VERSION ""

NS_ :

BS_:

BU_: Skylark_EV

BO_ 499 CCM_HU_Event_Info_Ack: 8 Vector__XXX
 SG_ CCmHuRearBlowerSwitchAck2 : 23|2@0+ (1,0) [0|3] ""  Skylark_EV
 SG_ CCmHuCtrlPnlSwitchAck : 8|1@0+ (1,0) [0|1] ""  Skylark_EV
 SG_ CCmHuExpressCoolSwitchAck : 9|1@0+ (1,0) [0|1] ""  Skylark_EV
 SG_ CCmHuRearBlowerSwitchAck : 10|1@0+ (1,0) [0|1] ""  Skylark_EV
 SG_ CCmHuFanSpdAck : 0|1@0+ (1,0) [0|1] ""  Skylark_EV
 SG_ CCmHuDistribSwitchAck : 1|1@0+ (1,0) [0|1] ""  Skylark_EV
 SG_ CCmHuMaxDefrstSwitchAck : 2|1@0+ (1,0) [0|1] ""  Skylark_EV
 SG_ CCmHuEconModeSwitchAck : 3|1@0+ (1,0) [0|1] ""  Skylark_EV
 SG_ CCmHuAutoSwitchAck : 4|1@0+ (1,0) [0|1] ""  Skylark_EV
 SG_ CCmHuRearDefogSwitchAck : 5|1@0+ (1,0) [0|1] ""  Skylark_EV
 SG_ CCmHuAirConCompSwitchAck : 6|1@0+ (1,0) [0|1] ""  Skylark_EV
 SG_ CCmHuErrAck : 7|1@0+ (1,0) [0|1] ""  Skylark_EV
 SG_ CCmHuTempWhlAck : 11|1@0+ (1,0) [0|1] ""  Skylark_EV
 SG_ CCmHuFreshAirRecircSwitchAck : 12|1@0+ (1,0) [0|1] ""  Skylark_EV
 SG_ CCmHuDualModeSwitchAck : 13|1@0+ (1,0) [0|1] ""  Skylark_EV
 SG_ CCmHuTempWhlPassAck : 14|1@0+ (1,0) [0|1] ""  Skylark_EV
 SG_ CCmHuTempWhlDrvrAck : 15|1@0+ (1,0) [0|1] ""  Skylark_EV

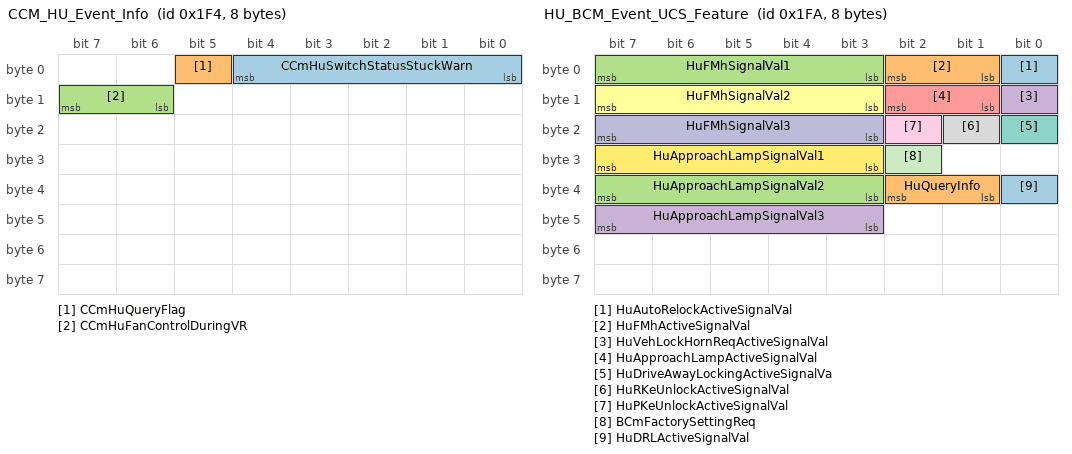
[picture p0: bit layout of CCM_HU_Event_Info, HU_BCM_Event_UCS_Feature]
BO_ 500 CCM_HU_Event_Info: 8 Vector__XXX
 SG_ CCmHuSwitchStatusStuckWarn : 4|5@0+ (1,0) [0|31] ""  Skylark_EV
 SG_ CCmHuQueryFlag : 5|1@0+ (1,0) [0|1] ""  Skylark_EV
 SG_ CCmHuFanControlDuringVR : 15|2@0+ (1,0) [0|3] ""  Skylark_EV

BO_ 504 BCM_HU_Event_UCS_Feature: 8 Vector__XXX
 SG_ BCmAutoRelockActiveSignalVal : 0|1@0+ (1,0) [0|1] ""  Skylark_EV
 SG_ BCmFMhActiveSignalVal : 2|2@0+ (1,0) [0|3] ""  Skylark_EV
 SG_ BCmFMhSignalVal1 : 7|5@0+ (10,0) [0|310] "Sec"  Skylark_EV
 SG_ BCmVehLockHornReqActiveSignalVal : 8|1@0+ (1,0) [0|1] ""  Skylark_EV
 SG_ BCmApproachLampActiveSignalVal : 10|2@0+ (1,0) [0|3] ""  Skylark_EV
 SG_ BCmFMhSignalVal2 : 15|5@0+ (10,0) [0|310] "Sec"  Skylark_EV
 SG_ BCmDriveAwayLockingActiveSignalV : 16|1@0+ (1,0) [0|1] ""  Skylark_EV
 SG_ BCmRKeUnlockState : 17|1@0+ (1,0) [0|1] ""  Skylark_EV
 SG_ BCmPKeUnlockState : 18|1@0+ (1,0) [0|1] ""  Skylark_EV
 SG_ BCmFMhSignalVal3 : 23|5@0+ (10,0) [0|310] "Sec"  Skylark_EV
 SG_ BCmAutoRelockState : 24|1@0+ (1,0) [0|1] ""  Skylark_EV
 SG_ BCmFMhState : 25|1@0+ (1,0) [0|1] ""  Skylark_EV
 SG_ BCmUCsState : 26|1@0+ (1,0) [0|1] ""  Skylark_EV
 SG_ BCmApproachLampSignalVal1 : 31|5@0+ (10,0) [0|310] "Sec"  Skylark_EV
 SG_ BCmPKeUnlockActiveSignalVal : 32|1@0+ (1,0) [0|1] ""  Skylark_EV
 SG_ BCmRKeUnlockActiveSignalVal : 33|1@0+ (1,0) [0|1] ""  Skylark_EV
 SG_ BCmDriveAwayLockingState : 34|1@0+ (1,0) [0|1] ""  Skylark_EV
 SG_ BCmApproachLampSignalVal2 : 39|5@0+ (10,0) [0|310] "Sec"  Skylark_EV
 SG_ AmbLightModeIllumOnHu : 40|1@0+ (1,0) [0|1] ""  Skylark_EV
 SG_ BCmApproachLampState : 41|1@0+ (1,0) [0|1] ""  Skylark_EV
 SG_ BCmVehLockHornReqState : 42|1@0+ (1,0) [0|1] ""  Skylark_EV
 SG_ BCmApproachLampSignalVal3 : 47|5@0+ (10,0) [0|310] "Sec"  Skylark_EV
 SG_ BCmDRLActiveSignalVal : 51|1@0+ (1,0) [0|1] ""  Skylark_EV
 SG_ BCmDRLState : 52|1@0+ (1,0) [0|1] ""  Skylark_EV
 SG_ BCmMoodLightState : 53|1@0+ (1,0) [0|1] ""  Skylark_EV
 SG_ BCmUcsData : 55|2@0+ (1,0) [0|3] ""  Skylark_EV

BO_ 505 BCM_HU_Event_Mood_Light_Feature: 8 Vector__XXX
 SG_ BCmMoodLightAllAreaActiveValue : 0|1@0+ (1,0) [0|1] ""  Skylark_EV
 SG_ BCmMoodLightIllumSelActiveVal : 3|3@0+ (1,0) [0|7] ""  Skylark_EV
 SG_ BCmMoodLightActiveColour : 7|4@0+ (1,0) [0|15] ""  Skylark_EV
 SG_ BCmMoodLightRearAreaActiveValue : 8|1@0+ (1,0) [0|1] ""  Skylark_EV
 SG_ BCmMoodLightFrontRHAreaActiveVal : 9|1@0+ (1,0) [0|1] ""  Skylark_EV
 SG_ BCmMoodLightFloorConsoleAreaActi : 10|1@0+ (1,0) [0|1] ""  Skylark_EV
 SG_ BCmMoodLightData : 12|2@0+ (1,0) [0|3] ""  Skylark_EV
 SG_ BCmMoodLightIllumPossibleLevels : 15|3@0+ (1,0) [0|7] ""  Skylark_EV
 SG_ BCmMoodLightHotMagentaColorSelOn : 16|1@0+ (1,0) [0|1] ""  Skylark_EV
 SG_ BCmMoodLightGoldYellowColorSelOn : 17|1@0+ (1,0) [0|1] ""  Skylark_EV
 SG_ BCmMoodLightFrenchLimeColorSelOn : 18|1@0+ (1,0) [0|1] ""  Skylark_EV
 SG_ BCmMoodLightFrontLHAreaActiveVal : 19|1@0+ (1,0) [0|1] ""  Skylark_EV
 SG_ BCmMoodLightPossibleModes : 21|2@0+ (1,0) [0|3] ""  Skylark_EV
 SG_ BCmMoodLightActiveModeValue : 23|2@0+ (1,0) [0|3] ""  Skylark_EV
 SG_ BCmMoodLightPolarBrightWhiteColo : 24|1@0+ (1,0) [0|1] ""  Skylark_EV
 SG_ BCmMoodLightAeroBlueColorSelOnHU : 25|1@0+ (1,0) [0|1] ""  Skylark_EV
 SG_ BCmMoodLightPurpleColorSelOnHU : 26|1@0+ (1,0) [0|1] ""  Skylark_EV
 SG_ BCmMoodLightFluorescentGreenColo : 27|1@0+ (1,0) [0|1] ""  Skylark_EV
 SG_ BCmMoodLightCyanBlueColorSelOnHU : 28|1@0+ (1,0) [0|1] ""  Skylark_EV
 SG_ BCmMoodLightCoolBlueColorSelOnHU : 29|1@0+ (1,0) [0|1] ""  Skylark_EV
 SG_ BCmMoodLightIvoryOFFWhiteColorSe : 30|1@0+ (1,0) [0|1] ""  Skylark_EV
 SG_ BCmMoodLightIceBlueColorSelOnHU : 31|1@0+ (1,0) [0|1] ""  Skylark_EV
 SG_ BCmMoodLightTuscanRedColorSelOnH : 32|1@0+ (1,0) [0|1] ""  Skylark_EV
 SG_ BCmMoodLightTealGreenColorSelOnH : 33|1@0+ (1,0) [0|1] ""  Skylark_EV
 SG_ BCmMoodLightRubyRedColorSelOnHU : 34|1@0+ (1,0) [0|1] ""  Skylark_EV
 SG_ BCmMoodLightOrangeColorSelOnHU : 35|1@0+ (1,0) [0|1] ""  Skylark_EV
 SG_ BCmMoodLightPurpleTaupeColorSelO : 36|1@0+ (1,0) [0|1] ""  Skylark_EV
 SG_ BCmMoodLightLocationSel : 37|1@0+ (1,0) [0|1] ""  Skylark_EV
 SG_ BCmMoodLightAllAreaSelOnHU : 38|1@0+ (1,0) [0|1] ""  Skylark_EV
 SG_ BCmMoodLightFrontLHAreaSelOnHU : 39|1@0+ (1,0) [0|1] ""  Skylark_EV
 SG_ BCmMoodLightRearAreaSelOnHU : 40|1@0+ (1,0) [0|1] ""  Skylark_EV
 SG_ BCmMoodLightFloorConsoleAreaSelO : 41|1@0+ (1,0) [0|1] ""  Skylark_EV
 SG_ BCmMoodLightState : 42|1@0+ (1,0) [0|1] ""  Skylark_EV
 SG_ BCmMoodLightFrontRHAreaSelOnHU : 43|1@0+ (1,0) [0|1] ""  Skylark_EV

BO_ 506 HU_BCM_Event_UCS_Feature: 8 Skylark_EV
 SG_ HuAutoRelockActiveSignalVal : 0|1@0+ (1,0) [0|1] "" Vector__XXX
 SG_ HuFMhActiveSignalVal : 2|2@0+ (1,0) [0|3] "" Vector__XXX
 SG_ HuFMhSignalVal1 : 7|5@0+ (10,0) [0|310] "Sec" Vector__XXX
 SG_ HuVehLockHornReqActiveSignalVal : 8|1@0+ (1,0) [0|1] "" Vector__XXX
 SG_ HuApproachLampActiveSignalVal : 10|2@0+ (1,0) [0|3] "" Vector__XXX
 SG_ HuFMhSignalVal2 : 15|5@0+ (10,0) [0|310] "Sec" Vector__XXX
 SG_ HuDriveAwayLockingActiveSignalVa : 16|1@0+ (1,0) [0|1] "" Vector__XXX
 SG_ HuRKeUnlockActiveSignalVal : 17|1@0+ (1,0) [0|1] "" Vector__XXX
 SG_ HuPKeUnlockActiveSignalVal : 18|1@0+ (1,0) [0|1] "" Vector__XXX
 SG_ HuFMhSignalVal3 : 23|5@0+ (10,0) [0|310] "Sec" Vector__XXX
 SG_ BCmFactorySettingReq : 26|1@0+ (1,0) [0|1] "" Vector__XXX
 SG_ HuApproachLampSignalVal1 : 31|5@0+ (10,0) [0|310] "Sec" Vector__XXX
 SG_ HuDRLActiveSignalVal : 32|1@0+ (1,0) [0|1] "" Vector__XXX
 SG_ HuQueryInfo : 34|2@0+ (1,0) [0|3] "" Vector__XXX
 SG_ HuApproachLampSignalVal2 : 39|5@0+ (10,0) [0|310] "Sec" Vector__XXX
 SG_ HuApproachLampSignalVal3 : 47|5@0+ (10,0) [0|310] "Sec" Vector__XXX

BO_ 508 HU_BCM_Event_Mood_Light_Feature: 8 Skylark_EV
 SG_ HuMoodLightAllAreaActiveValue : 0|1@0+ (1,0) [0|1] "" Vector__XXX
 SG_ HuMoodLightIllumSelActiveValue : 3|3@0+ (1,0) [0|7] "" Vector__XXX
 SG_ HuMoodLightActiveColourValue : 7|4@0+ (1,0) [0|15] "" Vector__XXX
 SG_ HuMoodLightRearAreaActiveValue : 8|1@0+ (1,0) [0|1] "" Vector__XXX
 SG_ HuMoodLightFrontRHAreaActiveValu : 9|1@0+ (1,0) [0|1] "" Vector__XXX
 SG_ HuMoodLightFloorConsoleAreaActiv : 10|1@0+ (1,0) [0|1] "" Vector__XXX
 SG_ HuMoodLightData : 12|2@0+ (1,0) [0|3] "" Vector__XXX
 SG_ HuMoodLightIllumPossibleLevels : 15|3@0+ (1,0) [0|7] "" Vector__XXX
 SG_ HuMoodLightHotMagentaColorSelOnH : 16|1@0+ (1,0) [0|1] "" Vector__XXX
 SG_ HuMoodLightGoldYellowColorSelOnH : 17|1@0+ (1,0) [0|1] "" Vector__XXX
 SG_ HuMoodLightFrenchLimeColorSelOnH : 18|1@0+ (1,0) [0|1] "" Vector__XXX
 SG_ HuMoodLightFrontLHAreaActiveValu : 19|1@0+ (1,0) [0|1] "" Vector__XXX
 SG_ HuMoodLightPossibleModes : 21|2@0+ (1,0) [0|3] "" Vector__XXX
 SG_ HuMoodLightActiveModeValue : 23|2@0+ (1,0) [0|3] "" Vector__XXX
 SG_ HuMoodLightPolarBrightWhiteColor : 24|1@0+ (1,0) [0|1] "" Vector__XXX
 SG_ HuMoodLightAeroBlueColorSelOnHU : 25|1@0+ (1,0) [0|1] "" Vector__XXX
 SG_ HuMoodLightPurpleColorSelOnHU : 26|1@0+ (1,0) [0|1] "" Vector__XXX
 SG_ HuMoodLightFluorescentGreenColor : 27|1@0+ (1,0) [0|1] "" Vector__XXX
 SG_ HuMoodLightCyanBlueColorSelOnHU : 28|1@0+ (1,0) [0|1] "" Vector__XXX
 SG_ HuMoodLightCoolBlueColorSelOnHU : 29|1@0+ (1,0) [0|1] "" Vector__XXX
 SG_ HuMoodLightIvoryOFFWhiteColorSel : 30|1@0+ (1,0) [0|1] "" Vector__XXX
 SG_ HuMoodLightIceBlueColorSelOnHU : 31|1@0+ (1,0) [0|1] "" Vector__XXX
 SG_ HuMoodLightTuscanRedColorSelOnHU : 32|1@0+ (1,0) [0|1] "" Vector__XXX
 SG_ HuMoodLightTealGreenColorSelOnHU : 33|1@0+ (1,0) [0|1] "" Vector__XXX
 SG_ HuMoodLightRubyRedColorSelOnHU : 34|1@0+ (1,0) [0|1] "" Vector__XXX
 SG_ HuMoodLightOrangeColorSelOnHU : 35|1@0+ (1,0) [0|1] "" Vector__XXX
 SG_ HuMoodLightPurpleTaupeSelOnHU : 36|1@0+ (1,0) [0|1] "" Vector__XXX

CM_ SG_ 499 CCmHuRearBlowerSwitchAck2 "Acknowledges the display update";
CM_ SG_ 499 CCmHuCtrlPnlSwitchAck "Acknowledges the display update";
CM_ SG_ 499 CCmHuExpressCoolSwitchAck "Acknowledges the display update";
CM_ SG_ 499 CCmHuRearBlowerSwitchAck "Acknowledges the display update";
CM_ SG_ 499 CCmHuFanSpdAck "Acknowledges the display update";
CM_ SG_ 499 CCmHuDistribSwitchAck "Acknowledges the display update";
CM_ SG_ 499 CCmHuMaxDefrstSwitchAck "Acknowledges the display update";
CM_ SG_ 499 CCmHuEconModeSwitchAck "Acknowledges the display update";
CM_ SG_ 499 CCmHuAutoSwitchAck "Acknowledges the display update";
CM_ SG_ 499 CCmHuRearDefogSwitchAck "Acknowledges the display update";
CM_ SG_ 499 CCmHuAirConCompSwitchAck "Acknowledges the display update";
CM_ SG_ 499 CCmHuErrAck "Acknowledges the display update";
CM_ SG_ 499 CCmHuTempWhlAck "Acknowledges the display update";
CM_ SG_ 499 CCmHuFreshAirRecircSwitchAck "Acknowledges the display update";
CM_ SG_ 499 CCmHuDualModeSwitchAck "Acknowledges the display update";
CM_ SG_ 499 CCmHuTempWhlPassAck "Acknowledges the display update";
CM_ SG_ 499 CCmHuTempWhlDrvrAck "Acknowledges the display update";
CM_ SG_ 500 CCmHuSwitchStatusStuckWarn "Indicates the button/s stuck status";
CM_ SG_ 500 CCmHuQueryFlag "Query the HU to send the missing frame";
CM_ SG_ 500 CCmHuFanControlDuringVR "To Control FAN speed during VR session";
CM_ SG_ 504 BCmAutoRelockActiveSignalVal "Active Value for Vehicle Auto Relock Feature";
CM_ SG_ 504 BCmFMhActiveSignalVal "Active value for Follow Me Home feature";
CM_ SG_ 504 BCmFMhSignalVal1 "1st Possible value for Follow Me Home Feature";
CM_ SG_ 504 BCmVehLockHornReqActiveSignalVal "Active Value for Vehicle Lock Horn Request feature";
CM_ SG_ 504 BCmApproachLampActiveSignalVal "Active value for Approach Lamp Active feature";
CM_ SG_ 504 BCmFMhSignalVal2 "2nd Possible value for Follow Me Home Feature";
CM_ SG_ 504 BCmDriveAwayLockingActiveSignalV "Active Value for Vehicle Drive Away Feature";
CM_ SG_ 504 BCmRKeUnlockState "Vehicle unlock with RKE Feature - Enable / Disable";
CM_ SG_ 504 BCmPKeUnlockState "Vehicle unlock with PKE Feature - Enable / Disable";
CM_ SG_ 504 BCmFMhSignalVal3 "3rd Possible value for Follow Me Home Feature";
CM_ SG_ 504 BCmAutoRelockState "Auto relock function Feature - Enable / Disable";
CM_ SG_ 504 BCmFMhState "Follow Me Home Feature - Enable / Disable";
CM_ SG_ 504 BCmUCsState "User customisation settings feature enable/disable parameter published by BCM";
CM_ SG_ 504 BCmApproachLampSignalVal1 "1st Possible value for Approach Lamp Feature";
CM_ SG_ 504 BCmPKeUnlockActiveSignalVal "Active Value for Vehicle Unlock with PKE Feature";
CM_ SG_ 504 BCmRKeUnlockActiveSignalVal "Active Value for Vehicle Unlock with RKE Feature";
CM_ SG_ 504 BCmDriveAwayLockingState "Drive away locking Feature - Enable / Disable";
CM_ SG_ 504 BCmApproachLampSignalVal2 "2nd Possible value for Approach Lamp Feature";
CM_ SG_ 504 AmbLightModeIllumOnHu "Mode and Illumination Display on HU send by BCM";
CM_ SG_ 504 BCmApproachLampState "Approach lamp Feature - Enable / Disable";
CM_ SG_ 504 BCmVehLockHornReqState "Horn request on vehicle lock Feature - Enable / Disable";
CM_ SG_ 504 BCmApproachLampSignalVal3 "3rd Possible value for Approach Lamp Feature";
CM_ SG_ 504 BCmDRLActiveSignalVal "Active Value for DRL Feature";
CM_ SG_ 504 BCmDRLState "DRL Feature - Enable / Disable";
CM_ SG_ 504 BCmMoodLightState "Current state of Mood Lighting from BCM to HU.";
CM_ SG_ 504 BCmUcsData "BCM sends UCS config data or give acknowledgement to HU.";
CM_ SG_ 505 BCmMoodLightAllAreaActiveValue "Current status of All area location selection from BCM to HU";
CM_ SG_ 505 BCmMoodLightIllumSelActiveVal "Current mood light illumination from BCM to HU";
CM_ SG_ 505 BCmMoodLightActiveColour "Mood light Active Colour from BCM to HU";
CM_ SG_ 505 BCmMoodLightRearAreaActiveValue "Current status of Rear area location selection from BCM to HU";
CM_ SG_ 505 BCmMoodLightFrontRHAreaActiveVal "Current status of driver area location selection from BCM to HU";
CM_ SG_ 505 BCmMoodLightFloorConsoleAreaActi "Current status of Floor area location selection from BCM to HU";
CM_ SG_ 505 BCmMoodLightData "BCM sends Mood light data frame or give acknowledgement to HU.";
CM_ SG_ 505 BCmMoodLightIllumPossibleLevels "Mood Light Number of illumination levels  to be displayed on HU send by BCM";
CM_ SG_ 505 BCmMoodLightHotMagentaColorSelOn "Mood light Hot Magenta colour selection on HU sent by BCM";
CM_ SG_ 505 BCmMoodLightGoldYellowColorSelOn "Mood light Gold Yellow colour selection on HU sent by BCM";
CM_ SG_ 505 BCmMoodLightFrenchLimeColorSelOn "Mood light French Lime colour selection on HU sent by BCM";
CM_ SG_ 505 BCmMoodLightFrontLHAreaActiveVal "Current status of co-driver area location selection from BCM to HU";
CM_ SG_ 505 BCmMoodLightPossibleModes "Mood light Possible Modes from BCM to HU";
CM_ SG_ 505 BCmMoodLightActiveModeValue "Mood light active mode from BCM to HU
";
CM_ SG_ 505 BCmMoodLightPolarBrightWhiteColo "Mood light polar colour selection on HU sent by BCM";
CM_ SG_ 505 BCmMoodLightAeroBlueColorSelOnHU "Mood light Aero Blue colour selection on HU sent by BCM";
CM_ SG_ 505 BCmMoodLightPurpleColorSelOnHU "Mood light purple colour selection on HU sent by BCM";
CM_ SG_ 505 BCmMoodLightFluorescentGreenColo "Mood lightFluroscent Green colour selection on HU sent by BCM";
CM_ SG_ 505 BCmMoodLightCyanBlueColorSelOnHU "Mood light Cyan Blue colour selection on HU sent by BCM";
CM_ SG_ 505 BCmMoodLightCoolBlueColorSelOnHU "Mood light Cool Blue color selection on HU sent by BCM";
CM_ SG_ 505 BCmMoodLightIvoryOFFWhiteColorSe "Mood light Ivory colour selection on HU sent by BCM";
CM_ SG_ 505 BCmMoodLightIceBlueColorSelOnHU "Mood light Ice Blue color selection on HU sent by BCM";
CM_ SG_ 505 BCmMoodLightTuscanRedColorSelOnH "Mood light Tuscan Red colour selection on HU sent by BCM";
CM_ SG_ 505 BCmMoodLightTealGreenColorSelOnH "Mood light Teal Green colour selection on HU sent by BCM";
CM_ SG_ 505 BCmMoodLightRubyRedColorSelOnHU "Mood light Ruby Red colour selection on HU sent by BCM";
CM_ SG_ 505 BCmMoodLightOrangeColorSelOnHU "Mood light Orange colour selection on HU sent by BCM";
CM_ SG_ 505 BCmMoodLightPurpleTaupeColorSelO "Mood light Purple Taupe colour selection on HU sent by BCM";
CM_ SG_ 505 BCmMoodLightLocationSel "Mood Lighting Location selection on HU";
CM_ SG_ 505 BCmMoodLightAllAreaSelOnHU "Mood Light All area location selection on HU send by BCM";
CM_ SG_ 505 BCmMoodLightFrontLHAreaSelOnHU "Mood Light co-driver area location selection on HU send by BCM";
CM_ SG_ 505 BCmMoodLightRearAreaSelOnHU "Mood Light Rear area location selection on HU send by BCM";
CM_ SG_ 505 BCmMoodLightFloorConsoleAreaSelO "Mood Light Floor Console area location selection on HU send by BCM";
CM_ SG_ 505 BCmMoodLightState "Current state of Mood Lighting from BCM to HU.";
CM_ SG_ 505 BCmMoodLightFrontRHAreaSelOnHU "Mood Light driver area location selection on HU send by BCM";
CM_ SG_ 506 HuAutoRelockActiveSignalVal "Active Value for Vehicle Auto Relock Feature";
CM_ SG_ 506 HuFMhActiveSignalVal "Active value for Follow Me Home feature";
CM_ SG_ 506 HuFMhSignalVal1 "1st Possible value for Follow Me Home Feature";
CM_ SG_ 506 HuVehLockHornReqActiveSignalVal "Active Value for Vehicle Lock Horn Request feature";
CM_ SG_ 506 HuApproachLampActiveSignalVal "Active value for Approach Lamp Active feature";
CM_ SG_ 506 HuFMhSignalVal2 "2ND Possible value for Follow Me Home Feature";
CM_ SG_ 506 HuDriveAwayLockingActiveSignalVa "Active Value for Vehicle Drive Away Feature";
CM_ SG_ 506 HuRKeUnlockActiveSignalVal "Active Value for Vehicle Unlock with RKE Feature";
CM_ SG_ 506 HuPKeUnlockActiveSignalVal "Active Value for Vehicle Unlock with PKE Feature";
CM_ SG_ 506 HuFMhSignalVal3 "3rd Possible value for Follow Me Home Feature";
CM_ SG_ 506 BCmFactorySettingReq "Request from HU to BCM to restore factory settings.";
CM_ SG_ 506 HuApproachLampSignalVal1 "1st Possible value for Approach Lamp Feature";
CM_ SG_ 506 HuDRLActiveSignalVal "Active Value for DRL  Feature";
CM_ SG_ 506 HuQueryInfo "HU ask BCM to send UCS values when not received after IGN ON.";
CM_ SG_ 506 HuApproachLampSignalVal2 "2nd Possible value for Approach Lamp Feature";
CM_ SG_ 506 HuApproachLampSignalVal3 "3rd Possible value for Approach Lamp Feature";
CM_ BO_ 508 "Event Message from HU to BCM for Mood Lighting feature";
CM_ SG_ 508 HuMoodLightAllAreaActiveValue "Current status of All area location selection from HU to BCM";
CM_ SG_ 508 HuMoodLightIllumSelActiveValue "Current Mood light illumination active value from HU to BCM";
CM_ SG_ 508 HuMoodLightActiveColourValue "Current Mood Light active value from HU to BCM";
CM_ SG_ 508 HuMoodLightRearAreaActiveValue "Current status of Rear area location selection from HU to BCM";
CM_ SG_ 508 HuMoodLightFrontRHAreaActiveValu "Current status of Driver area location selection from HU to BCM";
CM_ SG_ 508 HuMoodLightFloorConsoleAreaActiv "Current status of Floor Console area location selection from HU to BCM";
CM_ SG_ 508 HuMoodLightData "HU sends Mood Light Data frame or give acknowledgement to HU";
CM_ SG_ 508 HuMoodLightIllumPossibleLevels "Mood light number of illumination levels to be send by HU to BCM";
CM_ SG_ 508 HuMoodLightHotMagentaColorSelOnH "Mood light Hot Magenta colour selection on HU sent by HU";
CM_ SG_ 508 HuMoodLightGoldYellowColorSelOnH "Mood light Gold Yellow colour selection on HU sent by HU";
CM_ SG_ 508 HuMoodLightFrenchLimeColorSelOnH "Mood light French Lime colour selection on HU sent by HU";
CM_ SG_ 508 HuMoodLightFrontLHAreaActiveValu "Current status of Co-Driver area location selection from HU to BCM";
CM_ SG_ 508 HuMoodLightPossibleModes "Mood light possible modes from HU to BCM";
CM_ SG_ 508 HuMoodLightActiveModeValue "Mood light active mode from HU to BCM
";
CM_ SG_ 508 HuMoodLightPolarBrightWhiteColor "Mood light polar colour selection on HU sent by HU";
CM_ SG_ 508 HuMoodLightAeroBlueColorSelOnHU "Mood light Aero Blue colour selection on HU sent by HU";
CM_ SG_ 508 HuMoodLightPurpleColorSelOnHU "Mood light purple colour selection on HU sent by HU";
CM_ SG_ 508 HuMoodLightFluorescentGreenColor "Mood light Fluroscent colour selection on HU sent by HU";
CM_ SG_ 508 HuMoodLightCyanBlueColorSelOnHU "Mood light Cyan Blue colour selection on HU sent by HU";
CM_ SG_ 508 HuMoodLightCoolBlueColorSelOnHU "Mood light Cool Blue colour selection on HU sent by HU";
CM_ SG_ 508 HuMoodLightIvoryOFFWhiteColorSel "Mood light Ivory colour selection on HU sent by HU";
CM_ SG_ 508 HuMoodLightIceBlueColorSelOnHU "Mood light Ice Blue colour selection on HU sent by HU";
CM_ SG_ 508 HuMoodLightTuscanRedColorSelOnHU "Mood light Tuscan Red colour selection on HU sent by HU";
CM_ SG_ 508 HuMoodLightTealGreenColorSelOnHU "Mood light Teal Green colour selection on HU sent by HU";
CM_ SG_ 508 HuMoodLightRubyRedColorSelOnHU "Mood light ruby colour selection on HU sent by HU";
CM_ SG_ 508 HuMoodLightOrangeColorSelOnHU "Mood light Orange colour selection on HU sent by HU";
CM_ SG_ 508 HuMoodLightPurpleTaupeSelOnHU "Mood light Purple Taupe colour selection on HU sent by HU";
BA_DEF_ SG_  "Remarks" STRING ;
BA_DEF_ SG_  "NWM_WakeupAllowed" ENUM  "No","Yes";
BA_DEF_ SG_  "GenSigTimeoutTime_HU_Mid_X451" INT 0 65535;
BA_DEF_ SG_  "GenSigTimeoutTime_HU_High_X451" INT 0 65535;
BA_DEF_ SG_  "GenSigTimeoutTime_HU_B" INT 0 65535;
BA_DEF_ SG_  "GenSigTimeoutTime_HU_A" INT 0 65535;
BA_DEF_ SG_  "GenSigTimeoutTime_BCM_Mid" INT 0 65535;
BA_DEF_ SG_  "GenSigTimeoutMsg_HU_Mid_X451" INT 0 65535;
BA_DEF_ SG_  "GenSigTimeoutMsg_HU_High_X451" INT 0 65535;
BA_DEF_ SG_  "GenSigTimeoutMsg_HU_B" INT 0 65535;
BA_DEF_ SG_  "GenSigTimeoutMsg_HU_A" INT 0 65535;
BA_DEF_ SG_  "GenSigStartValue" INT 0 0;
BA_DEF_ SG_  "GenSigSendType" ENUM  "Cyclic","OnWrite","OnWriteWithRepetition","OnChange","OnChangeWithRepetition","IfActive","IfActiveWithRepetition","NoSigSendType","NotUsed","NotUsed","NotUsed","NotUsed","NotUsed";
BA_DEF_ SG_  "GenSigInactiveValue" INT 0 0;
BA_DEF_ SG_  "GenSigEnvVarType" ENUM  "int","float","undef";
BA_DEF_ SG_  "GenSigCycleTimeActive" INT 0 0;
BA_DEF_ SG_  "GenSigCycleTime" INT 0 0;
BA_DEF_ SG_  "GenSigTimeoutMsg_HU_High_X445" INT 0 65535;
BA_DEF_ SG_  "GenSigTimeoutMsg_HU_Mid_X445" INT 0 65535;
BA_DEF_ SG_  "GenSigTimeoutTime_HU_High_X445" INT 0 65535;
BA_DEF_ SG_  "GenSigTimeoutTime_HU_Mid_X445" INT 0 65535;
BA_DEF_ SG_  "GenSigTimeoutMsg_IVI" INT 0 65535;
BA_DEF_ SG_  "GenSigTimeoutTime_IVI" INT 0 65535;
BA_DEF_ BO_  "NmMessage" ENUM  "no","yes";
BA_DEF_ BO_  "NmAsrMessage" ENUM  "<n.a.>","No","Yes";
BA_DEF_ BO_  "MessageTimeout" INT 0 65535;
BA_DEF_ BO_  "GenMsgStartDelayTime" INT 0 0;
BA_DEF_ BO_  "GenMsgSendType" ENUM  "Cyclic","NotUsed","NotUsed","NotUsed","NotUsed","NotUsed","NotUsed","IfActive","NoMsgSendType","NotUsed";
BA_DEF_ BO_  "GenMsgNrOfRepetition" INT 0 0;
BA_DEF_ BO_  "GenMsgILSupport" ENUM  "No","Yes";
BA_DEF_ BO_  "GenMsgDelayTime" INT 0 0;
BA_DEF_ BO_  "GenMsgCycleTimeFast" INT 0 0;
BA_DEF_ BO_  "GenMsgCycleTime" INT 0 0;
BA_DEF_ BO_  "DiagUudtResponse" ENUM  "false","true";
BA_DEF_ BO_  "DiagUsdtResponse" ENUM  "false","true";
BA_DEF_ BO_  "DiagState" ENUM  "No","Yes";
BA_DEF_ BO_  "DiagResponse" ENUM  "No","Yes";
BA_DEF_ BO_  "DiagRequest" ENUM  "No","Yes";
BA_DEF_ BO_  "MsgType" ENUM  "Application","NM","NMH";
BA_DEF_ SG_  "SystemSignalLongSymbol" STRING ;
BA_DEF_DEF_  "Remarks" "null";
BA_DEF_DEF_  "NWM_WakeupAllowed" "No";
BA_DEF_DEF_  "GenSigTimeoutTime_HU_Mid_X451" 500;
BA_DEF_DEF_  "GenSigTimeoutTime_HU_High_X451" 500;
BA_DEF_DEF_  "GenSigTimeoutTime_HU_B" 500;
BA_DEF_DEF_  "GenSigTimeoutTime_HU_A" 500;
BA_DEF_DEF_  "GenSigTimeoutTime_BCM_Mid" 0;
BA_DEF_DEF_  "GenSigTimeoutMsg_HU_Mid_X451" 500;
BA_DEF_DEF_  "GenSigTimeoutMsg_HU_High_X451" 500;
BA_DEF_DEF_  "GenSigTimeoutMsg_HU_B" 500;
BA_DEF_DEF_  "GenSigTimeoutMsg_HU_A" 500;
BA_DEF_DEF_  "GenSigStartValue" 0;
BA_DEF_DEF_  "GenSigSendType" "Cyclic";
BA_DEF_DEF_  "GenSigInactiveValue" 0;
BA_DEF_DEF_  "GenSigEnvVarType" "undef";
BA_DEF_DEF_  "GenSigCycleTimeActive" 0;
BA_DEF_DEF_  "GenSigCycleTime" 0;
BA_DEF_DEF_  "GenSigTimeoutMsg_HU_High_X445" 500;
BA_DEF_DEF_  "GenSigTimeoutMsg_HU_Mid_X445" 500;
BA_DEF_DEF_  "GenSigTimeoutTime_HU_High_X445" 500;
BA_DEF_DEF_  "GenSigTimeoutTime_HU_Mid_X445" 500;
BA_DEF_DEF_  "GenSigTimeoutMsg_IVI" 500;
BA_DEF_DEF_  "GenSigTimeoutTime_IVI" 500;
BA_DEF_DEF_  "NmMessage" "no";
BA_DEF_DEF_  "NmAsrMessage" "<n.a.>";
BA_DEF_DEF_  "MessageTimeout" 500;
BA_DEF_DEF_  "GenMsgStartDelayTime" 0;
BA_DEF_DEF_  "GenMsgSendType" "Cyclic";
BA_DEF_DEF_  "GenMsgNrOfRepetition" 0;
BA_DEF_DEF_  "GenMsgILSupport" "Yes";
BA_DEF_DEF_  "GenMsgDelayTime" 0;
BA_DEF_DEF_  "GenMsgCycleTimeFast" 0;
BA_DEF_DEF_  "GenMsgCycleTime" 0;
BA_DEF_DEF_  "DiagUudtResponse" "false";
BA_DEF_DEF_  "DiagUsdtResponse" "false";
BA_DEF_DEF_  "DiagState" "No";
BA_DEF_DEF_  "DiagResponse" "No";
BA_DEF_DEF_  "DiagRequest" "No";
BA_DEF_DEF_  "MsgType" "Application";
BA_DEF_DEF_  "SystemSignalLongSymbol" "";
BA_ "MessageTimeout" BO_ 499 0;
BA_ "GenMsgSendType" BO_ 499 8;
BA_ "MessageTimeout" BO_ 500 0;
BA_ "GenMsgSendType" BO_ 500 8;
BA_ "MessageTimeout" BO_ 504 0;
BA_ "GenMsgSendType" BO_ 504 8;
BA_ "MessageTimeout" BO_ 505 0;
BA_ "GenMsgSendType" BO_ 505 8;
BA_ "MessageTimeout" BO_ 506 0;
BA_ "GenMsgSendType" BO_ 506 8;
BA_ "MessageTimeout" BO_ 508 0;
BA_ "GenMsgSendType" BO_ 508 8;
BA_ "GenSigTimeoutTime_HU_Mid_X451" SG_ 499 CCmHuRearBlowerSwitchAck2 0;
BA_ "GenSigTimeoutTime_HU_High_X451" SG_ 499 CCmHuRearBlowerSwitchAck2 0;
BA_ "GenSigTimeoutTime_HU_B" SG_ 499 CCmHuRearBlowerSwitchAck2 0;
BA_ "GenSigTimeoutTime_HU_A" SG_ 499 CCmHuRearBlowerSwitchAck2 0;
BA_ "GenSigTimeoutMsg_HU_Mid_X451" SG_ 499 CCmHuRearBlowerSwitchAck2 0;
BA_ "GenSigTimeoutMsg_HU_High_X451" SG_ 499 CCmHuRearBlowerSwitchAck2 0;
BA_ "GenSigTimeoutMsg_HU_B" SG_ 499 CCmHuRearBlowerSwitchAck2 0;
BA_ "GenSigTimeoutMsg_HU_A" SG_ 499 CCmHuRearBlowerSwitchAck2 0;
BA_ "GenSigSendType" SG_ 499 CCmHuRearBlowerSwitchAck2 1;
BA_ "GenSigTimeoutMsg_HU_High_X445" SG_ 499 CCmHuRearBlowerSwitchAck2 0;
BA_ "GenSigTimeoutMsg_HU_Mid_X445" SG_ 499 CCmHuRearBlowerSwitchAck2 0;
BA_ "GenSigTimeoutTime_HU_High_X445" SG_ 499 CCmHuRearBlowerSwitchAck2 0;
BA_ "GenSigTimeoutTime_HU_Mid_X445" SG_ 499 CCmHuRearBlowerSwitchAck2 0;
BA_ "GenSigTimeoutMsg_IVI" SG_ 499 CCmHuRearBlowerSwitchAck2 0;
BA_ "GenSigTimeoutTime_IVI" SG_ 499 CCmHuRearBlowerSwitchAck2 0;
BA_ "GenSigTimeoutTime_HU_Mid_X451" SG_ 499 CCmHuCtrlPnlSwitchAck 0;
BA_ "GenSigTimeoutTime_HU_High_X451" SG_ 499 CCmHuCtrlPnlSwitchAck 0;
BA_ "GenSigTimeoutTime_HU_B" SG_ 499 CCmHuCtrlPnlSwitchAck 0;
BA_ "GenSigTimeoutTime_HU_A" SG_ 499 CCmHuCtrlPnlSwitchAck 0;
BA_ "GenSigTimeoutMsg_HU_Mid_X451" SG_ 499 CCmHuCtrlPnlSwitchAck 0;
BA_ "GenSigTimeoutMsg_HU_High_X451" SG_ 499 CCmHuCtrlPnlSwitchAck 0;
BA_ "GenSigTimeoutMsg_HU_B" SG_ 499 CCmHuCtrlPnlSwitchAck 0;
BA_ "GenSigTimeoutMsg_HU_A" SG_ 499 CCmHuCtrlPnlSwitchAck 0;
BA_ "GenSigSendType" SG_ 499 CCmHuCtrlPnlSwitchAck 1;
BA_ "GenSigTimeoutMsg_HU_High_X445" SG_ 499 CCmHuCtrlPnlSwitchAck 0;
BA_ "GenSigTimeoutMsg_HU_Mid_X445" SG_ 499 CCmHuCtrlPnlSwitchAck 0;
BA_ "GenSigTimeoutTime_HU_High_X445" SG_ 499 CCmHuCtrlPnlSwitchAck 0;
BA_ "GenSigTimeoutTime_HU_Mid_X445" SG_ 499 CCmHuCtrlPnlSwitchAck 0;
BA_ "GenSigTimeoutMsg_IVI" SG_ 499 CCmHuCtrlPnlSwitchAck 0;
BA_ "GenSigTimeoutTime_IVI" SG_ 499 CCmHuCtrlPnlSwitchAck 0;
BA_ "GenSigTimeoutTime_HU_Mid_X451" SG_ 499 CCmHuExpressCoolSwitchAck 0;
BA_ "GenSigTimeoutTime_HU_High_X451" SG_ 499 CCmHuExpressCoolSwitchAck 0;
BA_ "GenSigTimeoutTime_HU_B" SG_ 499 CCmHuExpressCoolSwitchAck 0;
BA_ "GenSigTimeoutTime_HU_A" SG_ 499 CCmHuExpressCoolSwitchAck 0;
BA_ "GenSigTimeoutMsg_HU_Mid_X451" SG_ 499 CCmHuExpressCoolSwitchAck 0;
BA_ "GenSigTimeoutMsg_HU_High_X451" SG_ 499 CCmHuExpressCoolSwitchAck 0;
BA_ "GenSigTimeoutMsg_HU_B" SG_ 499 CCmHuExpressCoolSwitchAck 0;
BA_ "GenSigTimeoutMsg_HU_A" SG_ 499 CCmHuExpressCoolSwitchAck 0;
BA_ "GenSigSendType" SG_ 499 CCmHuExpressCoolSwitchAck 1;
BA_ "GenSigTimeoutMsg_HU_High_X445" SG_ 499 CCmHuExpressCoolSwitchAck 0;
BA_ "GenSigTimeoutMsg_HU_Mid_X445" SG_ 499 CCmHuExpressCoolSwitchAck 0;
BA_ "GenSigTimeoutTime_HU_High_X445" SG_ 499 CCmHuExpressCoolSwitchAck 0;
BA_ "GenSigTimeoutTime_HU_Mid_X445" SG_ 499 CCmHuExpressCoolSwitchAck 0;
BA_ "GenSigTimeoutMsg_IVI" SG_ 499 CCmHuExpressCoolSwitchAck 0;
BA_ "GenSigTimeoutTime_IVI" SG_ 499 CCmHuExpressCoolSwitchAck 0;
BA_ "GenSigTimeoutTime_HU_Mid_X451" SG_ 499 CCmHuRearBlowerSwitchAck 0;
BA_ "GenSigTimeoutTime_HU_High_X451" SG_ 499 CCmHuRearBlowerSwitchAck 0;
BA_ "GenSigTimeoutTime_HU_B" SG_ 499 CCmHuRearBlowerSwitchAck 0;
BA_ "GenSigTimeoutTime_HU_A" SG_ 499 CCmHuRearBlowerSwitchAck 0;
BA_ "GenSigTimeoutMsg_HU_Mid_X451" SG_ 499 CCmHuRearBlowerSwitchAck 0;
BA_ "GenSigTimeoutMsg_HU_High_X451" SG_ 499 CCmHuRearBlowerSwitchAck 0;
BA_ "GenSigTimeoutMsg_HU_B" SG_ 499 CCmHuRearBlowerSwitchAck 0;
BA_ "GenSigTimeoutMsg_HU_A" SG_ 499 CCmHuRearBlowerSwitchAck 0;
BA_ "GenSigSendType" SG_ 499 CCmHuRearBlowerSwitchAck 1;
BA_ "GenSigTimeoutMsg_HU_High_X445" SG_ 499 CCmHuRearBlowerSwitchAck 0;
BA_ "GenSigTimeoutMsg_HU_Mid_X445" SG_ 499 CCmHuRearBlowerSwitchAck 0;
BA_ "GenSigTimeoutTime_HU_High_X445" SG_ 499 CCmHuRearBlowerSwitchAck 0;
BA_ "GenSigTimeoutTime_HU_Mid_X445" SG_ 499 CCmHuRearBlowerSwitchAck 0;
BA_ "GenSigTimeoutMsg_IVI" SG_ 499 CCmHuRearBlowerSwitchAck 0;
BA_ "GenSigTimeoutTime_IVI" SG_ 499 CCmHuRearBlowerSwitchAck 0;
BA_ "GenSigTimeoutTime_HU_Mid_X451" SG_ 499 CCmHuFanSpdAck 0;
BA_ "GenSigTimeoutTime_HU_High_X451" SG_ 499 CCmHuFanSpdAck 0;
BA_ "GenSigTimeoutTime_HU_B" SG_ 499 CCmHuFanSpdAck 0;
BA_ "GenSigTimeoutTime_HU_A" SG_ 499 CCmHuFanSpdAck 0;
BA_ "GenSigTimeoutMsg_HU_Mid_X451" SG_ 499 CCmHuFanSpdAck 0;
BA_ "GenSigTimeoutMsg_HU_High_X451" SG_ 499 CCmHuFanSpdAck 0;
BA_ "GenSigTimeoutMsg_HU_B" SG_ 499 CCmHuFanSpdAck 0;
BA_ "GenSigTimeoutMsg_HU_A" SG_ 499 CCmHuFanSpdAck 0;
BA_ "GenSigSendType" SG_ 499 CCmHuFanSpdAck 1;
BA_ "GenSigTimeoutMsg_HU_High_X445" SG_ 499 CCmHuFanSpdAck 0;
BA_ "GenSigTimeoutMsg_HU_Mid_X445" SG_ 499 CCmHuFanSpdAck 0;
BA_ "GenSigTimeoutTime_HU_High_X445" SG_ 499 CCmHuFanSpdAck 0;
BA_ "GenSigTimeoutTime_HU_Mid_X445" SG_ 499 CCmHuFanSpdAck 0;
BA_ "GenSigTimeoutMsg_IVI" SG_ 499 CCmHuFanSpdAck 0;
BA_ "GenSigTimeoutTime_IVI" SG_ 499 CCmHuFanSpdAck 0;
BA_ "GenSigTimeoutTime_HU_Mid_X451" SG_ 499 CCmHuDistribSwitchAck 0;
BA_ "GenSigTimeoutTime_HU_High_X451" SG_ 499 CCmHuDistribSwitchAck 0;
BA_ "GenSigTimeoutTime_HU_B" SG_ 499 CCmHuDistribSwitchAck 0;
BA_ "GenSigTimeoutTime_HU_A" SG_ 499 CCmHuDistribSwitchAck 0;
BA_ "GenSigTimeoutMsg_HU_Mid_X451" SG_ 499 CCmHuDistribSwitchAck 0;
BA_ "GenSigTimeoutMsg_HU_High_X451" SG_ 499 CCmHuDistribSwitchAck 0;
BA_ "GenSigTimeoutMsg_HU_B" SG_ 499 CCmHuDistribSwitchAck 0;
BA_ "GenSigTimeoutMsg_HU_A" SG_ 499 CCmHuDistribSwitchAck 0;
BA_ "GenSigSendType" SG_ 499 CCmHuDistribSwitchAck 1;
BA_ "GenSigTimeoutMsg_HU_High_X445" SG_ 499 CCmHuDistribSwitchAck 0;
BA_ "GenSigTimeoutMsg_HU_Mid_X445" SG_ 499 CCmHuDistribSwitchAck 0;
BA_ "GenSigTimeoutTime_HU_High_X445" SG_ 499 CCmHuDistribSwitchAck 0;
BA_ "GenSigTimeoutTime_HU_Mid_X445" SG_ 499 CCmHuDistribSwitchAck 0;
BA_ "GenSigTimeoutMsg_IVI" SG_ 499 CCmHuDistribSwitchAck 0;
BA_ "GenSigTimeoutTime_IVI" SG_ 499 CCmHuDistribSwitchAck 0;
BA_ "GenSigTimeoutTime_HU_Mid_X451" SG_ 499 CCmHuMaxDefrstSwitchAck 0;
BA_ "GenSigTimeoutTime_HU_High_X451" SG_ 499 CCmHuMaxDefrstSwitchAck 0;
BA_ "GenSigTimeoutTime_HU_B" SG_ 499 CCmHuMaxDefrstSwitchAck 0;
BA_ "GenSigTimeoutTime_HU_A" SG_ 499 CCmHuMaxDefrstSwitchAck 0;
BA_ "GenSigTimeoutMsg_HU_Mid_X451" SG_ 499 CCmHuMaxDefrstSwitchAck 0;
BA_ "GenSigTimeoutMsg_HU_High_X451" SG_ 499 CCmHuMaxDefrstSwitchAck 0;
BA_ "GenSigTimeoutMsg_HU_B" SG_ 499 CCmHuMaxDefrstSwitchAck 0;
BA_ "GenSigTimeoutMsg_HU_A" SG_ 499 CCmHuMaxDefrstSwitchAck 0;
BA_ "GenSigSendType" SG_ 499 CCmHuMaxDefrstSwitchAck 1;
BA_ "GenSigTimeoutMsg_HU_High_X445" SG_ 499 CCmHuMaxDefrstSwitchAck 0;
BA_ "GenSigTimeoutMsg_HU_Mid_X445" SG_ 499 CCmHuMaxDefrstSwitchAck 0;
BA_ "GenSigTimeoutTime_HU_High_X445" SG_ 499 CCmHuMaxDefrstSwitchAck 0;
BA_ "GenSigTimeoutTime_HU_Mid_X445" SG_ 499 CCmHuMaxDefrstSwitchAck 0;
BA_ "GenSigTimeoutMsg_IVI" SG_ 499 CCmHuMaxDefrstSwitchAck 0;
BA_ "GenSigTimeoutTime_IVI" SG_ 499 CCmHuMaxDefrstSwitchAck 0;
BA_ "GenSigTimeoutTime_HU_Mid_X451" SG_ 499 CCmHuEconModeSwitchAck 0;
BA_ "GenSigTimeoutTime_HU_High_X451" SG_ 499 CCmHuEconModeSwitchAck 0;
BA_ "GenSigTimeoutTime_HU_B" SG_ 499 CCmHuEconModeSwitchAck 0;
BA_ "GenSigTimeoutTime_HU_A" SG_ 499 CCmHuEconModeSwitchAck 0;
BA_ "GenSigTimeoutMsg_HU_Mid_X451" SG_ 499 CCmHuEconModeSwitchAck 0;
BA_ "GenSigTimeoutMsg_HU_High_X451" SG_ 499 CCmHuEconModeSwitchAck 0;
BA_ "GenSigTimeoutMsg_HU_B" SG_ 499 CCmHuEconModeSwitchAck 0;
BA_ "GenSigTimeoutMsg_HU_A" SG_ 499 CCmHuEconModeSwitchAck 0;
BA_ "GenSigSendType" SG_ 499 CCmHuEconModeSwitchAck 1;
BA_ "GenSigTimeoutMsg_HU_High_X445" SG_ 499 CCmHuEconModeSwitchAck 0;
BA_ "GenSigTimeoutMsg_HU_Mid_X445" SG_ 499 CCmHuEconModeSwitchAck 0;
BA_ "GenSigTimeoutTime_HU_High_X445" SG_ 499 CCmHuEconModeSwitchAck 0;
BA_ "GenSigTimeoutTime_HU_Mid_X445" SG_ 499 CCmHuEconModeSwitchAck 0;
BA_ "GenSigTimeoutMsg_IVI" SG_ 499 CCmHuEconModeSwitchAck 0;
BA_ "GenSigTimeoutTime_IVI" SG_ 499 CCmHuEconModeSwitchAck 0;
BA_ "GenSigTimeoutTime_HU_Mid_X451" SG_ 499 CCmHuAutoSwitchAck 0;
BA_ "GenSigTimeoutTime_HU_High_X451" SG_ 499 CCmHuAutoSwitchAck 0;
BA_ "GenSigTimeoutTime_HU_B" SG_ 499 CCmHuAutoSwitchAck 0;
BA_ "GenSigTimeoutTime_HU_A" SG_ 499 CCmHuAutoSwitchAck 0;
BA_ "GenSigTimeoutMsg_HU_Mid_X451" SG_ 499 CCmHuAutoSwitchAck 0;
BA_ "GenSigTimeoutMsg_HU_High_X451" SG_ 499 CCmHuAutoSwitchAck 0;
BA_ "GenSigTimeoutMsg_HU_B" SG_ 499 CCmHuAutoSwitchAck 0;
BA_ "GenSigTimeoutMsg_HU_A" SG_ 499 CCmHuAutoSwitchAck 0;
BA_ "GenSigSendType" SG_ 499 CCmHuAutoSwitchAck 1;
BA_ "GenSigTimeoutMsg_HU_High_X445" SG_ 499 CCmHuAutoSwitchAck 0;
BA_ "GenSigTimeoutMsg_HU_Mid_X445" SG_ 499 CCmHuAutoSwitchAck 0;
BA_ "GenSigTimeoutTime_HU_High_X445" SG_ 499 CCmHuAutoSwitchAck 0;
BA_ "GenSigTimeoutTime_HU_Mid_X445" SG_ 499 CCmHuAutoSwitchAck 0;
BA_ "GenSigTimeoutMsg_IVI" SG_ 499 CCmHuAutoSwitchAck 0;
BA_ "GenSigTimeoutTime_IVI" SG_ 499 CCmHuAutoSwitchAck 0;
BA_ "GenSigTimeoutTime_HU_Mid_X451" SG_ 499 CCmHuRearDefogSwitchAck 0;
BA_ "GenSigTimeoutTime_HU_High_X451" SG_ 499 CCmHuRearDefogSwitchAck 0;
BA_ "GenSigTimeoutTime_HU_B" SG_ 499 CCmHuRearDefogSwitchAck 0;
BA_ "GenSigTimeoutTime_HU_A" SG_ 499 CCmHuRearDefogSwitchAck 0;
BA_ "GenSigTimeoutMsg_HU_Mid_X451" SG_ 499 CCmHuRearDefogSwitchAck 0;
BA_ "GenSigTimeoutMsg_HU_High_X451" SG_ 499 CCmHuRearDefogSwitchAck 0;
BA_ "GenSigTimeoutMsg_HU_B" SG_ 499 CCmHuRearDefogSwitchAck 0;
BA_ "GenSigTimeoutMsg_HU_A" SG_ 499 CCmHuRearDefogSwitchAck 0;
BA_ "GenSigSendType" SG_ 499 CCmHuRearDefogSwitchAck 1;
BA_ "GenSigTimeoutMsg_HU_High_X445" SG_ 499 CCmHuRearDefogSwitchAck 0;
BA_ "GenSigTimeoutMsg_HU_Mid_X445" SG_ 499 CCmHuRearDefogSwitchAck 0;
BA_ "GenSigTimeoutTime_HU_High_X445" SG_ 499 CCmHuRearDefogSwitchAck 0;
BA_ "GenSigTimeoutTime_HU_Mid_X445" SG_ 499 CCmHuRearDefogSwitchAck 0;
BA_ "GenSigTimeoutMsg_IVI" SG_ 499 CCmHuRearDefogSwitchAck 0;
BA_ "GenSigTimeoutTime_IVI" SG_ 499 CCmHuRearDefogSwitchAck 0;
BA_ "GenSigTimeoutTime_HU_Mid_X451" SG_ 499 CCmHuAirConCompSwitchAck 0;
BA_ "GenSigTimeoutTime_HU_High_X451" SG_ 499 CCmHuAirConCompSwitchAck 0;
BA_ "GenSigTimeoutTime_HU_B" SG_ 499 CCmHuAirConCompSwitchAck 0;
BA_ "GenSigTimeoutTime_HU_A" SG_ 499 CCmHuAirConCompSwitchAck 0;
BA_ "GenSigTimeoutMsg_HU_Mid_X451" SG_ 499 CCmHuAirConCompSwitchAck 0;
BA_ "GenSigTimeoutMsg_HU_High_X451" SG_ 499 CCmHuAirConCompSwitchAck 0;
BA_ "GenSigTimeoutMsg_HU_B" SG_ 499 CCmHuAirConCompSwitchAck 0;
BA_ "GenSigTimeoutMsg_HU_A" SG_ 499 CCmHuAirConCompSwitchAck 0;
BA_ "GenSigSendType" SG_ 499 CCmHuAirConCompSwitchAck 1;
BA_ "GenSigTimeoutMsg_HU_High_X445" SG_ 499 CCmHuAirConCompSwitchAck 0;
BA_ "GenSigTimeoutMsg_HU_Mid_X445" SG_ 499 CCmHuAirConCompSwitchAck 0;
BA_ "GenSigTimeoutTime_HU_High_X445" SG_ 499 CCmHuAirConCompSwitchAck 0;
BA_ "GenSigTimeoutTime_HU_Mid_X445" SG_ 499 CCmHuAirConCompSwitchAck 0;
BA_ "GenSigTimeoutMsg_IVI" SG_ 499 CCmHuAirConCompSwitchAck 0;
BA_ "GenSigTimeoutTime_IVI" SG_ 499 CCmHuAirConCompSwitchAck 0;
BA_ "GenSigTimeoutTime_HU_Mid_X451" SG_ 499 CCmHuErrAck 0;
BA_ "GenSigTimeoutTime_HU_High_X451" SG_ 499 CCmHuErrAck 0;
BA_ "GenSigTimeoutTime_HU_B" SG_ 499 CCmHuErrAck 0;
BA_ "GenSigTimeoutTime_HU_A" SG_ 499 CCmHuErrAck 0;
BA_ "GenSigTimeoutMsg_HU_Mid_X451" SG_ 499 CCmHuErrAck 0;
BA_ "GenSigTimeoutMsg_HU_High_X451" SG_ 499 CCmHuErrAck 0;
BA_ "GenSigTimeoutMsg_HU_B" SG_ 499 CCmHuErrAck 0;
BA_ "GenSigTimeoutMsg_HU_A" SG_ 499 CCmHuErrAck 0;
BA_ "GenSigSendType" SG_ 499 CCmHuErrAck 1;
BA_ "GenSigTimeoutMsg_HU_High_X445" SG_ 499 CCmHuErrAck 0;
BA_ "GenSigTimeoutMsg_HU_Mid_X445" SG_ 499 CCmHuErrAck 0;
BA_ "GenSigTimeoutTime_HU_High_X445" SG_ 499 CCmHuErrAck 0;
BA_ "GenSigTimeoutTime_HU_Mid_X445" SG_ 499 CCmHuErrAck 0;
BA_ "GenSigTimeoutMsg_IVI" SG_ 499 CCmHuErrAck 0;
BA_ "GenSigTimeoutTime_IVI" SG_ 499 CCmHuErrAck 0;
BA_ "GenSigTimeoutTime_HU_Mid_X451" SG_ 499 CCmHuTempWhlAck 0;
BA_ "GenSigTimeoutTime_HU_High_X451" SG_ 499 CCmHuTempWhlAck 0;
BA_ "GenSigTimeoutTime_HU_B" SG_ 499 CCmHuTempWhlAck 0;
BA_ "GenSigTimeoutTime_HU_A" SG_ 499 CCmHuTempWhlAck 0;
BA_ "GenSigTimeoutMsg_HU_Mid_X451" SG_ 499 CCmHuTempWhlAck 0;
BA_ "GenSigTimeoutMsg_HU_High_X451" SG_ 499 CCmHuTempWhlAck 0;
BA_ "GenSigTimeoutMsg_HU_B" SG_ 499 CCmHuTempWhlAck 0;
BA_ "GenSigTimeoutMsg_HU_A" SG_ 499 CCmHuTempWhlAck 0;
BA_ "GenSigSendType" SG_ 499 CCmHuTempWhlAck 1;
BA_ "GenSigTimeoutMsg_HU_High_X445" SG_ 499 CCmHuTempWhlAck 0;
BA_ "GenSigTimeoutMsg_HU_Mid_X445" SG_ 499 CCmHuTempWhlAck 0;
BA_ "GenSigTimeoutTime_HU_High_X445" SG_ 499 CCmHuTempWhlAck 0;
BA_ "GenSigTimeoutTime_HU_Mid_X445" SG_ 499 CCmHuTempWhlAck 0;
BA_ "GenSigTimeoutMsg_IVI" SG_ 499 CCmHuTempWhlAck 0;
BA_ "GenSigTimeoutTime_IVI" SG_ 499 CCmHuTempWhlAck 0;
BA_ "GenSigTimeoutTime_HU_Mid_X451" SG_ 499 CCmHuFreshAirRecircSwitchAck 0;
BA_ "GenSigTimeoutTime_HU_High_X451" SG_ 499 CCmHuFreshAirRecircSwitchAck 0;
BA_ "GenSigTimeoutTime_HU_B" SG_ 499 CCmHuFreshAirRecircSwitchAck 0;
BA_ "GenSigTimeoutTime_HU_A" SG_ 499 CCmHuFreshAirRecircSwitchAck 0;
BA_ "GenSigTimeoutMsg_HU_Mid_X451" SG_ 499 CCmHuFreshAirRecircSwitchAck 0;
BA_ "GenSigTimeoutMsg_HU_High_X451" SG_ 499 CCmHuFreshAirRecircSwitchAck 0;
BA_ "GenSigTimeoutMsg_HU_B" SG_ 499 CCmHuFreshAirRecircSwitchAck 0;
BA_ "GenSigTimeoutMsg_HU_A" SG_ 499 CCmHuFreshAirRecircSwitchAck 0;
BA_ "GenSigSendType" SG_ 499 CCmHuFreshAirRecircSwitchAck 1;
BA_ "GenSigTimeoutMsg_HU_High_X445" SG_ 499 CCmHuFreshAirRecircSwitchAck 0;
BA_ "GenSigTimeoutMsg_HU_Mid_X445" SG_ 499 CCmHuFreshAirRecircSwitchAck 0;
BA_ "GenSigTimeoutTime_HU_High_X445" SG_ 499 CCmHuFreshAirRecircSwitchAck 0;
BA_ "GenSigTimeoutTime_HU_Mid_X445" SG_ 499 CCmHuFreshAirRecircSwitchAck 0;
BA_ "GenSigTimeoutMsg_IVI" SG_ 499 CCmHuFreshAirRecircSwitchAck 0;
BA_ "GenSigTimeoutTime_IVI" SG_ 499 CCmHuFreshAirRecircSwitchAck 0;
BA_ "GenSigTimeoutTime_HU_Mid_X451" SG_ 499 CCmHuDualModeSwitchAck 0;
BA_ "GenSigTimeoutTime_HU_High_X451" SG_ 499 CCmHuDualModeSwitchAck 0;
BA_ "GenSigTimeoutTime_HU_B" SG_ 499 CCmHuDualModeSwitchAck 0;
BA_ "GenSigTimeoutTime_HU_A" SG_ 499 CCmHuDualModeSwitchAck 0;
BA_ "GenSigTimeoutMsg_HU_Mid_X451" SG_ 499 CCmHuDualModeSwitchAck 0;
BA_ "GenSigTimeoutMsg_HU_High_X451" SG_ 499 CCmHuDualModeSwitchAck 0;
BA_ "GenSigTimeoutMsg_HU_B" SG_ 499 CCmHuDualModeSwitchAck 0;
BA_ "GenSigTimeoutMsg_HU_A" SG_ 499 CCmHuDualModeSwitchAck 0;
BA_ "GenSigSendType" SG_ 499 CCmHuDualModeSwitchAck 1;
BA_ "GenSigTimeoutMsg_HU_High_X445" SG_ 499 CCmHuDualModeSwitchAck 0;
BA_ "GenSigTimeoutMsg_HU_Mid_X445" SG_ 499 CCmHuDualModeSwitchAck 0;
BA_ "GenSigTimeoutTime_HU_High_X445" SG_ 499 CCmHuDualModeSwitchAck 0;
BA_ "GenSigTimeoutTime_HU_Mid_X445" SG_ 499 CCmHuDualModeSwitchAck 0;
BA_ "GenSigTimeoutMsg_IVI" SG_ 499 CCmHuDualModeSwitchAck 0;
BA_ "GenSigTimeoutTime_IVI" SG_ 499 CCmHuDualModeSwitchAck 0;
BA_ "GenSigTimeoutTime_HU_Mid_X451" SG_ 499 CCmHuTempWhlPassAck 0;
BA_ "GenSigTimeoutTime_HU_High_X451" SG_ 499 CCmHuTempWhlPassAck 0;
BA_ "GenSigTimeoutTime_HU_B" SG_ 499 CCmHuTempWhlPassAck 0;
BA_ "GenSigTimeoutTime_HU_A" SG_ 499 CCmHuTempWhlPassAck 0;
BA_ "GenSigTimeoutMsg_HU_Mid_X451" SG_ 499 CCmHuTempWhlPassAck 0;
BA_ "GenSigTimeoutMsg_HU_High_X451" SG_ 499 CCmHuTempWhlPassAck 0;
BA_ "GenSigTimeoutMsg_HU_B" SG_ 499 CCmHuTempWhlPassAck 0;
BA_ "GenSigTimeoutMsg_HU_A" SG_ 499 CCmHuTempWhlPassAck 0;
BA_ "GenSigSendType" SG_ 499 CCmHuTempWhlPassAck 1;
BA_ "GenSigTimeoutMsg_HU_High_X445" SG_ 499 CCmHuTempWhlPassAck 0;
BA_ "GenSigTimeoutMsg_HU_Mid_X445" SG_ 499 CCmHuTempWhlPassAck 0;
BA_ "GenSigTimeoutTime_HU_High_X445" SG_ 499 CCmHuTempWhlPassAck 0;
BA_ "GenSigTimeoutTime_HU_Mid_X445" SG_ 499 CCmHuTempWhlPassAck 0;
BA_ "GenSigTimeoutMsg_IVI" SG_ 499 CCmHuTempWhlPassAck 0;
BA_ "GenSigTimeoutTime_IVI" SG_ 499 CCmHuTempWhlPassAck 0;
BA_ "GenSigTimeoutTime_HU_Mid_X451" SG_ 499 CCmHuTempWhlDrvrAck 0;
BA_ "GenSigTimeoutTime_HU_High_X451" SG_ 499 CCmHuTempWhlDrvrAck 0;
BA_ "GenSigTimeoutTime_HU_B" SG_ 499 CCmHuTempWhlDrvrAck 0;
BA_ "GenSigTimeoutTime_HU_A" SG_ 499 CCmHuTempWhlDrvrAck 0;
BA_ "GenSigTimeoutMsg_HU_Mid_X451" SG_ 499 CCmHuTempWhlDrvrAck 0;
BA_ "GenSigTimeoutMsg_HU_High_X451" SG_ 499 CCmHuTempWhlDrvrAck 0;
BA_ "GenSigTimeoutMsg_HU_B" SG_ 499 CCmHuTempWhlDrvrAck 0;
BA_ "GenSigTimeoutMsg_HU_A" SG_ 499 CCmHuTempWhlDrvrAck 0;
BA_ "GenSigSendType" SG_ 499 CCmHuTempWhlDrvrAck 1;
BA_ "GenSigTimeoutMsg_HU_High_X445" SG_ 499 CCmHuTempWhlDrvrAck 0;
BA_ "GenSigTimeoutMsg_HU_Mid_X445" SG_ 499 CCmHuTempWhlDrvrAck 0;
BA_ "GenSigTimeoutTime_HU_High_X445" SG_ 499 CCmHuTempWhlDrvrAck 0;
BA_ "GenSigTimeoutTime_HU_Mid_X445" SG_ 499 CCmHuTempWhlDrvrAck 0;
BA_ "GenSigTimeoutMsg_IVI" SG_ 499 CCmHuTempWhlDrvrAck 0;
BA_ "GenSigTimeoutTime_IVI" SG_ 499 CCmHuTempWhlDrvrAck 0;
BA_ "GenSigTimeoutTime_HU_Mid_X451" SG_ 500 CCmHuSwitchStatusStuckWarn 0;
BA_ "GenSigTimeoutTime_HU_High_X451" SG_ 500 CCmHuSwitchStatusStuckWarn 0;
BA_ "GenSigTimeoutTime_HU_B" SG_ 500 CCmHuSwitchStatusStuckWarn 0;
BA_ "GenSigTimeoutTime_HU_A" SG_ 500 CCmHuSwitchStatusStuckWarn 0;
BA_ "GenSigTimeoutMsg_HU_Mid_X451" SG_ 500 CCmHuSwitchStatusStuckWarn 0;
BA_ "GenSigTimeoutMsg_HU_High_X451" SG_ 500 CCmHuSwitchStatusStuckWarn 0;
BA_ "GenSigTimeoutMsg_HU_B" SG_ 500 CCmHuSwitchStatusStuckWarn 0;
BA_ "GenSigTimeoutMsg_HU_A" SG_ 500 CCmHuSwitchStatusStuckWarn 0;
BA_ "GenSigSendType" SG_ 500 CCmHuSwitchStatusStuckWarn 1;
BA_ "GenSigTimeoutMsg_HU_High_X445" SG_ 500 CCmHuSwitchStatusStuckWarn 0;
BA_ "GenSigTimeoutMsg_HU_Mid_X445" SG_ 500 CCmHuSwitchStatusStuckWarn 0;
BA_ "GenSigTimeoutTime_HU_High_X445" SG_ 500 CCmHuSwitchStatusStuckWarn 0;
BA_ "GenSigTimeoutTime_HU_Mid_X445" SG_ 500 CCmHuSwitchStatusStuckWarn 0;
BA_ "GenSigTimeoutMsg_IVI" SG_ 500 CCmHuSwitchStatusStuckWarn 0;
BA_ "GenSigTimeoutTime_IVI" SG_ 500 CCmHuSwitchStatusStuckWarn 0;
BA_ "GenSigTimeoutTime_HU_Mid_X451" SG_ 500 CCmHuQueryFlag 0;
BA_ "GenSigTimeoutTime_HU_High_X451" SG_ 500 CCmHuQueryFlag 0;
BA_ "GenSigTimeoutTime_HU_B" SG_ 500 CCmHuQueryFlag 0;
BA_ "GenSigTimeoutTime_HU_A" SG_ 500 CCmHuQueryFlag 0;
BA_ "GenSigTimeoutMsg_HU_Mid_X451" SG_ 500 CCmHuQueryFlag 0;
BA_ "GenSigTimeoutMsg_HU_High_X451" SG_ 500 CCmHuQueryFlag 0;
BA_ "GenSigTimeoutMsg_HU_B" SG_ 500 CCmHuQueryFlag 0;
BA_ "GenSigTimeoutMsg_HU_A" SG_ 500 CCmHuQueryFlag 0;
BA_ "GenSigSendType" SG_ 500 CCmHuQueryFlag 1;
BA_ "GenSigTimeoutMsg_HU_High_X445" SG_ 500 CCmHuQueryFlag 0;
BA_ "GenSigTimeoutMsg_HU_Mid_X445" SG_ 500 CCmHuQueryFlag 0;
BA_ "GenSigTimeoutTime_HU_High_X445" SG_ 500 CCmHuQueryFlag 0;
BA_ "GenSigTimeoutTime_HU_Mid_X445" SG_ 500 CCmHuQueryFlag 0;
BA_ "GenSigTimeoutMsg_IVI" SG_ 500 CCmHuQueryFlag 0;
BA_ "GenSigTimeoutTime_IVI" SG_ 500 CCmHuQueryFlag 0;
BA_ "GenSigTimeoutTime_HU_Mid_X451" SG_ 500 CCmHuFanControlDuringVR 0;
BA_ "GenSigTimeoutTime_HU_High_X451" SG_ 500 CCmHuFanControlDuringVR 0;
BA_ "GenSigTimeoutTime_HU_B" SG_ 500 CCmHuFanControlDuringVR 0;
BA_ "GenSigTimeoutTime_HU_A" SG_ 500 CCmHuFanControlDuringVR 0;
BA_ "GenSigTimeoutMsg_HU_Mid_X451" SG_ 500 CCmHuFanControlDuringVR 0;
BA_ "GenSigTimeoutMsg_HU_High_X451" SG_ 500 CCmHuFanControlDuringVR 0;
BA_ "GenSigTimeoutMsg_HU_B" SG_ 500 CCmHuFanControlDuringVR 0;
BA_ "GenSigTimeoutMsg_HU_A" SG_ 500 CCmHuFanControlDuringVR 0;
BA_ "GenSigStartValue" SG_ 500 CCmHuFanControlDuringVR 1;
BA_ "GenSigSendType" SG_ 500 CCmHuFanControlDuringVR 1;
BA_ "GenSigTimeoutMsg_HU_High_X445" SG_ 500 CCmHuFanControlDuringVR 0;
BA_ "GenSigTimeoutMsg_HU_Mid_X445" SG_ 500 CCmHuFanControlDuringVR 0;
BA_ "GenSigTimeoutTime_HU_High_X445" SG_ 500 CCmHuFanControlDuringVR 0;
BA_ "GenSigTimeoutTime_HU_Mid_X445" SG_ 500 CCmHuFanControlDuringVR 0;
BA_ "GenSigTimeoutMsg_IVI" SG_ 500 CCmHuFanControlDuringVR 0;
BA_ "GenSigTimeoutTime_IVI" SG_ 500 CCmHuFanControlDuringVR 0;
BA_ "GenSigTimeoutTime_HU_Mid_X451" SG_ 504 BCmAutoRelockActiveSignalVal 0;
BA_ "GenSigTimeoutTime_HU_High_X451" SG_ 504 BCmAutoRelockActiveSignalVal 0;
BA_ "GenSigTimeoutTime_HU_B" SG_ 504 BCmAutoRelockActiveSignalVal 0;
BA_ "GenSigTimeoutTime_HU_A" SG_ 504 BCmAutoRelockActiveSignalVal 0;
BA_ "GenSigTimeoutMsg_HU_Mid_X451" SG_ 504 BCmAutoRelockActiveSignalVal 0;
BA_ "GenSigTimeoutMsg_HU_High_X451" SG_ 504 BCmAutoRelockActiveSignalVal 0;
BA_ "GenSigTimeoutMsg_HU_B" SG_ 504 BCmAutoRelockActiveSignalVal 0;
BA_ "GenSigTimeoutMsg_HU_A" SG_ 504 BCmAutoRelockActiveSignalVal 0;
BA_ "GenSigSendType" SG_ 504 BCmAutoRelockActiveSignalVal 1;
BA_ "GenSigTimeoutMsg_HU_High_X445" SG_ 504 BCmAutoRelockActiveSignalVal 0;
BA_ "GenSigTimeoutMsg_HU_Mid_X445" SG_ 504 BCmAutoRelockActiveSignalVal 0;
BA_ "GenSigTimeoutTime_HU_High_X445" SG_ 504 BCmAutoRelockActiveSignalVal 0;
BA_ "GenSigTimeoutTime_HU_Mid_X445" SG_ 504 BCmAutoRelockActiveSignalVal 0;
BA_ "GenSigTimeoutMsg_IVI" SG_ 504 BCmAutoRelockActiveSignalVal 0;
BA_ "GenSigTimeoutTime_IVI" SG_ 504 BCmAutoRelockActiveSignalVal 0;
BA_ "GenSigTimeoutTime_HU_Mid_X451" SG_ 504 BCmFMhActiveSignalVal 0;
BA_ "GenSigTimeoutTime_HU_High_X451" SG_ 504 BCmFMhActiveSignalVal 0;
BA_ "GenSigTimeoutTime_HU_B" SG_ 504 BCmFMhActiveSignalVal 0;
BA_ "GenSigTimeoutTime_HU_A" SG_ 504 BCmFMhActiveSignalVal 0;
BA_ "GenSigTimeoutMsg_HU_Mid_X451" SG_ 504 BCmFMhActiveSignalVal 0;
BA_ "GenSigTimeoutMsg_HU_High_X451" SG_ 504 BCmFMhActiveSignalVal 0;
BA_ "GenSigTimeoutMsg_HU_B" SG_ 504 BCmFMhActiveSignalVal 0;
BA_ "GenSigTimeoutMsg_HU_A" SG_ 504 BCmFMhActiveSignalVal 0;
BA_ "GenSigStartValue" SG_ 504 BCmFMhActiveSignalVal 1;
BA_ "GenSigSendType" SG_ 504 BCmFMhActiveSignalVal 1;
BA_ "GenSigTimeoutMsg_HU_High_X445" SG_ 504 BCmFMhActiveSignalVal 0;
BA_ "GenSigTimeoutMsg_HU_Mid_X445" SG_ 504 BCmFMhActiveSignalVal 0;
BA_ "GenSigTimeoutTime_HU_High_X445" SG_ 504 BCmFMhActiveSignalVal 0;
BA_ "GenSigTimeoutTime_HU_Mid_X445" SG_ 504 BCmFMhActiveSignalVal 0;
BA_ "GenSigTimeoutMsg_IVI" SG_ 504 BCmFMhActiveSignalVal 0;
BA_ "GenSigTimeoutTime_IVI" SG_ 504 BCmFMhActiveSignalVal 0;
BA_ "GenSigTimeoutTime_HU_Mid_X451" SG_ 504 BCmFMhSignalVal1 0;
BA_ "GenSigTimeoutTime_HU_High_X451" SG_ 504 BCmFMhSignalVal1 0;
BA_ "GenSigTimeoutTime_HU_B" SG_ 504 BCmFMhSignalVal1 0;
BA_ "GenSigTimeoutTime_HU_A" SG_ 504 BCmFMhSignalVal1 0;
BA_ "GenSigTimeoutMsg_HU_Mid_X451" SG_ 504 BCmFMhSignalVal1 0;
BA_ "GenSigTimeoutMsg_HU_High_X451" SG_ 504 BCmFMhSignalVal1 0;
BA_ "GenSigTimeoutMsg_HU_B" SG_ 504 BCmFMhSignalVal1 0;
BA_ "GenSigTimeoutMsg_HU_A" SG_ 504 BCmFMhSignalVal1 0;
BA_ "GenSigStartValue" SG_ 504 BCmFMhSignalVal1 3;
BA_ "GenSigSendType" SG_ 504 BCmFMhSignalVal1 1;
BA_ "GenSigTimeoutMsg_HU_High_X445" SG_ 504 BCmFMhSignalVal1 0;
BA_ "GenSigTimeoutMsg_HU_Mid_X445" SG_ 504 BCmFMhSignalVal1 0;
BA_ "GenSigTimeoutTime_HU_High_X445" SG_ 504 BCmFMhSignalVal1 0;
BA_ "GenSigTimeoutTime_HU_Mid_X445" SG_ 504 BCmFMhSignalVal1 0;
BA_ "GenSigTimeoutMsg_IVI" SG_ 504 BCmFMhSignalVal1 0;
BA_ "GenSigTimeoutTime_IVI" SG_ 504 BCmFMhSignalVal1 0;
BA_ "GenSigTimeoutTime_HU_Mid_X451" SG_ 504 BCmVehLockHornReqActiveSignalVal 0;
BA_ "GenSigTimeoutTime_HU_High_X451" SG_ 504 BCmVehLockHornReqActiveSignalVal 0;
BA_ "GenSigTimeoutTime_HU_B" SG_ 504 BCmVehLockHornReqActiveSignalVal 0;
BA_ "GenSigTimeoutTime_HU_A" SG_ 504 BCmVehLockHornReqActiveSignalVal 0;
BA_ "GenSigTimeoutMsg_HU_Mid_X451" SG_ 504 BCmVehLockHornReqActiveSignalVal 0;
BA_ "GenSigTimeoutMsg_HU_High_X451" SG_ 504 BCmVehLockHornReqActiveSignalVal 0;
BA_ "GenSigTimeoutMsg_HU_B" SG_ 504 BCmVehLockHornReqActiveSignalVal 0;
BA_ "GenSigTimeoutMsg_HU_A" SG_ 504 BCmVehLockHornReqActiveSignalVal 0;
BA_ "GenSigSendType" SG_ 504 BCmVehLockHornReqActiveSignalVal 1;
BA_ "GenSigTimeoutMsg_HU_High_X445" SG_ 504 BCmVehLockHornReqActiveSignalVal 0;
BA_ "GenSigTimeoutMsg_HU_Mid_X445" SG_ 504 BCmVehLockHornReqActiveSignalVal 0;
BA_ "GenSigTimeoutTime_HU_High_X445" SG_ 504 BCmVehLockHornReqActiveSignalVal 0;
BA_ "GenSigTimeoutTime_HU_Mid_X445" SG_ 504 BCmVehLockHornReqActiveSignalVal 0;
BA_ "GenSigTimeoutMsg_IVI" SG_ 504 BCmVehLockHornReqActiveSignalVal 0;
BA_ "GenSigTimeoutTime_IVI" SG_ 504 BCmVehLockHornReqActiveSignalVal 0;
BA_ "GenSigTimeoutTime_HU_Mid_X451" SG_ 504 BCmApproachLampActiveSignalVal 0;
BA_ "GenSigTimeoutTime_HU_High_X451" SG_ 504 BCmApproachLampActiveSignalVal 0;
BA_ "GenSigTimeoutTime_HU_B" SG_ 504 BCmApproachLampActiveSignalVal 0;
BA_ "GenSigTimeoutTime_HU_A" SG_ 504 BCmApproachLampActiveSignalVal 0;
BA_ "GenSigTimeoutMsg_HU_Mid_X451" SG_ 504 BCmApproachLampActiveSignalVal 0;
BA_ "GenSigTimeoutMsg_HU_High_X451" SG_ 504 BCmApproachLampActiveSignalVal 0;
BA_ "GenSigTimeoutMsg_HU_B" SG_ 504 BCmApproachLampActiveSignalVal 0;
BA_ "GenSigTimeoutMsg_HU_A" SG_ 504 BCmApproachLampActiveSignalVal 0;
BA_ "GenSigStartValue" SG_ 504 BCmApproachLampActiveSignalVal 1;
BA_ "GenSigSendType" SG_ 504 BCmApproachLampActiveSignalVal 1;
BA_ "GenSigTimeoutMsg_HU_High_X445" SG_ 504 BCmApproachLampActiveSignalVal 0;
BA_ "GenSigTimeoutMsg_HU_Mid_X445" SG_ 504 BCmApproachLampActiveSignalVal 0;
BA_ "GenSigTimeoutTime_HU_High_X445" SG_ 504 BCmApproachLampActiveSignalVal 0;
BA_ "GenSigTimeoutTime_HU_Mid_X445" SG_ 504 BCmApproachLampActiveSignalVal 0;
BA_ "GenSigTimeoutMsg_IVI" SG_ 504 BCmApproachLampActiveSignalVal 0;
BA_ "GenSigTimeoutTime_IVI" SG_ 504 BCmApproachLampActiveSignalVal 0;
BA_ "GenSigTimeoutTime_HU_Mid_X451" SG_ 504 BCmFMhSignalVal2 0;
BA_ "GenSigTimeoutTime_HU_High_X451" SG_ 504 BCmFMhSignalVal2 0;
BA_ "GenSigTimeoutTime_HU_B" SG_ 504 BCmFMhSignalVal2 0;
BA_ "GenSigTimeoutTime_HU_A" SG_ 504 BCmFMhSignalVal2 0;
BA_ "GenSigTimeoutMsg_HU_Mid_X451" SG_ 504 BCmFMhSignalVal2 0;
BA_ "GenSigTimeoutMsg_HU_High_X451" SG_ 504 BCmFMhSignalVal2 0;
BA_ "GenSigTimeoutMsg_HU_B" SG_ 504 BCmFMhSignalVal2 0;
BA_ "GenSigTimeoutMsg_HU_A" SG_ 504 BCmFMhSignalVal2 0;
BA_ "GenSigStartValue" SG_ 504 BCmFMhSignalVal2 6;
BA_ "GenSigSendType" SG_ 504 BCmFMhSignalVal2 1;
BA_ "GenSigTimeoutMsg_HU_High_X445" SG_ 504 BCmFMhSignalVal2 0;
BA_ "GenSigTimeoutMsg_HU_Mid_X445" SG_ 504 BCmFMhSignalVal2 0;
BA_ "GenSigTimeoutTime_HU_High_X445" SG_ 504 BCmFMhSignalVal2 0;
BA_ "GenSigTimeoutTime_HU_Mid_X445" SG_ 504 BCmFMhSignalVal2 0;
BA_ "GenSigTimeoutMsg_IVI" SG_ 504 BCmFMhSignalVal2 0;
BA_ "GenSigTimeoutTime_IVI" SG_ 504 BCmFMhSignalVal2 0;
BA_ "GenSigTimeoutTime_HU_Mid_X451" SG_ 504 BCmDriveAwayLockingActiveSignalV 0;
BA_ "GenSigTimeoutTime_HU_High_X451" SG_ 504 BCmDriveAwayLockingActiveSignalV 0;
BA_ "GenSigTimeoutTime_HU_B" SG_ 504 BCmDriveAwayLockingActiveSignalV 0;
BA_ "GenSigTimeoutTime_HU_A" SG_ 504 BCmDriveAwayLockingActiveSignalV 0;
BA_ "GenSigTimeoutMsg_HU_Mid_X451" SG_ 504 BCmDriveAwayLockingActiveSignalV 0;
BA_ "GenSigTimeoutMsg_HU_High_X451" SG_ 504 BCmDriveAwayLockingActiveSignalV 0;
BA_ "GenSigTimeoutMsg_HU_B" SG_ 504 BCmDriveAwayLockingActiveSignalV 0;
BA_ "GenSigTimeoutMsg_HU_A" SG_ 504 BCmDriveAwayLockingActiveSignalV 0;
BA_ "GenSigSendType" SG_ 504 BCmDriveAwayLockingActiveSignalV 1;
BA_ "GenSigTimeoutMsg_HU_High_X445" SG_ 504 BCmDriveAwayLockingActiveSignalV 0;
BA_ "GenSigTimeoutMsg_HU_Mid_X445" SG_ 504 BCmDriveAwayLockingActiveSignalV 0;
BA_ "GenSigTimeoutTime_HU_High_X445" SG_ 504 BCmDriveAwayLockingActiveSignalV 0;
BA_ "GenSigTimeoutTime_HU_Mid_X445" SG_ 504 BCmDriveAwayLockingActiveSignalV 0;
BA_ "GenSigTimeoutMsg_IVI" SG_ 504 BCmDriveAwayLockingActiveSignalV 0;
BA_ "GenSigTimeoutTime_IVI" SG_ 504 BCmDriveAwayLockingActiveSignalV 0;
BA_ "SystemSignalLongSymbol" SG_ 504 BCmDriveAwayLockingActiveSignalV "BCmDriveAwayLockingActiveSignalVal";
BA_ "GenSigTimeoutTime_HU_Mid_X451" SG_ 504 BCmRKeUnlockState 0;
BA_ "GenSigTimeoutTime_HU_High_X451" SG_ 504 BCmRKeUnlockState 0;
BA_ "GenSigTimeoutTime_HU_B" SG_ 504 BCmRKeUnlockState 0;
BA_ "GenSigTimeoutTime_HU_A" SG_ 504 BCmRKeUnlockState 0;
BA_ "GenSigTimeoutMsg_HU_Mid_X451" SG_ 504 BCmRKeUnlockState 0;
BA_ "GenSigTimeoutMsg_HU_High_X451" SG_ 504 BCmRKeUnlockState 0;
BA_ "GenSigTimeoutMsg_HU_B" SG_ 504 BCmRKeUnlockState 0;
BA_ "GenSigTimeoutMsg_HU_A" SG_ 504 BCmRKeUnlockState 0;
BA_ "GenSigSendType" SG_ 504 BCmRKeUnlockState 1;
BA_ "GenSigTimeoutMsg_HU_High_X445" SG_ 504 BCmRKeUnlockState 0;
BA_ "GenSigTimeoutMsg_HU_Mid_X445" SG_ 504 BCmRKeUnlockState 0;
BA_ "GenSigTimeoutTime_HU_High_X445" SG_ 504 BCmRKeUnlockState 0;
BA_ "GenSigTimeoutTime_HU_Mid_X445" SG_ 504 BCmRKeUnlockState 0;
BA_ "GenSigTimeoutMsg_IVI" SG_ 504 BCmRKeUnlockState 0;
BA_ "GenSigTimeoutTime_IVI" SG_ 504 BCmRKeUnlockState 0;
BA_ "GenSigTimeoutTime_HU_Mid_X451" SG_ 504 BCmPKeUnlockState 0;
BA_ "GenSigTimeoutTime_HU_High_X451" SG_ 504 BCmPKeUnlockState 0;
BA_ "GenSigTimeoutTime_HU_B" SG_ 504 BCmPKeUnlockState 0;
BA_ "GenSigTimeoutTime_HU_A" SG_ 504 BCmPKeUnlockState 0;
BA_ "GenSigTimeoutMsg_HU_Mid_X451" SG_ 504 BCmPKeUnlockState 0;
BA_ "GenSigTimeoutMsg_HU_High_X451" SG_ 504 BCmPKeUnlockState 0;
BA_ "GenSigTimeoutMsg_HU_B" SG_ 504 BCmPKeUnlockState 0;
BA_ "GenSigTimeoutMsg_HU_A" SG_ 504 BCmPKeUnlockState 0;
BA_ "GenSigSendType" SG_ 504 BCmPKeUnlockState 1;
BA_ "GenSigTimeoutMsg_HU_High_X445" SG_ 504 BCmPKeUnlockState 0;
BA_ "GenSigTimeoutMsg_HU_Mid_X445" SG_ 504 BCmPKeUnlockState 0;
BA_ "GenSigTimeoutTime_HU_High_X445" SG_ 504 BCmPKeUnlockState 0;
BA_ "GenSigTimeoutTime_HU_Mid_X445" SG_ 504 BCmPKeUnlockState 0;
BA_ "GenSigTimeoutMsg_IVI" SG_ 504 BCmPKeUnlockState 0;
BA_ "GenSigTimeoutTime_IVI" SG_ 504 BCmPKeUnlockState 0;
BA_ "GenSigTimeoutTime_HU_Mid_X451" SG_ 504 BCmFMhSignalVal3 0;
BA_ "GenSigTimeoutTime_HU_High_X451" SG_ 504 BCmFMhSignalVal3 0;
BA_ "GenSigTimeoutTime_HU_B" SG_ 504 BCmFMhSignalVal3 0;
BA_ "GenSigTimeoutTime_HU_A" SG_ 504 BCmFMhSignalVal3 0;
BA_ "GenSigTimeoutMsg_HU_Mid_X451" SG_ 504 BCmFMhSignalVal3 0;
BA_ "GenSigTimeoutMsg_HU_High_X451" SG_ 504 BCmFMhSignalVal3 0;
BA_ "GenSigTimeoutMsg_HU_B" SG_ 504 BCmFMhSignalVal3 0;
BA_ "GenSigTimeoutMsg_HU_A" SG_ 504 BCmFMhSignalVal3 0;
BA_ "GenSigStartValue" SG_ 504 BCmFMhSignalVal3 12;
BA_ "GenSigSendType" SG_ 504 BCmFMhSignalVal3 1;
BA_ "GenSigTimeoutMsg_HU_High_X445" SG_ 504 BCmFMhSignalVal3 0;
BA_ "GenSigTimeoutMsg_HU_Mid_X445" SG_ 504 BCmFMhSignalVal3 0;
BA_ "GenSigTimeoutTime_HU_High_X445" SG_ 504 BCmFMhSignalVal3 0;
BA_ "GenSigTimeoutTime_HU_Mid_X445" SG_ 504 BCmFMhSignalVal3 0;
BA_ "GenSigTimeoutMsg_IVI" SG_ 504 BCmFMhSignalVal3 0;
BA_ "GenSigTimeoutTime_IVI" SG_ 504 BCmFMhSignalVal3 0;
BA_ "GenSigTimeoutTime_HU_Mid_X451" SG_ 504 BCmAutoRelockState 0;
BA_ "GenSigTimeoutTime_HU_High_X451" SG_ 504 BCmAutoRelockState 0;
BA_ "GenSigTimeoutTime_HU_B" SG_ 504 BCmAutoRelockState 0;
BA_ "GenSigTimeoutTime_HU_A" SG_ 504 BCmAutoRelockState 0;
BA_ "GenSigTimeoutMsg_HU_Mid_X451" SG_ 504 BCmAutoRelockState 0;
BA_ "GenSigTimeoutMsg_HU_High_X451" SG_ 504 BCmAutoRelockState 0;
BA_ "GenSigTimeoutMsg_HU_B" SG_ 504 BCmAutoRelockState 0;
BA_ "GenSigTimeoutMsg_HU_A" SG_ 504 BCmAutoRelockState 0;
BA_ "GenSigSendType" SG_ 504 BCmAutoRelockState 1;
BA_ "GenSigTimeoutMsg_HU_High_X445" SG_ 504 BCmAutoRelockState 0;
BA_ "GenSigTimeoutMsg_HU_Mid_X445" SG_ 504 BCmAutoRelockState 0;
BA_ "GenSigTimeoutTime_HU_High_X445" SG_ 504 BCmAutoRelockState 0;
BA_ "GenSigTimeoutTime_HU_Mid_X445" SG_ 504 BCmAutoRelockState 0;
BA_ "GenSigTimeoutMsg_IVI" SG_ 504 BCmAutoRelockState 0;
BA_ "GenSigTimeoutTime_IVI" SG_ 504 BCmAutoRelockState 0;
BA_ "GenSigTimeoutTime_HU_Mid_X451" SG_ 504 BCmFMhState 0;
BA_ "GenSigTimeoutTime_HU_High_X451" SG_ 504 BCmFMhState 0;
BA_ "GenSigTimeoutTime_HU_B" SG_ 504 BCmFMhState 0;
BA_ "GenSigTimeoutTime_HU_A" SG_ 504 BCmFMhState 0;
BA_ "GenSigTimeoutMsg_HU_Mid_X451" SG_ 504 BCmFMhState 0;
BA_ "GenSigTimeoutMsg_HU_High_X451" SG_ 504 BCmFMhState 0;
BA_ "GenSigTimeoutMsg_HU_B" SG_ 504 BCmFMhState 0;
BA_ "GenSigTimeoutMsg_HU_A" SG_ 504 BCmFMhState 0;
BA_ "GenSigSendType" SG_ 504 BCmFMhState 1;
BA_ "GenSigTimeoutMsg_HU_High_X445" SG_ 504 BCmFMhState 0;
BA_ "GenSigTimeoutMsg_HU_Mid_X445" SG_ 504 BCmFMhState 0;
BA_ "GenSigTimeoutTime_HU_High_X445" SG_ 504 BCmFMhState 0;
BA_ "GenSigTimeoutTime_HU_Mid_X445" SG_ 504 BCmFMhState 0;
BA_ "GenSigTimeoutMsg_IVI" SG_ 504 BCmFMhState 0;
BA_ "GenSigTimeoutTime_IVI" SG_ 504 BCmFMhState 0;
BA_ "GenSigTimeoutTime_HU_Mid_X451" SG_ 504 BCmUCsState 0;
BA_ "GenSigTimeoutTime_HU_High_X451" SG_ 504 BCmUCsState 0;
BA_ "GenSigTimeoutTime_HU_B" SG_ 504 BCmUCsState 0;
BA_ "GenSigTimeoutTime_HU_A" SG_ 504 BCmUCsState 0;
BA_ "GenSigTimeoutMsg_HU_Mid_X451" SG_ 504 BCmUCsState 0;
BA_ "GenSigTimeoutMsg_HU_High_X451" SG_ 504 BCmUCsState 0;
BA_ "GenSigTimeoutMsg_HU_B" SG_ 504 BCmUCsState 0;
BA_ "GenSigTimeoutMsg_HU_A" SG_ 504 BCmUCsState 0;
BA_ "GenSigSendType" SG_ 504 BCmUCsState 1;
BA_ "GenSigTimeoutMsg_HU_High_X445" SG_ 504 BCmUCsState 0;
BA_ "GenSigTimeoutMsg_HU_Mid_X445" SG_ 504 BCmUCsState 0;
BA_ "GenSigTimeoutTime_HU_High_X445" SG_ 504 BCmUCsState 0;
BA_ "GenSigTimeoutTime_HU_Mid_X445" SG_ 504 BCmUCsState 0;
BA_ "GenSigTimeoutMsg_IVI" SG_ 504 BCmUCsState 0;
BA_ "GenSigTimeoutTime_IVI" SG_ 504 BCmUCsState 0;
BA_ "GenSigTimeoutTime_HU_Mid_X451" SG_ 504 BCmApproachLampSignalVal1 0;
BA_ "GenSigTimeoutTime_HU_High_X451" SG_ 504 BCmApproachLampSignalVal1 0;
BA_ "GenSigTimeoutTime_HU_B" SG_ 504 BCmApproachLampSignalVal1 0;
BA_ "GenSigTimeoutTime_HU_A" SG_ 504 BCmApproachLampSignalVal1 0;
BA_ "GenSigTimeoutMsg_HU_Mid_X451" SG_ 504 BCmApproachLampSignalVal1 0;
BA_ "GenSigTimeoutMsg_HU_High_X451" SG_ 504 BCmApproachLampSignalVal1 0;
BA_ "GenSigTimeoutMsg_HU_B" SG_ 504 BCmApproachLampSignalVal1 0;
BA_ "GenSigTimeoutMsg_HU_A" SG_ 504 BCmApproachLampSignalVal1 0;
BA_ "GenSigStartValue" SG_ 504 BCmApproachLampSignalVal1 3;
BA_ "GenSigSendType" SG_ 504 BCmApproachLampSignalVal1 1;
BA_ "GenSigTimeoutMsg_HU_High_X445" SG_ 504 BCmApproachLampSignalVal1 0;
BA_ "GenSigTimeoutMsg_HU_Mid_X445" SG_ 504 BCmApproachLampSignalVal1 0;
BA_ "GenSigTimeoutTime_HU_High_X445" SG_ 504 BCmApproachLampSignalVal1 0;
BA_ "GenSigTimeoutTime_HU_Mid_X445" SG_ 504 BCmApproachLampSignalVal1 0;
BA_ "GenSigTimeoutMsg_IVI" SG_ 504 BCmApproachLampSignalVal1 0;
BA_ "GenSigTimeoutTime_IVI" SG_ 504 BCmApproachLampSignalVal1 0;
BA_ "GenSigTimeoutTime_HU_Mid_X451" SG_ 504 BCmPKeUnlockActiveSignalVal 0;
BA_ "GenSigTimeoutTime_HU_High_X451" SG_ 504 BCmPKeUnlockActiveSignalVal 0;
BA_ "GenSigTimeoutTime_HU_B" SG_ 504 BCmPKeUnlockActiveSignalVal 0;
BA_ "GenSigTimeoutTime_HU_A" SG_ 504 BCmPKeUnlockActiveSignalVal 0;
BA_ "GenSigTimeoutMsg_HU_Mid_X451" SG_ 504 BCmPKeUnlockActiveSignalVal 0;
BA_ "GenSigTimeoutMsg_HU_High_X451" SG_ 504 BCmPKeUnlockActiveSignalVal 0;
BA_ "GenSigTimeoutMsg_HU_B" SG_ 504 BCmPKeUnlockActiveSignalVal 0;
BA_ "GenSigTimeoutMsg_HU_A" SG_ 504 BCmPKeUnlockActiveSignalVal 0;
BA_ "GenSigSendType" SG_ 504 BCmPKeUnlockActiveSignalVal 1;
BA_ "GenSigTimeoutMsg_HU_High_X445" SG_ 504 BCmPKeUnlockActiveSignalVal 0;
BA_ "GenSigTimeoutMsg_HU_Mid_X445" SG_ 504 BCmPKeUnlockActiveSignalVal 0;
BA_ "GenSigTimeoutTime_HU_High_X445" SG_ 504 BCmPKeUnlockActiveSignalVal 0;
BA_ "GenSigTimeoutTime_HU_Mid_X445" SG_ 504 BCmPKeUnlockActiveSignalVal 0;
BA_ "GenSigTimeoutMsg_IVI" SG_ 504 BCmPKeUnlockActiveSignalVal 0;
BA_ "GenSigTimeoutTime_IVI" SG_ 504 BCmPKeUnlockActiveSignalVal 0;
BA_ "GenSigTimeoutTime_HU_Mid_X451" SG_ 504 BCmRKeUnlockActiveSignalVal 0;
BA_ "GenSigTimeoutTime_HU_High_X451" SG_ 504 BCmRKeUnlockActiveSignalVal 0;
BA_ "GenSigTimeoutTime_HU_B" SG_ 504 BCmRKeUnlockActiveSignalVal 0;
BA_ "GenSigTimeoutTime_HU_A" SG_ 504 BCmRKeUnlockActiveSignalVal 0;
BA_ "GenSigTimeoutMsg_HU_Mid_X451" SG_ 504 BCmRKeUnlockActiveSignalVal 0;
BA_ "GenSigTimeoutMsg_HU_High_X451" SG_ 504 BCmRKeUnlockActiveSignalVal 0;
BA_ "GenSigTimeoutMsg_HU_B" SG_ 504 BCmRKeUnlockActiveSignalVal 0;
BA_ "GenSigTimeoutMsg_HU_A" SG_ 504 BCmRKeUnlockActiveSignalVal 0;
BA_ "GenSigSendType" SG_ 504 BCmRKeUnlockActiveSignalVal 1;
BA_ "GenSigTimeoutMsg_HU_High_X445" SG_ 504 BCmRKeUnlockActiveSignalVal 0;
BA_ "GenSigTimeoutMsg_HU_Mid_X445" SG_ 504 BCmRKeUnlockActiveSignalVal 0;
BA_ "GenSigTimeoutTime_HU_High_X445" SG_ 504 BCmRKeUnlockActiveSignalVal 0;
BA_ "GenSigTimeoutTime_HU_Mid_X445" SG_ 504 BCmRKeUnlockActiveSignalVal 0;
BA_ "GenSigTimeoutMsg_IVI" SG_ 504 BCmRKeUnlockActiveSignalVal 0;
BA_ "GenSigTimeoutTime_IVI" SG_ 504 BCmRKeUnlockActiveSignalVal 0;
BA_ "GenSigTimeoutTime_HU_Mid_X451" SG_ 504 BCmDriveAwayLockingState 0;
BA_ "GenSigTimeoutTime_HU_High_X451" SG_ 504 BCmDriveAwayLockingState 0;
BA_ "GenSigTimeoutTime_HU_B" SG_ 504 BCmDriveAwayLockingState 0;
BA_ "GenSigTimeoutTime_HU_A" SG_ 504 BCmDriveAwayLockingState 0;
BA_ "GenSigTimeoutMsg_HU_Mid_X451" SG_ 504 BCmDriveAwayLockingState 0;
BA_ "GenSigTimeoutMsg_HU_High_X451" SG_ 504 BCmDriveAwayLockingState 0;
BA_ "GenSigTimeoutMsg_HU_B" SG_ 504 BCmDriveAwayLockingState 0;
BA_ "GenSigTimeoutMsg_HU_A" SG_ 504 BCmDriveAwayLockingState 0;
BA_ "GenSigSendType" SG_ 504 BCmDriveAwayLockingState 1;
BA_ "GenSigTimeoutMsg_HU_High_X445" SG_ 504 BCmDriveAwayLockingState 0;
BA_ "GenSigTimeoutMsg_HU_Mid_X445" SG_ 504 BCmDriveAwayLockingState 0;
BA_ "GenSigTimeoutTime_HU_High_X445" SG_ 504 BCmDriveAwayLockingState 0;
BA_ "GenSigTimeoutTime_HU_Mid_X445" SG_ 504 BCmDriveAwayLockingState 0;
BA_ "GenSigTimeoutMsg_IVI" SG_ 504 BCmDriveAwayLockingState 0;
BA_ "GenSigTimeoutTime_IVI" SG_ 504 BCmDriveAwayLockingState 0;
BA_ "GenSigTimeoutTime_HU_Mid_X451" SG_ 504 BCmApproachLampSignalVal2 0;
BA_ "GenSigTimeoutTime_HU_High_X451" SG_ 504 BCmApproachLampSignalVal2 0;
BA_ "GenSigTimeoutTime_HU_B" SG_ 504 BCmApproachLampSignalVal2 0;
BA_ "GenSigTimeoutTime_HU_A" SG_ 504 BCmApproachLampSignalVal2 0;
BA_ "GenSigTimeoutMsg_HU_Mid_X451" SG_ 504 BCmApproachLampSignalVal2 0;
BA_ "GenSigTimeoutMsg_HU_High_X451" SG_ 504 BCmApproachLampSignalVal2 0;
BA_ "GenSigTimeoutMsg_HU_B" SG_ 504 BCmApproachLampSignalVal2 0;
BA_ "GenSigTimeoutMsg_HU_A" SG_ 504 BCmApproachLampSignalVal2 0;
BA_ "GenSigStartValue" SG_ 504 BCmApproachLampSignalVal2 6;
BA_ "GenSigSendType" SG_ 504 BCmApproachLampSignalVal2 1;
BA_ "GenSigTimeoutMsg_HU_High_X445" SG_ 504 BCmApproachLampSignalVal2 0;
BA_ "GenSigTimeoutMsg_HU_Mid_X445" SG_ 504 BCmApproachLampSignalVal2 0;
BA_ "GenSigTimeoutTime_HU_High_X445" SG_ 504 BCmApproachLampSignalVal2 0;
BA_ "GenSigTimeoutTime_HU_Mid_X445" SG_ 504 BCmApproachLampSignalVal2 0;
BA_ "GenSigTimeoutMsg_IVI" SG_ 504 BCmApproachLampSignalVal2 0;
BA_ "GenSigTimeoutTime_IVI" SG_ 504 BCmApproachLampSignalVal2 0;
BA_ "GenSigTimeoutTime_HU_Mid_X451" SG_ 504 AmbLightModeIllumOnHu 0;
BA_ "GenSigTimeoutTime_HU_High_X451" SG_ 504 AmbLightModeIllumOnHu 0;
BA_ "GenSigTimeoutTime_HU_B" SG_ 504 AmbLightModeIllumOnHu 0;
BA_ "GenSigTimeoutTime_HU_A" SG_ 504 AmbLightModeIllumOnHu 0;
BA_ "GenSigTimeoutMsg_HU_Mid_X451" SG_ 504 AmbLightModeIllumOnHu 0;
BA_ "GenSigTimeoutMsg_HU_High_X451" SG_ 504 AmbLightModeIllumOnHu 0;
BA_ "GenSigTimeoutMsg_HU_B" SG_ 504 AmbLightModeIllumOnHu 0;
BA_ "GenSigTimeoutMsg_HU_A" SG_ 504 AmbLightModeIllumOnHu 0;
BA_ "GenSigSendType" SG_ 504 AmbLightModeIllumOnHu 1;
BA_ "GenSigTimeoutMsg_HU_High_X445" SG_ 504 AmbLightModeIllumOnHu 0;
BA_ "GenSigTimeoutMsg_HU_Mid_X445" SG_ 504 AmbLightModeIllumOnHu 0;
BA_ "GenSigTimeoutTime_HU_High_X445" SG_ 504 AmbLightModeIllumOnHu 0;
BA_ "GenSigTimeoutTime_HU_Mid_X445" SG_ 504 AmbLightModeIllumOnHu 0;
BA_ "GenSigTimeoutMsg_IVI" SG_ 504 AmbLightModeIllumOnHu 0;
BA_ "GenSigTimeoutTime_IVI" SG_ 504 AmbLightModeIllumOnHu 0;
BA_ "GenSigTimeoutTime_HU_Mid_X451" SG_ 504 BCmApproachLampState 0;
BA_ "GenSigTimeoutTime_HU_High_X451" SG_ 504 BCmApproachLampState 0;
BA_ "GenSigTimeoutTime_HU_B" SG_ 504 BCmApproachLampState 0;
BA_ "GenSigTimeoutTime_HU_A" SG_ 504 BCmApproachLampState 0;
BA_ "GenSigTimeoutMsg_HU_Mid_X451" SG_ 504 BCmApproachLampState 0;
BA_ "GenSigTimeoutMsg_HU_High_X451" SG_ 504 BCmApproachLampState 0;
BA_ "GenSigTimeoutMsg_HU_B" SG_ 504 BCmApproachLampState 0;
BA_ "GenSigTimeoutMsg_HU_A" SG_ 504 BCmApproachLampState 0;
BA_ "GenSigSendType" SG_ 504 BCmApproachLampState 1;
BA_ "GenSigTimeoutMsg_HU_High_X445" SG_ 504 BCmApproachLampState 0;
BA_ "GenSigTimeoutMsg_HU_Mid_X445" SG_ 504 BCmApproachLampState 0;
BA_ "GenSigTimeoutTime_HU_High_X445" SG_ 504 BCmApproachLampState 0;
BA_ "GenSigTimeoutTime_HU_Mid_X445" SG_ 504 BCmApproachLampState 0;
BA_ "GenSigTimeoutMsg_IVI" SG_ 504 BCmApproachLampState 0;
BA_ "GenSigTimeoutTime_IVI" SG_ 504 BCmApproachLampState 0;
BA_ "GenSigTimeoutTime_HU_Mid_X451" SG_ 504 BCmVehLockHornReqState 0;
BA_ "GenSigTimeoutTime_HU_High_X451" SG_ 504 BCmVehLockHornReqState 0;
BA_ "GenSigTimeoutTime_HU_B" SG_ 504 BCmVehLockHornReqState 0;
BA_ "GenSigTimeoutTime_HU_A" SG_ 504 BCmVehLockHornReqState 0;
BA_ "GenSigTimeoutMsg_HU_Mid_X451" SG_ 504 BCmVehLockHornReqState 0;
BA_ "GenSigTimeoutMsg_HU_High_X451" SG_ 504 BCmVehLockHornReqState 0;
BA_ "GenSigTimeoutMsg_HU_B" SG_ 504 BCmVehLockHornReqState 0;
BA_ "GenSigTimeoutMsg_HU_A" SG_ 504 BCmVehLockHornReqState 0;
BA_ "GenSigSendType" SG_ 504 BCmVehLockHornReqState 1;
BA_ "GenSigTimeoutMsg_HU_High_X445" SG_ 504 BCmVehLockHornReqState 0;
BA_ "GenSigTimeoutMsg_HU_Mid_X445" SG_ 504 BCmVehLockHornReqState 0;
BA_ "GenSigTimeoutTime_HU_High_X445" SG_ 504 BCmVehLockHornReqState 0;
BA_ "GenSigTimeoutTime_HU_Mid_X445" SG_ 504 BCmVehLockHornReqState 0;
BA_ "GenSigTimeoutMsg_IVI" SG_ 504 BCmVehLockHornReqState 0;
BA_ "GenSigTimeoutTime_IVI" SG_ 504 BCmVehLockHornReqState 0;
BA_ "GenSigTimeoutTime_HU_Mid_X451" SG_ 504 BCmApproachLampSignalVal3 0;
BA_ "GenSigTimeoutTime_HU_High_X451" SG_ 504 BCmApproachLampSignalVal3 0;
BA_ "GenSigTimeoutTime_HU_B" SG_ 504 BCmApproachLampSignalVal3 0;
BA_ "GenSigTimeoutTime_HU_A" SG_ 504 BCmApproachLampSignalVal3 0;
BA_ "GenSigTimeoutMsg_HU_Mid_X451" SG_ 504 BCmApproachLampSignalVal3 0;
BA_ "GenSigTimeoutMsg_HU_High_X451" SG_ 504 BCmApproachLampSignalVal3 0;
BA_ "GenSigTimeoutMsg_HU_B" SG_ 504 BCmApproachLampSignalVal3 0;
BA_ "GenSigTimeoutMsg_HU_A" SG_ 504 BCmApproachLampSignalVal3 0;
BA_ "GenSigStartValue" SG_ 504 BCmApproachLampSignalVal3 9;
BA_ "GenSigSendType" SG_ 504 BCmApproachLampSignalVal3 1;
BA_ "GenSigTimeoutMsg_HU_High_X445" SG_ 504 BCmApproachLampSignalVal3 0;
BA_ "GenSigTimeoutMsg_HU_Mid_X445" SG_ 504 BCmApproachLampSignalVal3 0;
BA_ "GenSigTimeoutTime_HU_High_X445" SG_ 504 BCmApproachLampSignalVal3 0;
BA_ "GenSigTimeoutTime_HU_Mid_X445" SG_ 504 BCmApproachLampSignalVal3 0;
BA_ "GenSigTimeoutMsg_IVI" SG_ 504 BCmApproachLampSignalVal3 0;
BA_ "GenSigTimeoutTime_IVI" SG_ 504 BCmApproachLampSignalVal3 0;
BA_ "GenSigTimeoutTime_HU_Mid_X451" SG_ 504 BCmDRLActiveSignalVal 0;
BA_ "GenSigTimeoutTime_HU_High_X451" SG_ 504 BCmDRLActiveSignalVal 0;
BA_ "GenSigTimeoutTime_HU_B" SG_ 504 BCmDRLActiveSignalVal 0;
BA_ "GenSigTimeoutTime_HU_A" SG_ 504 BCmDRLActiveSignalVal 0;
BA_ "GenSigTimeoutMsg_HU_Mid_X451" SG_ 504 BCmDRLActiveSignalVal 0;
BA_ "GenSigTimeoutMsg_HU_High_X451" SG_ 504 BCmDRLActiveSignalVal 0;
BA_ "GenSigTimeoutMsg_HU_B" SG_ 504 BCmDRLActiveSignalVal 0;
BA_ "GenSigTimeoutMsg_HU_A" SG_ 504 BCmDRLActiveSignalVal 0;
BA_ "GenSigSendType" SG_ 504 BCmDRLActiveSignalVal 1;
BA_ "GenSigTimeoutMsg_HU_High_X445" SG_ 504 BCmDRLActiveSignalVal 0;
BA_ "GenSigTimeoutMsg_HU_Mid_X445" SG_ 504 BCmDRLActiveSignalVal 0;
BA_ "GenSigTimeoutTime_HU_High_X445" SG_ 504 BCmDRLActiveSignalVal 0;
BA_ "GenSigTimeoutTime_HU_Mid_X445" SG_ 504 BCmDRLActiveSignalVal 0;
BA_ "GenSigTimeoutMsg_IVI" SG_ 504 BCmDRLActiveSignalVal 0;
BA_ "GenSigTimeoutTime_IVI" SG_ 504 BCmDRLActiveSignalVal 0;
BA_ "GenSigTimeoutTime_HU_Mid_X451" SG_ 504 BCmDRLState 0;
BA_ "GenSigTimeoutTime_HU_High_X451" SG_ 504 BCmDRLState 0;
BA_ "GenSigTimeoutTime_HU_B" SG_ 504 BCmDRLState 0;
BA_ "GenSigTimeoutTime_HU_A" SG_ 504 BCmDRLState 0;
BA_ "GenSigTimeoutMsg_HU_Mid_X451" SG_ 504 BCmDRLState 0;
BA_ "GenSigTimeoutMsg_HU_High_X451" SG_ 504 BCmDRLState 0;
BA_ "GenSigTimeoutMsg_HU_B" SG_ 504 BCmDRLState 0;
BA_ "GenSigTimeoutMsg_HU_A" SG_ 504 BCmDRLState 0;
BA_ "GenSigSendType" SG_ 504 BCmDRLState 1;
BA_ "GenSigTimeoutMsg_HU_High_X445" SG_ 504 BCmDRLState 0;
BA_ "GenSigTimeoutMsg_HU_Mid_X445" SG_ 504 BCmDRLState 0;
BA_ "GenSigTimeoutTime_HU_High_X445" SG_ 504 BCmDRLState 0;
BA_ "GenSigTimeoutTime_HU_Mid_X445" SG_ 504 BCmDRLState 0;
BA_ "GenSigTimeoutMsg_IVI" SG_ 504 BCmDRLState 0;
BA_ "GenSigTimeoutTime_IVI" SG_ 504 BCmDRLState 0;
BA_ "GenSigTimeoutTime_HU_Mid_X451" SG_ 504 BCmMoodLightState 0;
BA_ "GenSigTimeoutTime_HU_High_X451" SG_ 504 BCmMoodLightState 0;
BA_ "GenSigTimeoutTime_HU_B" SG_ 504 BCmMoodLightState 0;
BA_ "GenSigTimeoutTime_HU_A" SG_ 504 BCmMoodLightState 0;
BA_ "GenSigTimeoutMsg_HU_Mid_X451" SG_ 504 BCmMoodLightState 0;
BA_ "GenSigTimeoutMsg_HU_High_X451" SG_ 504 BCmMoodLightState 0;
BA_ "GenSigTimeoutMsg_HU_B" SG_ 504 BCmMoodLightState 0;
BA_ "GenSigTimeoutMsg_HU_A" SG_ 504 BCmMoodLightState 0;
BA_ "GenSigSendType" SG_ 504 BCmMoodLightState 1;
BA_ "GenSigTimeoutMsg_HU_High_X445" SG_ 504 BCmMoodLightState 0;
BA_ "GenSigTimeoutMsg_HU_Mid_X445" SG_ 504 BCmMoodLightState 0;
BA_ "GenSigTimeoutTime_HU_High_X445" SG_ 504 BCmMoodLightState 0;
BA_ "GenSigTimeoutTime_HU_Mid_X445" SG_ 504 BCmMoodLightState 0;
BA_ "GenSigTimeoutMsg_IVI" SG_ 504 BCmMoodLightState 0;
BA_ "GenSigTimeoutTime_IVI" SG_ 504 BCmMoodLightState 0;
BA_ "GenSigTimeoutTime_HU_Mid_X451" SG_ 504 BCmUcsData 0;
BA_ "GenSigTimeoutTime_HU_High_X451" SG_ 504 BCmUcsData 0;
BA_ "GenSigTimeoutTime_HU_B" SG_ 504 BCmUcsData 0;
BA_ "GenSigTimeoutTime_HU_A" SG_ 504 BCmUcsData 0;
BA_ "GenSigTimeoutMsg_HU_Mid_X451" SG_ 504 BCmUcsData 0;
BA_ "GenSigTimeoutMsg_HU_High_X451" SG_ 504 BCmUcsData 0;
BA_ "GenSigTimeoutMsg_HU_B" SG_ 504 BCmUcsData 0;
BA_ "GenSigTimeoutMsg_HU_A" SG_ 504 BCmUcsData 0;
BA_ "GenSigStartValue" SG_ 504 BCmUcsData 2;
BA_ "GenSigSendType" SG_ 504 BCmUcsData 1;
BA_ "GenSigTimeoutMsg_HU_High_X445" SG_ 504 BCmUcsData 0;
BA_ "GenSigTimeoutMsg_HU_Mid_X445" SG_ 504 BCmUcsData 0;
BA_ "GenSigTimeoutTime_HU_High_X445" SG_ 504 BCmUcsData 0;
BA_ "GenSigTimeoutTime_HU_Mid_X445" SG_ 504 BCmUcsData 0;
BA_ "GenSigTimeoutMsg_IVI" SG_ 504 BCmUcsData 0;
BA_ "GenSigTimeoutTime_IVI" SG_ 504 BCmUcsData 0;
BA_ "GenSigTimeoutTime_HU_Mid_X451" SG_ 505 BCmMoodLightAllAreaActiveValue 0;
BA_ "GenSigTimeoutTime_HU_High_X451" SG_ 505 BCmMoodLightAllAreaActiveValue 0;
BA_ "GenSigTimeoutTime_HU_B" SG_ 505 BCmMoodLightAllAreaActiveValue 0;
BA_ "GenSigTimeoutTime_HU_A" SG_ 505 BCmMoodLightAllAreaActiveValue 0;
BA_ "GenSigTimeoutMsg_HU_Mid_X451" SG_ 505 BCmMoodLightAllAreaActiveValue 0;
BA_ "GenSigTimeoutMsg_HU_High_X451" SG_ 505 BCmMoodLightAllAreaActiveValue 0;
BA_ "GenSigTimeoutMsg_HU_B" SG_ 505 BCmMoodLightAllAreaActiveValue 0;
BA_ "GenSigTimeoutMsg_HU_A" SG_ 505 BCmMoodLightAllAreaActiveValue 0;
BA_ "GenSigStartValue" SG_ 505 BCmMoodLightAllAreaActiveValue 1;
BA_ "GenSigSendType" SG_ 505 BCmMoodLightAllAreaActiveValue 1;
BA_ "GenSigTimeoutMsg_HU_High_X445" SG_ 505 BCmMoodLightAllAreaActiveValue 0;
BA_ "GenSigTimeoutMsg_HU_Mid_X445" SG_ 505 BCmMoodLightAllAreaActiveValue 0;
BA_ "GenSigTimeoutTime_HU_High_X445" SG_ 505 BCmMoodLightAllAreaActiveValue 0;
BA_ "GenSigTimeoutTime_HU_Mid_X445" SG_ 505 BCmMoodLightAllAreaActiveValue 0;
BA_ "GenSigTimeoutMsg_IVI" SG_ 505 BCmMoodLightAllAreaActiveValue 0;
BA_ "GenSigTimeoutTime_IVI" SG_ 505 BCmMoodLightAllAreaActiveValue 0;
BA_ "GenSigTimeoutTime_HU_Mid_X451" SG_ 505 BCmMoodLightIllumSelActiveVal 0;
BA_ "GenSigTimeoutTime_HU_High_X451" SG_ 505 BCmMoodLightIllumSelActiveVal 0;
BA_ "GenSigTimeoutTime_HU_B" SG_ 505 BCmMoodLightIllumSelActiveVal 0;
BA_ "GenSigTimeoutTime_HU_A" SG_ 505 BCmMoodLightIllumSelActiveVal 0;
BA_ "GenSigTimeoutMsg_HU_Mid_X451" SG_ 505 BCmMoodLightIllumSelActiveVal 0;
BA_ "GenSigTimeoutMsg_HU_High_X451" SG_ 505 BCmMoodLightIllumSelActiveVal 0;
BA_ "GenSigTimeoutMsg_HU_B" SG_ 505 BCmMoodLightIllumSelActiveVal 0;
BA_ "GenSigTimeoutMsg_HU_A" SG_ 505 BCmMoodLightIllumSelActiveVal 0;
BA_ "GenSigStartValue" SG_ 505 BCmMoodLightIllumSelActiveVal 5;
BA_ "GenSigSendType" SG_ 505 BCmMoodLightIllumSelActiveVal 1;
BA_ "GenSigTimeoutMsg_HU_High_X445" SG_ 505 BCmMoodLightIllumSelActiveVal 0;
BA_ "GenSigTimeoutMsg_HU_Mid_X445" SG_ 505 BCmMoodLightIllumSelActiveVal 0;
BA_ "GenSigTimeoutTime_HU_High_X445" SG_ 505 BCmMoodLightIllumSelActiveVal 0;
BA_ "GenSigTimeoutTime_HU_Mid_X445" SG_ 505 BCmMoodLightIllumSelActiveVal 0;
BA_ "GenSigTimeoutMsg_IVI" SG_ 505 BCmMoodLightIllumSelActiveVal 0;
BA_ "GenSigTimeoutTime_IVI" SG_ 505 BCmMoodLightIllumSelActiveVal 0;
BA_ "GenSigTimeoutTime_HU_Mid_X451" SG_ 505 BCmMoodLightActiveColour 0;
BA_ "GenSigTimeoutTime_HU_High_X451" SG_ 505 BCmMoodLightActiveColour 0;
BA_ "GenSigTimeoutTime_HU_B" SG_ 505 BCmMoodLightActiveColour 0;
BA_ "GenSigTimeoutTime_HU_A" SG_ 505 BCmMoodLightActiveColour 0;
BA_ "GenSigTimeoutMsg_HU_Mid_X451" SG_ 505 BCmMoodLightActiveColour 0;
BA_ "GenSigTimeoutMsg_HU_High_X451" SG_ 505 BCmMoodLightActiveColour 0;
BA_ "GenSigTimeoutMsg_HU_B" SG_ 505 BCmMoodLightActiveColour 0;
BA_ "GenSigTimeoutMsg_HU_A" SG_ 505 BCmMoodLightActiveColour 0;
BA_ "GenSigStartValue" SG_ 505 BCmMoodLightActiveColour 1;
BA_ "GenSigSendType" SG_ 505 BCmMoodLightActiveColour 1;
BA_ "GenSigTimeoutMsg_HU_High_X445" SG_ 505 BCmMoodLightActiveColour 0;
BA_ "GenSigTimeoutMsg_HU_Mid_X445" SG_ 505 BCmMoodLightActiveColour 0;
BA_ "GenSigTimeoutTime_HU_High_X445" SG_ 505 BCmMoodLightActiveColour 0;
BA_ "GenSigTimeoutTime_HU_Mid_X445" SG_ 505 BCmMoodLightActiveColour 0;
BA_ "GenSigTimeoutMsg_IVI" SG_ 505 BCmMoodLightActiveColour 0;
BA_ "GenSigTimeoutTime_IVI" SG_ 505 BCmMoodLightActiveColour 0;
BA_ "GenSigTimeoutTime_HU_Mid_X451" SG_ 505 BCmMoodLightRearAreaActiveValue 0;
BA_ "GenSigTimeoutTime_HU_High_X451" SG_ 505 BCmMoodLightRearAreaActiveValue 0;
BA_ "GenSigTimeoutTime_HU_B" SG_ 505 BCmMoodLightRearAreaActiveValue 0;
BA_ "GenSigTimeoutTime_HU_A" SG_ 505 BCmMoodLightRearAreaActiveValue 0;
BA_ "GenSigTimeoutMsg_HU_Mid_X451" SG_ 505 BCmMoodLightRearAreaActiveValue 0;
BA_ "GenSigTimeoutMsg_HU_High_X451" SG_ 505 BCmMoodLightRearAreaActiveValue 0;
BA_ "GenSigTimeoutMsg_HU_B" SG_ 505 BCmMoodLightRearAreaActiveValue 0;
BA_ "GenSigTimeoutMsg_HU_A" SG_ 505 BCmMoodLightRearAreaActiveValue 0;
BA_ "GenSigStartValue" SG_ 505 BCmMoodLightRearAreaActiveValue 1;
BA_ "GenSigSendType" SG_ 505 BCmMoodLightRearAreaActiveValue 1;
BA_ "GenSigTimeoutMsg_HU_High_X445" SG_ 505 BCmMoodLightRearAreaActiveValue 0;
BA_ "GenSigTimeoutMsg_HU_Mid_X445" SG_ 505 BCmMoodLightRearAreaActiveValue 0;
BA_ "GenSigTimeoutTime_HU_High_X445" SG_ 505 BCmMoodLightRearAreaActiveValue 0;
BA_ "GenSigTimeoutTime_HU_Mid_X445" SG_ 505 BCmMoodLightRearAreaActiveValue 0;
BA_ "GenSigTimeoutMsg_IVI" SG_ 505 BCmMoodLightRearAreaActiveValue 0;
BA_ "GenSigTimeoutTime_IVI" SG_ 505 BCmMoodLightRearAreaActiveValue 0;
BA_ "GenSigTimeoutTime_HU_Mid_X451" SG_ 505 BCmMoodLightFrontRHAreaActiveVal 0;
BA_ "GenSigTimeoutTime_HU_High_X451" SG_ 505 BCmMoodLightFrontRHAreaActiveVal 0;
BA_ "GenSigTimeoutTime_HU_B" SG_ 505 BCmMoodLightFrontRHAreaActiveVal 0;
BA_ "GenSigTimeoutTime_HU_A" SG_ 505 BCmMoodLightFrontRHAreaActiveVal 0;
BA_ "GenSigTimeoutMsg_HU_Mid_X451" SG_ 505 BCmMoodLightFrontRHAreaActiveVal 0;
BA_ "GenSigTimeoutMsg_HU_High_X451" SG_ 505 BCmMoodLightFrontRHAreaActiveVal 0;
BA_ "GenSigTimeoutMsg_HU_B" SG_ 505 BCmMoodLightFrontRHAreaActiveVal 0;
BA_ "GenSigTimeoutMsg_HU_A" SG_ 505 BCmMoodLightFrontRHAreaActiveVal 0;
BA_ "GenSigStartValue" SG_ 505 BCmMoodLightFrontRHAreaActiveVal 1;
BA_ "GenSigSendType" SG_ 505 BCmMoodLightFrontRHAreaActiveVal 1;
BA_ "GenSigTimeoutMsg_HU_High_X445" SG_ 505 BCmMoodLightFrontRHAreaActiveVal 0;
BA_ "GenSigTimeoutMsg_HU_Mid_X445" SG_ 505 BCmMoodLightFrontRHAreaActiveVal 0;
BA_ "GenSigTimeoutTime_HU_High_X445" SG_ 505 BCmMoodLightFrontRHAreaActiveVal 0;
BA_ "GenSigTimeoutTime_HU_Mid_X445" SG_ 505 BCmMoodLightFrontRHAreaActiveVal 0;
BA_ "GenSigTimeoutMsg_IVI" SG_ 505 BCmMoodLightFrontRHAreaActiveVal 0;
BA_ "GenSigTimeoutTime_IVI" SG_ 505 BCmMoodLightFrontRHAreaActiveVal 0;
BA_ "SystemSignalLongSymbol" SG_ 505 BCmMoodLightFrontRHAreaActiveVal "BCmMoodLightFrontRHAreaActiveValue";
BA_ "GenSigTimeoutTime_HU_Mid_X451" SG_ 505 BCmMoodLightFloorConsoleAreaActi 0;
BA_ "GenSigTimeoutTime_HU_High_X451" SG_ 505 BCmMoodLightFloorConsoleAreaActi 0;
BA_ "GenSigTimeoutTime_HU_B" SG_ 505 BCmMoodLightFloorConsoleAreaActi 0;
BA_ "GenSigTimeoutTime_HU_A" SG_ 505 BCmMoodLightFloorConsoleAreaActi 0;
BA_ "GenSigTimeoutMsg_HU_Mid_X451" SG_ 505 BCmMoodLightFloorConsoleAreaActi 0;
BA_ "GenSigTimeoutMsg_HU_High_X451" SG_ 505 BCmMoodLightFloorConsoleAreaActi 0;
BA_ "GenSigTimeoutMsg_HU_B" SG_ 505 BCmMoodLightFloorConsoleAreaActi 0;
BA_ "GenSigTimeoutMsg_HU_A" SG_ 505 BCmMoodLightFloorConsoleAreaActi 0;
BA_ "GenSigStartValue" SG_ 505 BCmMoodLightFloorConsoleAreaActi 1;
BA_ "GenSigSendType" SG_ 505 BCmMoodLightFloorConsoleAreaActi 1;
BA_ "GenSigTimeoutMsg_HU_High_X445" SG_ 505 BCmMoodLightFloorConsoleAreaActi 0;
BA_ "GenSigTimeoutMsg_HU_Mid_X445" SG_ 505 BCmMoodLightFloorConsoleAreaActi 0;
BA_ "GenSigTimeoutTime_HU_High_X445" SG_ 505 BCmMoodLightFloorConsoleAreaActi 0;
BA_ "GenSigTimeoutTime_HU_Mid_X445" SG_ 505 BCmMoodLightFloorConsoleAreaActi 0;
BA_ "GenSigTimeoutMsg_IVI" SG_ 505 BCmMoodLightFloorConsoleAreaActi 0;
BA_ "GenSigTimeoutTime_IVI" SG_ 505 BCmMoodLightFloorConsoleAreaActi 0;
BA_ "SystemSignalLongSymbol" SG_ 505 BCmMoodLightFloorConsoleAreaActi "BCmMoodLightFloorConsoleAreaActiveValue";
BA_ "GenSigTimeoutTime_HU_Mid_X451" SG_ 505 BCmMoodLightData 0;
BA_ "GenSigTimeoutTime_HU_High_X451" SG_ 505 BCmMoodLightData 0;
BA_ "GenSigTimeoutTime_HU_B" SG_ 505 BCmMoodLightData 0;
BA_ "GenSigTimeoutTime_HU_A" SG_ 505 BCmMoodLightData 0;
BA_ "GenSigTimeoutMsg_HU_Mid_X451" SG_ 505 BCmMoodLightData 0;
BA_ "GenSigTimeoutMsg_HU_High_X451" SG_ 505 BCmMoodLightData 0;
BA_ "GenSigTimeoutMsg_HU_B" SG_ 505 BCmMoodLightData 0;
BA_ "GenSigTimeoutMsg_HU_A" SG_ 505 BCmMoodLightData 0;
BA_ "GenSigStartValue" SG_ 505 BCmMoodLightData 2;
BA_ "GenSigSendType" SG_ 505 BCmMoodLightData 1;
BA_ "GenSigTimeoutMsg_HU_High_X445" SG_ 505 BCmMoodLightData 0;
BA_ "GenSigTimeoutMsg_HU_Mid_X445" SG_ 505 BCmMoodLightData 0;
BA_ "GenSigTimeoutTime_HU_High_X445" SG_ 505 BCmMoodLightData 0;
BA_ "GenSigTimeoutTime_HU_Mid_X445" SG_ 505 BCmMoodLightData 0;
BA_ "GenSigTimeoutMsg_IVI" SG_ 505 BCmMoodLightData 0;
BA_ "GenSigTimeoutTime_IVI" SG_ 505 BCmMoodLightData 0;
BA_ "GenSigTimeoutTime_HU_Mid_X451" SG_ 505 BCmMoodLightIllumPossibleLevels 0;
BA_ "GenSigTimeoutTime_HU_High_X451" SG_ 505 BCmMoodLightIllumPossibleLevels 0;
BA_ "GenSigTimeoutTime_HU_B" SG_ 505 BCmMoodLightIllumPossibleLevels 0;
BA_ "GenSigTimeoutTime_HU_A" SG_ 505 BCmMoodLightIllumPossibleLevels 0;
BA_ "GenSigTimeoutMsg_HU_Mid_X451" SG_ 505 BCmMoodLightIllumPossibleLevels 0;
BA_ "GenSigTimeoutMsg_HU_High_X451" SG_ 505 BCmMoodLightIllumPossibleLevels 0;
BA_ "GenSigTimeoutMsg_HU_B" SG_ 505 BCmMoodLightIllumPossibleLevels 0;
BA_ "GenSigTimeoutMsg_HU_A" SG_ 505 BCmMoodLightIllumPossibleLevels 0;
BA_ "GenSigStartValue" SG_ 505 BCmMoodLightIllumPossibleLevels 5;
BA_ "GenSigSendType" SG_ 505 BCmMoodLightIllumPossibleLevels 1;
BA_ "GenSigTimeoutMsg_HU_High_X445" SG_ 505 BCmMoodLightIllumPossibleLevels 0;
BA_ "GenSigTimeoutMsg_HU_Mid_X445" SG_ 505 BCmMoodLightIllumPossibleLevels 0;
BA_ "GenSigTimeoutTime_HU_High_X445" SG_ 505 BCmMoodLightIllumPossibleLevels 0;
BA_ "GenSigTimeoutTime_HU_Mid_X445" SG_ 505 BCmMoodLightIllumPossibleLevels 0;
BA_ "GenSigTimeoutMsg_IVI" SG_ 505 BCmMoodLightIllumPossibleLevels 0;
BA_ "GenSigTimeoutTime_IVI" SG_ 505 BCmMoodLightIllumPossibleLevels 0;
BA_ "GenSigTimeoutTime_HU_Mid_X451" SG_ 505 BCmMoodLightHotMagentaColorSelOn 0;
BA_ "GenSigTimeoutTime_HU_High_X451" SG_ 505 BCmMoodLightHotMagentaColorSelOn 0;
BA_ "GenSigTimeoutTime_HU_B" SG_ 505 BCmMoodLightHotMagentaColorSelOn 0;
BA_ "GenSigTimeoutTime_HU_A" SG_ 505 BCmMoodLightHotMagentaColorSelOn 0;
BA_ "GenSigTimeoutMsg_HU_Mid_X451" SG_ 505 BCmMoodLightHotMagentaColorSelOn 0;
BA_ "GenSigTimeoutMsg_HU_High_X451" SG_ 505 BCmMoodLightHotMagentaColorSelOn 0;
BA_ "GenSigTimeoutMsg_HU_B" SG_ 505 BCmMoodLightHotMagentaColorSelOn 0;
BA_ "GenSigTimeoutMsg_HU_A" SG_ 505 BCmMoodLightHotMagentaColorSelOn 0;
BA_ "GenSigSendType" SG_ 505 BCmMoodLightHotMagentaColorSelOn 1;
BA_ "GenSigTimeoutMsg_HU_High_X445" SG_ 505 BCmMoodLightHotMagentaColorSelOn 0;
BA_ "GenSigTimeoutMsg_HU_Mid_X445" SG_ 505 BCmMoodLightHotMagentaColorSelOn 0;
BA_ "GenSigTimeoutTime_HU_High_X445" SG_ 505 BCmMoodLightHotMagentaColorSelOn 0;
BA_ "GenSigTimeoutTime_HU_Mid_X445" SG_ 505 BCmMoodLightHotMagentaColorSelOn 0;
BA_ "GenSigTimeoutMsg_IVI" SG_ 505 BCmMoodLightHotMagentaColorSelOn 0;
BA_ "GenSigTimeoutTime_IVI" SG_ 505 BCmMoodLightHotMagentaColorSelOn 0;
BA_ "SystemSignalLongSymbol" SG_ 505 BCmMoodLightHotMagentaColorSelOn "BCmMoodLightHotMagentaColorSelOnHU";
BA_ "GenSigTimeoutTime_HU_Mid_X451" SG_ 505 BCmMoodLightGoldYellowColorSelOn 0;
BA_ "GenSigTimeoutTime_HU_High_X451" SG_ 505 BCmMoodLightGoldYellowColorSelOn 0;
BA_ "GenSigTimeoutTime_HU_B" SG_ 505 BCmMoodLightGoldYellowColorSelOn 0;
BA_ "GenSigTimeoutTime_HU_A" SG_ 505 BCmMoodLightGoldYellowColorSelOn 0;
BA_ "GenSigTimeoutMsg_HU_Mid_X451" SG_ 505 BCmMoodLightGoldYellowColorSelOn 0;
BA_ "GenSigTimeoutMsg_HU_High_X451" SG_ 505 BCmMoodLightGoldYellowColorSelOn 0;
BA_ "GenSigTimeoutMsg_HU_B" SG_ 505 BCmMoodLightGoldYellowColorSelOn 0;
BA_ "GenSigTimeoutMsg_HU_A" SG_ 505 BCmMoodLightGoldYellowColorSelOn 0;
BA_ "GenSigSendType" SG_ 505 BCmMoodLightGoldYellowColorSelOn 1;
BA_ "GenSigTimeoutMsg_HU_High_X445" SG_ 505 BCmMoodLightGoldYellowColorSelOn 0;
BA_ "GenSigTimeoutMsg_HU_Mid_X445" SG_ 505 BCmMoodLightGoldYellowColorSelOn 0;
BA_ "GenSigTimeoutTime_HU_High_X445" SG_ 505 BCmMoodLightGoldYellowColorSelOn 0;
BA_ "GenSigTimeoutTime_HU_Mid_X445" SG_ 505 BCmMoodLightGoldYellowColorSelOn 0;
BA_ "GenSigTimeoutMsg_IVI" SG_ 505 BCmMoodLightGoldYellowColorSelOn 0;
BA_ "GenSigTimeoutTime_IVI" SG_ 505 BCmMoodLightGoldYellowColorSelOn 0;
BA_ "SystemSignalLongSymbol" SG_ 505 BCmMoodLightGoldYellowColorSelOn "BCmMoodLightGoldYellowColorSelOnHU";
BA_ "GenSigTimeoutTime_HU_Mid_X451" SG_ 505 BCmMoodLightFrenchLimeColorSelOn 0;
BA_ "GenSigTimeoutTime_HU_High_X451" SG_ 505 BCmMoodLightFrenchLimeColorSelOn 0;
BA_ "GenSigTimeoutTime_HU_B" SG_ 505 BCmMoodLightFrenchLimeColorSelOn 0;
BA_ "GenSigTimeoutTime_HU_A" SG_ 505 BCmMoodLightFrenchLimeColorSelOn 0;
BA_ "GenSigTimeoutMsg_HU_Mid_X451" SG_ 505 BCmMoodLightFrenchLimeColorSelOn 0;
BA_ "GenSigTimeoutMsg_HU_High_X451" SG_ 505 BCmMoodLightFrenchLimeColorSelOn 0;
BA_ "GenSigTimeoutMsg_HU_B" SG_ 505 BCmMoodLightFrenchLimeColorSelOn 0;
BA_ "GenSigTimeoutMsg_HU_A" SG_ 505 BCmMoodLightFrenchLimeColorSelOn 0;
BA_ "GenSigSendType" SG_ 505 BCmMoodLightFrenchLimeColorSelOn 1;
BA_ "GenSigTimeoutMsg_HU_High_X445" SG_ 505 BCmMoodLightFrenchLimeColorSelOn 0;
BA_ "GenSigTimeoutMsg_HU_Mid_X445" SG_ 505 BCmMoodLightFrenchLimeColorSelOn 0;
BA_ "GenSigTimeoutTime_HU_High_X445" SG_ 505 BCmMoodLightFrenchLimeColorSelOn 0;
BA_ "GenSigTimeoutTime_HU_Mid_X445" SG_ 505 BCmMoodLightFrenchLimeColorSelOn 0;
BA_ "GenSigTimeoutMsg_IVI" SG_ 505 BCmMoodLightFrenchLimeColorSelOn 0;
BA_ "GenSigTimeoutTime_IVI" SG_ 505 BCmMoodLightFrenchLimeColorSelOn 0;
BA_ "SystemSignalLongSymbol" SG_ 505 BCmMoodLightFrenchLimeColorSelOn "BCmMoodLightFrenchLimeColorSelOnHU";
BA_ "GenSigTimeoutTime_HU_Mid_X451" SG_ 505 BCmMoodLightFrontLHAreaActiveVal 0;
BA_ "GenSigTimeoutTime_HU_High_X451" SG_ 505 BCmMoodLightFrontLHAreaActiveVal 0;
BA_ "GenSigTimeoutTime_HU_B" SG_ 505 BCmMoodLightFrontLHAreaActiveVal 0;
BA_ "GenSigTimeoutTime_HU_A" SG_ 505 BCmMoodLightFrontLHAreaActiveVal 0;
BA_ "GenSigTimeoutMsg_HU_Mid_X451" SG_ 505 BCmMoodLightFrontLHAreaActiveVal 0;
BA_ "GenSigTimeoutMsg_HU_High_X451" SG_ 505 BCmMoodLightFrontLHAreaActiveVal 0;
BA_ "GenSigTimeoutMsg_HU_B" SG_ 505 BCmMoodLightFrontLHAreaActiveVal 0;
BA_ "GenSigTimeoutMsg_HU_A" SG_ 505 BCmMoodLightFrontLHAreaActiveVal 0;
BA_ "GenSigStartValue" SG_ 505 BCmMoodLightFrontLHAreaActiveVal 1;
BA_ "GenSigSendType" SG_ 505 BCmMoodLightFrontLHAreaActiveVal 1;
BA_ "GenSigTimeoutMsg_HU_High_X445" SG_ 505 BCmMoodLightFrontLHAreaActiveVal 0;
BA_ "GenSigTimeoutMsg_HU_Mid_X445" SG_ 505 BCmMoodLightFrontLHAreaActiveVal 0;
BA_ "GenSigTimeoutTime_HU_High_X445" SG_ 505 BCmMoodLightFrontLHAreaActiveVal 0;
BA_ "GenSigTimeoutTime_HU_Mid_X445" SG_ 505 BCmMoodLightFrontLHAreaActiveVal 0;
BA_ "GenSigTimeoutMsg_IVI" SG_ 505 BCmMoodLightFrontLHAreaActiveVal 0;
BA_ "GenSigTimeoutTime_IVI" SG_ 505 BCmMoodLightFrontLHAreaActiveVal 0;
BA_ "SystemSignalLongSymbol" SG_ 505 BCmMoodLightFrontLHAreaActiveVal "BCmMoodLightFrontLHAreaActiveValue";
BA_ "GenSigTimeoutTime_HU_Mid_X451" SG_ 505 BCmMoodLightPossibleModes 0;
BA_ "GenSigTimeoutTime_HU_High_X451" SG_ 505 BCmMoodLightPossibleModes 0;
BA_ "GenSigTimeoutTime_HU_B" SG_ 505 BCmMoodLightPossibleModes 0;
BA_ "GenSigTimeoutTime_HU_A" SG_ 505 BCmMoodLightPossibleModes 0;
BA_ "GenSigTimeoutMsg_HU_Mid_X451" SG_ 505 BCmMoodLightPossibleModes 0;
BA_ "GenSigTimeoutMsg_HU_High_X451" SG_ 505 BCmMoodLightPossibleModes 0;
BA_ "GenSigTimeoutMsg_HU_B" SG_ 505 BCmMoodLightPossibleModes 0;
BA_ "GenSigTimeoutMsg_HU_A" SG_ 505 BCmMoodLightPossibleModes 0;
BA_ "GenSigStartValue" SG_ 505 BCmMoodLightPossibleModes 2;
BA_ "GenSigSendType" SG_ 505 BCmMoodLightPossibleModes 1;
BA_ "GenSigTimeoutMsg_HU_High_X445" SG_ 505 BCmMoodLightPossibleModes 0;
BA_ "GenSigTimeoutMsg_HU_Mid_X445" SG_ 505 BCmMoodLightPossibleModes 0;
BA_ "GenSigTimeoutTime_HU_High_X445" SG_ 505 BCmMoodLightPossibleModes 0;
BA_ "GenSigTimeoutTime_HU_Mid_X445" SG_ 505 BCmMoodLightPossibleModes 0;
BA_ "GenSigTimeoutMsg_IVI" SG_ 505 BCmMoodLightPossibleModes 0;
BA_ "GenSigTimeoutTime_IVI" SG_ 505 BCmMoodLightPossibleModes 0;
BA_ "GenSigTimeoutTime_HU_Mid_X451" SG_ 505 BCmMoodLightActiveModeValue 0;
BA_ "GenSigTimeoutTime_HU_High_X451" SG_ 505 BCmMoodLightActiveModeValue 0;
BA_ "GenSigTimeoutTime_HU_B" SG_ 505 BCmMoodLightActiveModeValue 0;
BA_ "GenSigTimeoutTime_HU_A" SG_ 505 BCmMoodLightActiveModeValue 0;
BA_ "GenSigTimeoutMsg_HU_Mid_X451" SG_ 505 BCmMoodLightActiveModeValue 0;
BA_ "GenSigTimeoutMsg_HU_High_X451" SG_ 505 BCmMoodLightActiveModeValue 0;
BA_ "GenSigTimeoutMsg_HU_B" SG_ 505 BCmMoodLightActiveModeValue 0;
BA_ "GenSigTimeoutMsg_HU_A" SG_ 505 BCmMoodLightActiveModeValue 0;
BA_ "GenSigSendType" SG_ 505 BCmMoodLightActiveModeValue 1;
BA_ "GenSigTimeoutMsg_HU_High_X445" SG_ 505 BCmMoodLightActiveModeValue 0;
BA_ "GenSigTimeoutMsg_HU_Mid_X445" SG_ 505 BCmMoodLightActiveModeValue 0;
BA_ "GenSigTimeoutTime_HU_High_X445" SG_ 505 BCmMoodLightActiveModeValue 0;
BA_ "GenSigTimeoutTime_HU_Mid_X445" SG_ 505 BCmMoodLightActiveModeValue 0;
BA_ "GenSigTimeoutMsg_IVI" SG_ 505 BCmMoodLightActiveModeValue 0;
BA_ "GenSigTimeoutTime_IVI" SG_ 505 BCmMoodLightActiveModeValue 0;
BA_ "GenSigTimeoutTime_HU_Mid_X451" SG_ 505 BCmMoodLightPolarBrightWhiteColo 0;
BA_ "GenSigTimeoutTime_HU_High_X451" SG_ 505 BCmMoodLightPolarBrightWhiteColo 0;
BA_ "GenSigTimeoutTime_HU_B" SG_ 505 BCmMoodLightPolarBrightWhiteColo 0;
BA_ "GenSigTimeoutTime_HU_A" SG_ 505 BCmMoodLightPolarBrightWhiteColo 0;
BA_ "GenSigTimeoutMsg_HU_Mid_X451" SG_ 505 BCmMoodLightPolarBrightWhiteColo 0;
BA_ "GenSigTimeoutMsg_HU_High_X451" SG_ 505 BCmMoodLightPolarBrightWhiteColo 0;
BA_ "GenSigTimeoutMsg_HU_B" SG_ 505 BCmMoodLightPolarBrightWhiteColo 0;
BA_ "GenSigTimeoutMsg_HU_A" SG_ 505 BCmMoodLightPolarBrightWhiteColo 0;
BA_ "GenSigSendType" SG_ 505 BCmMoodLightPolarBrightWhiteColo 1;
BA_ "GenSigTimeoutMsg_HU_High_X445" SG_ 505 BCmMoodLightPolarBrightWhiteColo 0;
BA_ "GenSigTimeoutMsg_HU_Mid_X445" SG_ 505 BCmMoodLightPolarBrightWhiteColo 0;
BA_ "GenSigTimeoutTime_HU_High_X445" SG_ 505 BCmMoodLightPolarBrightWhiteColo 0;
BA_ "GenSigTimeoutTime_HU_Mid_X445" SG_ 505 BCmMoodLightPolarBrightWhiteColo 0;
BA_ "GenSigTimeoutMsg_IVI" SG_ 505 BCmMoodLightPolarBrightWhiteColo 0;
BA_ "GenSigTimeoutTime_IVI" SG_ 505 BCmMoodLightPolarBrightWhiteColo 0;
BA_ "SystemSignalLongSymbol" SG_ 505 BCmMoodLightPolarBrightWhiteColo "BCmMoodLightPolarBrightWhiteColorSelOnHU";
BA_ "GenSigTimeoutTime_HU_Mid_X451" SG_ 505 BCmMoodLightAeroBlueColorSelOnHU 0;
BA_ "GenSigTimeoutTime_HU_High_X451" SG_ 505 BCmMoodLightAeroBlueColorSelOnHU 0;
BA_ "GenSigTimeoutTime_HU_B" SG_ 505 BCmMoodLightAeroBlueColorSelOnHU 0;
BA_ "GenSigTimeoutTime_HU_A" SG_ 505 BCmMoodLightAeroBlueColorSelOnHU 0;
BA_ "GenSigTimeoutMsg_HU_Mid_X451" SG_ 505 BCmMoodLightAeroBlueColorSelOnHU 0;
BA_ "GenSigTimeoutMsg_HU_High_X451" SG_ 505 BCmMoodLightAeroBlueColorSelOnHU 0;
BA_ "GenSigTimeoutMsg_HU_B" SG_ 505 BCmMoodLightAeroBlueColorSelOnHU 0;
BA_ "GenSigTimeoutMsg_HU_A" SG_ 505 BCmMoodLightAeroBlueColorSelOnHU 0;
BA_ "GenSigSendType" SG_ 505 BCmMoodLightAeroBlueColorSelOnHU 1;
BA_ "GenSigTimeoutMsg_HU_High_X445" SG_ 505 BCmMoodLightAeroBlueColorSelOnHU 0;
BA_ "GenSigTimeoutMsg_HU_Mid_X445" SG_ 505 BCmMoodLightAeroBlueColorSelOnHU 0;
BA_ "GenSigTimeoutTime_HU_High_X445" SG_ 505 BCmMoodLightAeroBlueColorSelOnHU 0;
BA_ "GenSigTimeoutTime_HU_Mid_X445" SG_ 505 BCmMoodLightAeroBlueColorSelOnHU 0;
BA_ "GenSigTimeoutMsg_IVI" SG_ 505 BCmMoodLightAeroBlueColorSelOnHU 0;
BA_ "GenSigTimeoutTime_IVI" SG_ 505 BCmMoodLightAeroBlueColorSelOnHU 0;
BA_ "GenSigTimeoutTime_HU_Mid_X451" SG_ 505 BCmMoodLightPurpleColorSelOnHU 0;
BA_ "GenSigTimeoutTime_HU_High_X451" SG_ 505 BCmMoodLightPurpleColorSelOnHU 0;
BA_ "GenSigTimeoutTime_HU_B" SG_ 505 BCmMoodLightPurpleColorSelOnHU 0;
BA_ "GenSigTimeoutTime_HU_A" SG_ 505 BCmMoodLightPurpleColorSelOnHU 0;
BA_ "GenSigTimeoutMsg_HU_Mid_X451" SG_ 505 BCmMoodLightPurpleColorSelOnHU 0;
BA_ "GenSigTimeoutMsg_HU_High_X451" SG_ 505 BCmMoodLightPurpleColorSelOnHU 0;
BA_ "GenSigTimeoutMsg_HU_B" SG_ 505 BCmMoodLightPurpleColorSelOnHU 0;
BA_ "GenSigTimeoutMsg_HU_A" SG_ 505 BCmMoodLightPurpleColorSelOnHU 0;
BA_ "GenSigSendType" SG_ 505 BCmMoodLightPurpleColorSelOnHU 1;
BA_ "GenSigTimeoutMsg_HU_High_X445" SG_ 505 BCmMoodLightPurpleColorSelOnHU 0;
BA_ "GenSigTimeoutMsg_HU_Mid_X445" SG_ 505 BCmMoodLightPurpleColorSelOnHU 0;
BA_ "GenSigTimeoutTime_HU_High_X445" SG_ 505 BCmMoodLightPurpleColorSelOnHU 0;
BA_ "GenSigTimeoutTime_HU_Mid_X445" SG_ 505 BCmMoodLightPurpleColorSelOnHU 0;
BA_ "GenSigTimeoutMsg_IVI" SG_ 505 BCmMoodLightPurpleColorSelOnHU 0;
BA_ "GenSigTimeoutTime_IVI" SG_ 505 BCmMoodLightPurpleColorSelOnHU 0;
BA_ "GenSigTimeoutTime_HU_Mid_X451" SG_ 505 BCmMoodLightFluorescentGreenColo 0;
BA_ "GenSigTimeoutTime_HU_High_X451" SG_ 505 BCmMoodLightFluorescentGreenColo 0;
BA_ "GenSigTimeoutTime_HU_B" SG_ 505 BCmMoodLightFluorescentGreenColo 0;
BA_ "GenSigTimeoutTime_HU_A" SG_ 505 BCmMoodLightFluorescentGreenColo 0;
BA_ "GenSigTimeoutMsg_HU_Mid_X451" SG_ 505 BCmMoodLightFluorescentGreenColo 0;
BA_ "GenSigTimeoutMsg_HU_High_X451" SG_ 505 BCmMoodLightFluorescentGreenColo 0;
BA_ "GenSigTimeoutMsg_HU_B" SG_ 505 BCmMoodLightFluorescentGreenColo 0;
BA_ "GenSigTimeoutMsg_HU_A" SG_ 505 BCmMoodLightFluorescentGreenColo 0;
BA_ "GenSigSendType" SG_ 505 BCmMoodLightFluorescentGreenColo 1;
BA_ "GenSigTimeoutMsg_HU_High_X445" SG_ 505 BCmMoodLightFluorescentGreenColo 0;
BA_ "GenSigTimeoutMsg_HU_Mid_X445" SG_ 505 BCmMoodLightFluorescentGreenColo 0;
BA_ "GenSigTimeoutTime_HU_High_X445" SG_ 505 BCmMoodLightFluorescentGreenColo 0;
BA_ "GenSigTimeoutTime_HU_Mid_X445" SG_ 505 BCmMoodLightFluorescentGreenColo 0;
BA_ "GenSigTimeoutMsg_IVI" SG_ 505 BCmMoodLightFluorescentGreenColo 0;
BA_ "GenSigTimeoutTime_IVI" SG_ 505 BCmMoodLightFluorescentGreenColo 0;
BA_ "SystemSignalLongSymbol" SG_ 505 BCmMoodLightFluorescentGreenColo "BCmMoodLightFluorescentGreenColorSelOnHU";
BA_ "GenSigTimeoutTime_HU_Mid_X451" SG_ 505 BCmMoodLightCyanBlueColorSelOnHU 0;
BA_ "GenSigTimeoutTime_HU_High_X451" SG_ 505 BCmMoodLightCyanBlueColorSelOnHU 0;
BA_ "GenSigTimeoutTime_HU_B" SG_ 505 BCmMoodLightCyanBlueColorSelOnHU 0;
BA_ "GenSigTimeoutTime_HU_A" SG_ 505 BCmMoodLightCyanBlueColorSelOnHU 0;
BA_ "GenSigTimeoutMsg_HU_Mid_X451" SG_ 505 BCmMoodLightCyanBlueColorSelOnHU 0;
BA_ "GenSigTimeoutMsg_HU_High_X451" SG_ 505 BCmMoodLightCyanBlueColorSelOnHU 0;
BA_ "GenSigTimeoutMsg_HU_B" SG_ 505 BCmMoodLightCyanBlueColorSelOnHU 0;
BA_ "GenSigTimeoutMsg_HU_A" SG_ 505 BCmMoodLightCyanBlueColorSelOnHU 0;
BA_ "GenSigSendType" SG_ 505 BCmMoodLightCyanBlueColorSelOnHU 1;
BA_ "GenSigTimeoutMsg_HU_High_X445" SG_ 505 BCmMoodLightCyanBlueColorSelOnHU 0;
BA_ "GenSigTimeoutMsg_HU_Mid_X445" SG_ 505 BCmMoodLightCyanBlueColorSelOnHU 0;
BA_ "GenSigTimeoutTime_HU_High_X445" SG_ 505 BCmMoodLightCyanBlueColorSelOnHU 0;
BA_ "GenSigTimeoutTime_HU_Mid_X445" SG_ 505 BCmMoodLightCyanBlueColorSelOnHU 0;
BA_ "GenSigTimeoutMsg_IVI" SG_ 505 BCmMoodLightCyanBlueColorSelOnHU 0;
BA_ "GenSigTimeoutTime_IVI" SG_ 505 BCmMoodLightCyanBlueColorSelOnHU 0;
BA_ "GenSigTimeoutTime_HU_Mid_X451" SG_ 505 BCmMoodLightCoolBlueColorSelOnHU 0;
BA_ "GenSigTimeoutTime_HU_High_X451" SG_ 505 BCmMoodLightCoolBlueColorSelOnHU 0;
BA_ "GenSigTimeoutTime_HU_B" SG_ 505 BCmMoodLightCoolBlueColorSelOnHU 0;
BA_ "GenSigTimeoutTime_HU_A" SG_ 505 BCmMoodLightCoolBlueColorSelOnHU 0;
BA_ "GenSigTimeoutMsg_HU_Mid_X451" SG_ 505 BCmMoodLightCoolBlueColorSelOnHU 0;
BA_ "GenSigTimeoutMsg_HU_High_X451" SG_ 505 BCmMoodLightCoolBlueColorSelOnHU 0;
BA_ "GenSigTimeoutMsg_HU_B" SG_ 505 BCmMoodLightCoolBlueColorSelOnHU 0;
BA_ "GenSigTimeoutMsg_HU_A" SG_ 505 BCmMoodLightCoolBlueColorSelOnHU 0;
BA_ "GenSigSendType" SG_ 505 BCmMoodLightCoolBlueColorSelOnHU 1;
BA_ "GenSigTimeoutMsg_HU_High_X445" SG_ 505 BCmMoodLightCoolBlueColorSelOnHU 0;
BA_ "GenSigTimeoutMsg_HU_Mid_X445" SG_ 505 BCmMoodLightCoolBlueColorSelOnHU 0;
BA_ "GenSigTimeoutTime_HU_High_X445" SG_ 505 BCmMoodLightCoolBlueColorSelOnHU 0;
BA_ "GenSigTimeoutTime_HU_Mid_X445" SG_ 505 BCmMoodLightCoolBlueColorSelOnHU 0;
BA_ "GenSigTimeoutMsg_IVI" SG_ 505 BCmMoodLightCoolBlueColorSelOnHU 0;
BA_ "GenSigTimeoutTime_IVI" SG_ 505 BCmMoodLightCoolBlueColorSelOnHU 0;
BA_ "GenSigTimeoutTime_HU_Mid_X451" SG_ 505 BCmMoodLightIvoryOFFWhiteColorSe 0;
BA_ "GenSigTimeoutTime_HU_High_X451" SG_ 505 BCmMoodLightIvoryOFFWhiteColorSe 0;
BA_ "GenSigTimeoutTime_HU_B" SG_ 505 BCmMoodLightIvoryOFFWhiteColorSe 0;
BA_ "GenSigTimeoutTime_HU_A" SG_ 505 BCmMoodLightIvoryOFFWhiteColorSe 0;
BA_ "GenSigTimeoutMsg_HU_Mid_X451" SG_ 505 BCmMoodLightIvoryOFFWhiteColorSe 0;
BA_ "GenSigTimeoutMsg_HU_High_X451" SG_ 505 BCmMoodLightIvoryOFFWhiteColorSe 0;
BA_ "GenSigTimeoutMsg_HU_B" SG_ 505 BCmMoodLightIvoryOFFWhiteColorSe 0;
BA_ "GenSigTimeoutMsg_HU_A" SG_ 505 BCmMoodLightIvoryOFFWhiteColorSe 0;
BA_ "GenSigSendType" SG_ 505 BCmMoodLightIvoryOFFWhiteColorSe 1;
BA_ "GenSigTimeoutMsg_HU_High_X445" SG_ 505 BCmMoodLightIvoryOFFWhiteColorSe 0;
BA_ "GenSigTimeoutMsg_HU_Mid_X445" SG_ 505 BCmMoodLightIvoryOFFWhiteColorSe 0;
BA_ "GenSigTimeoutTime_HU_High_X445" SG_ 505 BCmMoodLightIvoryOFFWhiteColorSe 0;
BA_ "GenSigTimeoutTime_HU_Mid_X445" SG_ 505 BCmMoodLightIvoryOFFWhiteColorSe 0;
BA_ "GenSigTimeoutMsg_IVI" SG_ 505 BCmMoodLightIvoryOFFWhiteColorSe 0;
BA_ "GenSigTimeoutTime_IVI" SG_ 505 BCmMoodLightIvoryOFFWhiteColorSe 0;
BA_ "SystemSignalLongSymbol" SG_ 505 BCmMoodLightIvoryOFFWhiteColorSe "BCmMoodLightIvoryOFFWhiteColorSelOnHU";
BA_ "GenSigTimeoutTime_HU_Mid_X451" SG_ 505 BCmMoodLightIceBlueColorSelOnHU 0;
BA_ "GenSigTimeoutTime_HU_High_X451" SG_ 505 BCmMoodLightIceBlueColorSelOnHU 0;
BA_ "GenSigTimeoutTime_HU_B" SG_ 505 BCmMoodLightIceBlueColorSelOnHU 0;
BA_ "GenSigTimeoutTime_HU_A" SG_ 505 BCmMoodLightIceBlueColorSelOnHU 0;
BA_ "GenSigTimeoutMsg_HU_Mid_X451" SG_ 505 BCmMoodLightIceBlueColorSelOnHU 0;
BA_ "GenSigTimeoutMsg_HU_High_X451" SG_ 505 BCmMoodLightIceBlueColorSelOnHU 0;
BA_ "GenSigTimeoutMsg_HU_B" SG_ 505 BCmMoodLightIceBlueColorSelOnHU 0;
BA_ "GenSigTimeoutMsg_HU_A" SG_ 505 BCmMoodLightIceBlueColorSelOnHU 0;
BA_ "GenSigSendType" SG_ 505 BCmMoodLightIceBlueColorSelOnHU 1;
BA_ "GenSigTimeoutMsg_HU_High_X445" SG_ 505 BCmMoodLightIceBlueColorSelOnHU 0;
BA_ "GenSigTimeoutMsg_HU_Mid_X445" SG_ 505 BCmMoodLightIceBlueColorSelOnHU 0;
BA_ "GenSigTimeoutTime_HU_High_X445" SG_ 505 BCmMoodLightIceBlueColorSelOnHU 0;
BA_ "GenSigTimeoutTime_HU_Mid_X445" SG_ 505 BCmMoodLightIceBlueColorSelOnHU 0;
BA_ "GenSigTimeoutMsg_IVI" SG_ 505 BCmMoodLightIceBlueColorSelOnHU 0;
BA_ "GenSigTimeoutTime_IVI" SG_ 505 BCmMoodLightIceBlueColorSelOnHU 0;
BA_ "GenSigTimeoutTime_HU_Mid_X451" SG_ 505 BCmMoodLightTuscanRedColorSelOnH 0;
BA_ "GenSigTimeoutTime_HU_High_X451" SG_ 505 BCmMoodLightTuscanRedColorSelOnH 0;
BA_ "GenSigTimeoutTime_HU_B" SG_ 505 BCmMoodLightTuscanRedColorSelOnH 0;
BA_ "GenSigTimeoutTime_HU_A" SG_ 505 BCmMoodLightTuscanRedColorSelOnH 0;
BA_ "GenSigTimeoutMsg_HU_Mid_X451" SG_ 505 BCmMoodLightTuscanRedColorSelOnH 0;
BA_ "GenSigTimeoutMsg_HU_High_X451" SG_ 505 BCmMoodLightTuscanRedColorSelOnH 0;
BA_ "GenSigTimeoutMsg_HU_B" SG_ 505 BCmMoodLightTuscanRedColorSelOnH 0;
BA_ "GenSigTimeoutMsg_HU_A" SG_ 505 BCmMoodLightTuscanRedColorSelOnH 0;
BA_ "GenSigSendType" SG_ 505 BCmMoodLightTuscanRedColorSelOnH 1;
BA_ "GenSigTimeoutMsg_HU_High_X445" SG_ 505 BCmMoodLightTuscanRedColorSelOnH 0;
BA_ "GenSigTimeoutMsg_HU_Mid_X445" SG_ 505 BCmMoodLightTuscanRedColorSelOnH 0;
BA_ "GenSigTimeoutTime_HU_High_X445" SG_ 505 BCmMoodLightTuscanRedColorSelOnH 0;
BA_ "GenSigTimeoutTime_HU_Mid_X445" SG_ 505 BCmMoodLightTuscanRedColorSelOnH 0;
BA_ "GenSigTimeoutMsg_IVI" SG_ 505 BCmMoodLightTuscanRedColorSelOnH 0;
BA_ "GenSigTimeoutTime_IVI" SG_ 505 BCmMoodLightTuscanRedColorSelOnH 0;
BA_ "SystemSignalLongSymbol" SG_ 505 BCmMoodLightTuscanRedColorSelOnH "BCmMoodLightTuscanRedColorSelOnHU";
BA_ "GenSigTimeoutTime_HU_Mid_X451" SG_ 505 BCmMoodLightTealGreenColorSelOnH 0;
BA_ "GenSigTimeoutTime_HU_High_X451" SG_ 505 BCmMoodLightTealGreenColorSelOnH 0;
BA_ "GenSigTimeoutTime_HU_B" SG_ 505 BCmMoodLightTealGreenColorSelOnH 0;
BA_ "GenSigTimeoutTime_HU_A" SG_ 505 BCmMoodLightTealGreenColorSelOnH 0;
BA_ "GenSigTimeoutMsg_HU_Mid_X451" SG_ 505 BCmMoodLightTealGreenColorSelOnH 0;
BA_ "GenSigTimeoutMsg_HU_High_X451" SG_ 505 BCmMoodLightTealGreenColorSelOnH 0;
BA_ "GenSigTimeoutMsg_HU_B" SG_ 505 BCmMoodLightTealGreenColorSelOnH 0;
BA_ "GenSigTimeoutMsg_HU_A" SG_ 505 BCmMoodLightTealGreenColorSelOnH 0;
BA_ "GenSigSendType" SG_ 505 BCmMoodLightTealGreenColorSelOnH 1;
BA_ "GenSigTimeoutMsg_HU_High_X445" SG_ 505 BCmMoodLightTealGreenColorSelOnH 0;
BA_ "GenSigTimeoutMsg_HU_Mid_X445" SG_ 505 BCmMoodLightTealGreenColorSelOnH 0;
BA_ "GenSigTimeoutTime_HU_High_X445" SG_ 505 BCmMoodLightTealGreenColorSelOnH 0;
BA_ "GenSigTimeoutTime_HU_Mid_X445" SG_ 505 BCmMoodLightTealGreenColorSelOnH 0;
BA_ "GenSigTimeoutMsg_IVI" SG_ 505 BCmMoodLightTealGreenColorSelOnH 0;
BA_ "GenSigTimeoutTime_IVI" SG_ 505 BCmMoodLightTealGreenColorSelOnH 0;
BA_ "SystemSignalLongSymbol" SG_ 505 BCmMoodLightTealGreenColorSelOnH "BCmMoodLightTealGreenColorSelOnHU";
BA_ "GenSigTimeoutTime_HU_Mid_X451" SG_ 505 BCmMoodLightRubyRedColorSelOnHU 0;
BA_ "GenSigTimeoutTime_HU_High_X451" SG_ 505 BCmMoodLightRubyRedColorSelOnHU 0;
BA_ "GenSigTimeoutTime_HU_B" SG_ 505 BCmMoodLightRubyRedColorSelOnHU 0;
BA_ "GenSigTimeoutTime_HU_A" SG_ 505 BCmMoodLightRubyRedColorSelOnHU 0;
BA_ "GenSigTimeoutMsg_HU_Mid_X451" SG_ 505 BCmMoodLightRubyRedColorSelOnHU 0;
BA_ "GenSigTimeoutMsg_HU_High_X451" SG_ 505 BCmMoodLightRubyRedColorSelOnHU 0;
BA_ "GenSigTimeoutMsg_HU_B" SG_ 505 BCmMoodLightRubyRedColorSelOnHU 0;
BA_ "GenSigTimeoutMsg_HU_A" SG_ 505 BCmMoodLightRubyRedColorSelOnHU 0;
BA_ "GenSigSendType" SG_ 505 BCmMoodLightRubyRedColorSelOnHU 1;
BA_ "GenSigTimeoutMsg_HU_High_X445" SG_ 505 BCmMoodLightRubyRedColorSelOnHU 0;
BA_ "GenSigTimeoutMsg_HU_Mid_X445" SG_ 505 BCmMoodLightRubyRedColorSelOnHU 0;
BA_ "GenSigTimeoutTime_HU_High_X445" SG_ 505 BCmMoodLightRubyRedColorSelOnHU 0;
BA_ "GenSigTimeoutTime_HU_Mid_X445" SG_ 505 BCmMoodLightRubyRedColorSelOnHU 0;
BA_ "GenSigTimeoutMsg_IVI" SG_ 505 BCmMoodLightRubyRedColorSelOnHU 0;
BA_ "GenSigTimeoutTime_IVI" SG_ 505 BCmMoodLightRubyRedColorSelOnHU 0;
BA_ "GenSigTimeoutTime_HU_Mid_X451" SG_ 505 BCmMoodLightOrangeColorSelOnHU 0;
BA_ "GenSigTimeoutTime_HU_High_X451" SG_ 505 BCmMoodLightOrangeColorSelOnHU 0;
BA_ "GenSigTimeoutTime_HU_B" SG_ 505 BCmMoodLightOrangeColorSelOnHU 0;
BA_ "GenSigTimeoutTime_HU_A" SG_ 505 BCmMoodLightOrangeColorSelOnHU 0;
BA_ "GenSigTimeoutMsg_HU_Mid_X451" SG_ 505 BCmMoodLightOrangeColorSelOnHU 0;
BA_ "GenSigTimeoutMsg_HU_High_X451" SG_ 505 BCmMoodLightOrangeColorSelOnHU 0;
BA_ "GenSigTimeoutMsg_HU_B" SG_ 505 BCmMoodLightOrangeColorSelOnHU 0;
BA_ "GenSigTimeoutMsg_HU_A" SG_ 505 BCmMoodLightOrangeColorSelOnHU 0;
BA_ "GenSigSendType" SG_ 505 BCmMoodLightOrangeColorSelOnHU 1;
BA_ "GenSigTimeoutMsg_HU_High_X445" SG_ 505 BCmMoodLightOrangeColorSelOnHU 0;
BA_ "GenSigTimeoutMsg_HU_Mid_X445" SG_ 505 BCmMoodLightOrangeColorSelOnHU 0;
BA_ "GenSigTimeoutTime_HU_High_X445" SG_ 505 BCmMoodLightOrangeColorSelOnHU 0;
BA_ "GenSigTimeoutTime_HU_Mid_X445" SG_ 505 BCmMoodLightOrangeColorSelOnHU 0;
BA_ "GenSigTimeoutMsg_IVI" SG_ 505 BCmMoodLightOrangeColorSelOnHU 0;
BA_ "GenSigTimeoutTime_IVI" SG_ 505 BCmMoodLightOrangeColorSelOnHU 0;
BA_ "GenSigTimeoutTime_HU_Mid_X451" SG_ 505 BCmMoodLightPurpleTaupeColorSelO 0;
BA_ "GenSigTimeoutTime_HU_High_X451" SG_ 505 BCmMoodLightPurpleTaupeColorSelO 0;
BA_ "GenSigTimeoutTime_HU_B" SG_ 505 BCmMoodLightPurpleTaupeColorSelO 0;
BA_ "GenSigTimeoutTime_HU_A" SG_ 505 BCmMoodLightPurpleTaupeColorSelO 0;
BA_ "GenSigTimeoutMsg_HU_Mid_X451" SG_ 505 BCmMoodLightPurpleTaupeColorSelO 0;
BA_ "GenSigTimeoutMsg_HU_High_X451" SG_ 505 BCmMoodLightPurpleTaupeColorSelO 0;
BA_ "GenSigTimeoutMsg_HU_B" SG_ 505 BCmMoodLightPurpleTaupeColorSelO 0;
BA_ "GenSigTimeoutMsg_HU_A" SG_ 505 BCmMoodLightPurpleTaupeColorSelO 0;
BA_ "GenSigSendType" SG_ 505 BCmMoodLightPurpleTaupeColorSelO 1;
BA_ "GenSigTimeoutMsg_HU_High_X445" SG_ 505 BCmMoodLightPurpleTaupeColorSelO 0;
BA_ "GenSigTimeoutMsg_HU_Mid_X445" SG_ 505 BCmMoodLightPurpleTaupeColorSelO 0;
BA_ "GenSigTimeoutTime_HU_High_X445" SG_ 505 BCmMoodLightPurpleTaupeColorSelO 0;
BA_ "GenSigTimeoutTime_HU_Mid_X445" SG_ 505 BCmMoodLightPurpleTaupeColorSelO 0;
BA_ "GenSigTimeoutMsg_IVI" SG_ 505 BCmMoodLightPurpleTaupeColorSelO 0;
BA_ "GenSigTimeoutTime_IVI" SG_ 505 BCmMoodLightPurpleTaupeColorSelO 0;
BA_ "SystemSignalLongSymbol" SG_ 505 BCmMoodLightPurpleTaupeColorSelO "BCmMoodLightPurpleTaupeColorSelOnHU";
BA_ "GenSigTimeoutTime_HU_Mid_X451" SG_ 505 BCmMoodLightLocationSel 0;
BA_ "GenSigTimeoutTime_HU_High_X451" SG_ 505 BCmMoodLightLocationSel 0;
BA_ "GenSigTimeoutTime_HU_B" SG_ 505 BCmMoodLightLocationSel 0;
BA_ "GenSigTimeoutTime_HU_A" SG_ 505 BCmMoodLightLocationSel 0;
BA_ "GenSigTimeoutMsg_HU_Mid_X451" SG_ 505 BCmMoodLightLocationSel 0;
BA_ "GenSigTimeoutMsg_HU_High_X451" SG_ 505 BCmMoodLightLocationSel 0;
BA_ "GenSigTimeoutMsg_HU_B" SG_ 505 BCmMoodLightLocationSel 0;
BA_ "GenSigTimeoutMsg_HU_A" SG_ 505 BCmMoodLightLocationSel 0;
BA_ "GenSigSendType" SG_ 505 BCmMoodLightLocationSel 1;
BA_ "GenSigTimeoutMsg_HU_High_X445" SG_ 505 BCmMoodLightLocationSel 0;
BA_ "GenSigTimeoutMsg_HU_Mid_X445" SG_ 505 BCmMoodLightLocationSel 0;
BA_ "GenSigTimeoutTime_HU_High_X445" SG_ 505 BCmMoodLightLocationSel 0;
BA_ "GenSigTimeoutTime_HU_Mid_X445" SG_ 505 BCmMoodLightLocationSel 0;
BA_ "GenSigTimeoutMsg_IVI" SG_ 505 BCmMoodLightLocationSel 0;
BA_ "GenSigTimeoutTime_IVI" SG_ 505 BCmMoodLightLocationSel 0;
BA_ "GenSigTimeoutTime_HU_Mid_X451" SG_ 505 BCmMoodLightAllAreaSelOnHU 0;
BA_ "GenSigTimeoutTime_HU_High_X451" SG_ 505 BCmMoodLightAllAreaSelOnHU 0;
BA_ "GenSigTimeoutTime_HU_B" SG_ 505 BCmMoodLightAllAreaSelOnHU 0;
BA_ "GenSigTimeoutTime_HU_A" SG_ 505 BCmMoodLightAllAreaSelOnHU 0;
BA_ "GenSigTimeoutMsg_HU_Mid_X451" SG_ 505 BCmMoodLightAllAreaSelOnHU 0;
BA_ "GenSigTimeoutMsg_HU_High_X451" SG_ 505 BCmMoodLightAllAreaSelOnHU 0;
BA_ "GenSigTimeoutMsg_HU_B" SG_ 505 BCmMoodLightAllAreaSelOnHU 0;
BA_ "GenSigTimeoutMsg_HU_A" SG_ 505 BCmMoodLightAllAreaSelOnHU 0;
BA_ "GenSigSendType" SG_ 505 BCmMoodLightAllAreaSelOnHU 1;
BA_ "GenSigTimeoutMsg_HU_High_X445" SG_ 505 BCmMoodLightAllAreaSelOnHU 0;
BA_ "GenSigTimeoutMsg_HU_Mid_X445" SG_ 505 BCmMoodLightAllAreaSelOnHU 0;
BA_ "GenSigTimeoutTime_HU_High_X445" SG_ 505 BCmMoodLightAllAreaSelOnHU 0;
BA_ "GenSigTimeoutTime_HU_Mid_X445" SG_ 505 BCmMoodLightAllAreaSelOnHU 0;
BA_ "GenSigTimeoutMsg_IVI" SG_ 505 BCmMoodLightAllAreaSelOnHU 0;
BA_ "GenSigTimeoutTime_IVI" SG_ 505 BCmMoodLightAllAreaSelOnHU 0;
BA_ "GenSigTimeoutTime_HU_Mid_X451" SG_ 505 BCmMoodLightFrontLHAreaSelOnHU 0;
BA_ "GenSigTimeoutTime_HU_High_X451" SG_ 505 BCmMoodLightFrontLHAreaSelOnHU 0;
BA_ "GenSigTimeoutTime_HU_B" SG_ 505 BCmMoodLightFrontLHAreaSelOnHU 0;
BA_ "GenSigTimeoutTime_HU_A" SG_ 505 BCmMoodLightFrontLHAreaSelOnHU 0;
BA_ "GenSigTimeoutMsg_HU_Mid_X451" SG_ 505 BCmMoodLightFrontLHAreaSelOnHU 0;
BA_ "GenSigTimeoutMsg_HU_High_X451" SG_ 505 BCmMoodLightFrontLHAreaSelOnHU 0;
BA_ "GenSigTimeoutMsg_HU_B" SG_ 505 BCmMoodLightFrontLHAreaSelOnHU 0;
BA_ "GenSigTimeoutMsg_HU_A" SG_ 505 BCmMoodLightFrontLHAreaSelOnHU 0;
BA_ "GenSigSendType" SG_ 505 BCmMoodLightFrontLHAreaSelOnHU 1;
BA_ "GenSigTimeoutMsg_HU_High_X445" SG_ 505 BCmMoodLightFrontLHAreaSelOnHU 0;
BA_ "GenSigTimeoutMsg_HU_Mid_X445" SG_ 505 BCmMoodLightFrontLHAreaSelOnHU 0;
BA_ "GenSigTimeoutTime_HU_High_X445" SG_ 505 BCmMoodLightFrontLHAreaSelOnHU 0;
BA_ "GenSigTimeoutTime_HU_Mid_X445" SG_ 505 BCmMoodLightFrontLHAreaSelOnHU 0;
BA_ "GenSigTimeoutMsg_IVI" SG_ 505 BCmMoodLightFrontLHAreaSelOnHU 0;
BA_ "GenSigTimeoutTime_IVI" SG_ 505 BCmMoodLightFrontLHAreaSelOnHU 0;
BA_ "GenSigTimeoutTime_HU_Mid_X451" SG_ 505 BCmMoodLightRearAreaSelOnHU 0;
BA_ "GenSigTimeoutTime_HU_High_X451" SG_ 505 BCmMoodLightRearAreaSelOnHU 0;
BA_ "GenSigTimeoutTime_HU_B" SG_ 505 BCmMoodLightRearAreaSelOnHU 0;
BA_ "GenSigTimeoutTime_HU_A" SG_ 505 BCmMoodLightRearAreaSelOnHU 0;
BA_ "GenSigTimeoutMsg_HU_Mid_X451" SG_ 505 BCmMoodLightRearAreaSelOnHU 0;
BA_ "GenSigTimeoutMsg_HU_High_X451" SG_ 505 BCmMoodLightRearAreaSelOnHU 0;
BA_ "GenSigTimeoutMsg_HU_B" SG_ 505 BCmMoodLightRearAreaSelOnHU 0;
BA_ "GenSigTimeoutMsg_HU_A" SG_ 505 BCmMoodLightRearAreaSelOnHU 0;
BA_ "GenSigSendType" SG_ 505 BCmMoodLightRearAreaSelOnHU 1;
BA_ "GenSigTimeoutMsg_HU_High_X445" SG_ 505 BCmMoodLightRearAreaSelOnHU 0;
BA_ "GenSigTimeoutMsg_HU_Mid_X445" SG_ 505 BCmMoodLightRearAreaSelOnHU 0;
BA_ "GenSigTimeoutTime_HU_High_X445" SG_ 505 BCmMoodLightRearAreaSelOnHU 0;
BA_ "GenSigTimeoutTime_HU_Mid_X445" SG_ 505 BCmMoodLightRearAreaSelOnHU 0;
BA_ "GenSigTimeoutMsg_IVI" SG_ 505 BCmMoodLightRearAreaSelOnHU 0;
BA_ "GenSigTimeoutTime_IVI" SG_ 505 BCmMoodLightRearAreaSelOnHU 0;
BA_ "GenSigTimeoutTime_HU_Mid_X451" SG_ 505 BCmMoodLightFloorConsoleAreaSelO 0;
BA_ "GenSigTimeoutTime_HU_High_X451" SG_ 505 BCmMoodLightFloorConsoleAreaSelO 0;
BA_ "GenSigTimeoutTime_HU_B" SG_ 505 BCmMoodLightFloorConsoleAreaSelO 0;
BA_ "GenSigTimeoutTime_HU_A" SG_ 505 BCmMoodLightFloorConsoleAreaSelO 0;
BA_ "GenSigTimeoutMsg_HU_Mid_X451" SG_ 505 BCmMoodLightFloorConsoleAreaSelO 0;
BA_ "GenSigTimeoutMsg_HU_High_X451" SG_ 505 BCmMoodLightFloorConsoleAreaSelO 0;
BA_ "GenSigTimeoutMsg_HU_B" SG_ 505 BCmMoodLightFloorConsoleAreaSelO 0;
BA_ "GenSigTimeoutMsg_HU_A" SG_ 505 BCmMoodLightFloorConsoleAreaSelO 0;
BA_ "GenSigSendType" SG_ 505 BCmMoodLightFloorConsoleAreaSelO 1;
BA_ "GenSigTimeoutMsg_HU_High_X445" SG_ 505 BCmMoodLightFloorConsoleAreaSelO 0;
BA_ "GenSigTimeoutMsg_HU_Mid_X445" SG_ 505 BCmMoodLightFloorConsoleAreaSelO 0;
BA_ "GenSigTimeoutTime_HU_High_X445" SG_ 505 BCmMoodLightFloorConsoleAreaSelO 0;
BA_ "GenSigTimeoutTime_HU_Mid_X445" SG_ 505 BCmMoodLightFloorConsoleAreaSelO 0;
BA_ "GenSigTimeoutMsg_IVI" SG_ 505 BCmMoodLightFloorConsoleAreaSelO 0;
BA_ "GenSigTimeoutTime_IVI" SG_ 505 BCmMoodLightFloorConsoleAreaSelO 0;
BA_ "SystemSignalLongSymbol" SG_ 505 BCmMoodLightFloorConsoleAreaSelO "BCmMoodLightFloorConsoleAreaSelOnHU";
BA_ "GenSigTimeoutTime_HU_Mid_X451" SG_ 505 BCmMoodLightState 0;
BA_ "GenSigTimeoutTime_HU_High_X451" SG_ 505 BCmMoodLightState 0;
BA_ "GenSigTimeoutTime_HU_B" SG_ 505 BCmMoodLightState 0;
BA_ "GenSigTimeoutTime_HU_A" SG_ 505 BCmMoodLightState 0;
BA_ "GenSigTimeoutMsg_HU_Mid_X451" SG_ 505 BCmMoodLightState 0;
BA_ "GenSigTimeoutMsg_HU_High_X451" SG_ 505 BCmMoodLightState 0;
BA_ "GenSigTimeoutMsg_HU_B" SG_ 505 BCmMoodLightState 0;
BA_ "GenSigTimeoutMsg_HU_A" SG_ 505 BCmMoodLightState 0;
BA_ "GenSigSendType" SG_ 505 BCmMoodLightState 1;
BA_ "GenSigTimeoutMsg_HU_High_X445" SG_ 505 BCmMoodLightState 0;
BA_ "GenSigTimeoutMsg_HU_Mid_X445" SG_ 505 BCmMoodLightState 0;
BA_ "GenSigTimeoutTime_HU_High_X445" SG_ 505 BCmMoodLightState 0;
BA_ "GenSigTimeoutTime_HU_Mid_X445" SG_ 505 BCmMoodLightState 0;
BA_ "GenSigTimeoutMsg_IVI" SG_ 505 BCmMoodLightState 0;
BA_ "GenSigTimeoutTime_IVI" SG_ 505 BCmMoodLightState 0;
BA_ "GenSigTimeoutTime_HU_Mid_X451" SG_ 505 BCmMoodLightFrontRHAreaSelOnHU 0;
BA_ "GenSigTimeoutTime_HU_High_X451" SG_ 505 BCmMoodLightFrontRHAreaSelOnHU 0;
BA_ "GenSigTimeoutTime_HU_B" SG_ 505 BCmMoodLightFrontRHAreaSelOnHU 0;
BA_ "GenSigTimeoutTime_HU_A" SG_ 505 BCmMoodLightFrontRHAreaSelOnHU 0;
BA_ "GenSigTimeoutMsg_HU_Mid_X451" SG_ 505 BCmMoodLightFrontRHAreaSelOnHU 0;
BA_ "GenSigTimeoutMsg_HU_High_X451" SG_ 505 BCmMoodLightFrontRHAreaSelOnHU 0;
BA_ "GenSigTimeoutMsg_HU_B" SG_ 505 BCmMoodLightFrontRHAreaSelOnHU 0;
BA_ "GenSigTimeoutMsg_HU_A" SG_ 505 BCmMoodLightFrontRHAreaSelOnHU 0;
BA_ "GenSigSendType" SG_ 505 BCmMoodLightFrontRHAreaSelOnHU 1;
BA_ "GenSigTimeoutMsg_HU_High_X445" SG_ 505 BCmMoodLightFrontRHAreaSelOnHU 0;
BA_ "GenSigTimeoutMsg_HU_Mid_X445" SG_ 505 BCmMoodLightFrontRHAreaSelOnHU 0;
BA_ "GenSigTimeoutTime_HU_High_X445" SG_ 505 BCmMoodLightFrontRHAreaSelOnHU 0;
BA_ "GenSigTimeoutTime_HU_Mid_X445" SG_ 505 BCmMoodLightFrontRHAreaSelOnHU 0;
BA_ "GenSigTimeoutMsg_IVI" SG_ 505 BCmMoodLightFrontRHAreaSelOnHU 0;
BA_ "GenSigTimeoutTime_IVI" SG_ 505 BCmMoodLightFrontRHAreaSelOnHU 0;
BA_ "GenSigTimeoutTime_HU_Mid_X451" SG_ 506 HuAutoRelockActiveSignalVal 0;
BA_ "GenSigTimeoutTime_HU_High_X451" SG_ 506 HuAutoRelockActiveSignalVal 0;
BA_ "GenSigTimeoutTime_HU_B" SG_ 506 HuAutoRelockActiveSignalVal 0;
BA_ "GenSigTimeoutTime_HU_A" SG_ 506 HuAutoRelockActiveSignalVal 0;
BA_ "GenSigTimeoutMsg_HU_Mid_X451" SG_ 506 HuAutoRelockActiveSignalVal 0;
BA_ "GenSigTimeoutMsg_HU_High_X451" SG_ 506 HuAutoRelockActiveSignalVal 0;
BA_ "GenSigTimeoutMsg_HU_B" SG_ 506 HuAutoRelockActiveSignalVal 0;
BA_ "GenSigTimeoutMsg_HU_A" SG_ 506 HuAutoRelockActiveSignalVal 0;
BA_ "GenSigSendType" SG_ 506 HuAutoRelockActiveSignalVal 1;
BA_ "GenSigTimeoutMsg_HU_High_X445" SG_ 506 HuAutoRelockActiveSignalVal 0;
BA_ "GenSigTimeoutMsg_HU_Mid_X445" SG_ 506 HuAutoRelockActiveSignalVal 0;
BA_ "GenSigTimeoutTime_HU_High_X445" SG_ 506 HuAutoRelockActiveSignalVal 0;
BA_ "GenSigTimeoutTime_HU_Mid_X445" SG_ 506 HuAutoRelockActiveSignalVal 0;
BA_ "GenSigTimeoutMsg_IVI" SG_ 506 HuAutoRelockActiveSignalVal 0;
BA_ "GenSigTimeoutTime_IVI" SG_ 506 HuAutoRelockActiveSignalVal 0;
BA_ "GenSigTimeoutTime_HU_Mid_X451" SG_ 506 HuFMhActiveSignalVal 0;
BA_ "GenSigTimeoutTime_HU_High_X451" SG_ 506 HuFMhActiveSignalVal 0;
BA_ "GenSigTimeoutTime_HU_B" SG_ 506 HuFMhActiveSignalVal 0;
BA_ "GenSigTimeoutTime_HU_A" SG_ 506 HuFMhActiveSignalVal 0;
BA_ "GenSigTimeoutMsg_HU_Mid_X451" SG_ 506 HuFMhActiveSignalVal 0;
BA_ "GenSigTimeoutMsg_HU_High_X451" SG_ 506 HuFMhActiveSignalVal 0;
BA_ "GenSigTimeoutMsg_HU_B" SG_ 506 HuFMhActiveSignalVal 0;
BA_ "GenSigTimeoutMsg_HU_A" SG_ 506 HuFMhActiveSignalVal 0;
BA_ "GenSigSendType" SG_ 506 HuFMhActiveSignalVal 1;
BA_ "GenSigTimeoutMsg_HU_High_X445" SG_ 506 HuFMhActiveSignalVal 0;
BA_ "GenSigTimeoutMsg_HU_Mid_X445" SG_ 506 HuFMhActiveSignalVal 0;
BA_ "GenSigTimeoutTime_HU_High_X445" SG_ 506 HuFMhActiveSignalVal 0;
BA_ "GenSigTimeoutTime_HU_Mid_X445" SG_ 506 HuFMhActiveSignalVal 0;
BA_ "GenSigTimeoutMsg_IVI" SG_ 506 HuFMhActiveSignalVal 0;
BA_ "GenSigTimeoutTime_IVI" SG_ 506 HuFMhActiveSignalVal 0;
BA_ "GenSigTimeoutTime_HU_Mid_X451" SG_ 506 HuFMhSignalVal1 0;
BA_ "GenSigTimeoutTime_HU_High_X451" SG_ 506 HuFMhSignalVal1 0;
BA_ "GenSigTimeoutTime_HU_B" SG_ 506 HuFMhSignalVal1 0;
BA_ "GenSigTimeoutTime_HU_A" SG_ 506 HuFMhSignalVal1 0;
BA_ "GenSigTimeoutMsg_HU_Mid_X451" SG_ 506 HuFMhSignalVal1 0;
BA_ "GenSigTimeoutMsg_HU_High_X451" SG_ 506 HuFMhSignalVal1 0;
BA_ "GenSigTimeoutMsg_HU_B" SG_ 506 HuFMhSignalVal1 0;
BA_ "GenSigTimeoutMsg_HU_A" SG_ 506 HuFMhSignalVal1 0;
BA_ "GenSigSendType" SG_ 506 HuFMhSignalVal1 1;
BA_ "GenSigTimeoutMsg_HU_High_X445" SG_ 506 HuFMhSignalVal1 0;
BA_ "GenSigTimeoutMsg_HU_Mid_X445" SG_ 506 HuFMhSignalVal1 0;
BA_ "GenSigTimeoutTime_HU_High_X445" SG_ 506 HuFMhSignalVal1 0;
BA_ "GenSigTimeoutTime_HU_Mid_X445" SG_ 506 HuFMhSignalVal1 0;
BA_ "GenSigTimeoutMsg_IVI" SG_ 506 HuFMhSignalVal1 0;
BA_ "GenSigTimeoutTime_IVI" SG_ 506 HuFMhSignalVal1 0;
BA_ "GenSigTimeoutTime_HU_Mid_X451" SG_ 506 HuVehLockHornReqActiveSignalVal 0;
BA_ "GenSigTimeoutTime_HU_High_X451" SG_ 506 HuVehLockHornReqActiveSignalVal 0;
BA_ "GenSigTimeoutTime_HU_B" SG_ 506 HuVehLockHornReqActiveSignalVal 0;
BA_ "GenSigTimeoutTime_HU_A" SG_ 506 HuVehLockHornReqActiveSignalVal 0;
BA_ "GenSigTimeoutMsg_HU_Mid_X451" SG_ 506 HuVehLockHornReqActiveSignalVal 0;
BA_ "GenSigTimeoutMsg_HU_High_X451" SG_ 506 HuVehLockHornReqActiveSignalVal 0;
BA_ "GenSigTimeoutMsg_HU_B" SG_ 506 HuVehLockHornReqActiveSignalVal 0;
BA_ "GenSigTimeoutMsg_HU_A" SG_ 506 HuVehLockHornReqActiveSignalVal 0;
BA_ "GenSigSendType" SG_ 506 HuVehLockHornReqActiveSignalVal 1;
BA_ "GenSigTimeoutMsg_HU_High_X445" SG_ 506 HuVehLockHornReqActiveSignalVal 0;
BA_ "GenSigTimeoutMsg_HU_Mid_X445" SG_ 506 HuVehLockHornReqActiveSignalVal 0;
BA_ "GenSigTimeoutTime_HU_High_X445" SG_ 506 HuVehLockHornReqActiveSignalVal 0;
BA_ "GenSigTimeoutTime_HU_Mid_X445" SG_ 506 HuVehLockHornReqActiveSignalVal 0;
BA_ "GenSigTimeoutMsg_IVI" SG_ 506 HuVehLockHornReqActiveSignalVal 0;
BA_ "GenSigTimeoutTime_IVI" SG_ 506 HuVehLockHornReqActiveSignalVal 0;
BA_ "GenSigTimeoutTime_HU_Mid_X451" SG_ 506 HuApproachLampActiveSignalVal 0;
BA_ "GenSigTimeoutTime_HU_High_X451" SG_ 506 HuApproachLampActiveSignalVal 0;
BA_ "GenSigTimeoutTime_HU_B" SG_ 506 HuApproachLampActiveSignalVal 0;
BA_ "GenSigTimeoutTime_HU_A" SG_ 506 HuApproachLampActiveSignalVal 0;
BA_ "GenSigTimeoutMsg_HU_Mid_X451" SG_ 506 HuApproachLampActiveSignalVal 0;
BA_ "GenSigTimeoutMsg_HU_High_X451" SG_ 506 HuApproachLampActiveSignalVal 0;
BA_ "GenSigTimeoutMsg_HU_B" SG_ 506 HuApproachLampActiveSignalVal 0;
BA_ "GenSigTimeoutMsg_HU_A" SG_ 506 HuApproachLampActiveSignalVal 0;
BA_ "GenSigSendType" SG_ 506 HuApproachLampActiveSignalVal 1;
BA_ "GenSigTimeoutMsg_HU_High_X445" SG_ 506 HuApproachLampActiveSignalVal 0;
BA_ "GenSigTimeoutMsg_HU_Mid_X445" SG_ 506 HuApproachLampActiveSignalVal 0;
BA_ "GenSigTimeoutTime_HU_High_X445" SG_ 506 HuApproachLampActiveSignalVal 0;
BA_ "GenSigTimeoutTime_HU_Mid_X445" SG_ 506 HuApproachLampActiveSignalVal 0;
BA_ "GenSigTimeoutMsg_IVI" SG_ 506 HuApproachLampActiveSignalVal 0;
BA_ "GenSigTimeoutTime_IVI" SG_ 506 HuApproachLampActiveSignalVal 0;
BA_ "GenSigTimeoutTime_HU_Mid_X451" SG_ 506 HuFMhSignalVal2 0;
BA_ "GenSigTimeoutTime_HU_High_X451" SG_ 506 HuFMhSignalVal2 0;
BA_ "GenSigTimeoutTime_HU_B" SG_ 506 HuFMhSignalVal2 0;
BA_ "GenSigTimeoutTime_HU_A" SG_ 506 HuFMhSignalVal2 0;
BA_ "GenSigTimeoutMsg_HU_Mid_X451" SG_ 506 HuFMhSignalVal2 0;
BA_ "GenSigTimeoutMsg_HU_High_X451" SG_ 506 HuFMhSignalVal2 0;
BA_ "GenSigTimeoutMsg_HU_B" SG_ 506 HuFMhSignalVal2 0;
BA_ "GenSigTimeoutMsg_HU_A" SG_ 506 HuFMhSignalVal2 0;
BA_ "GenSigSendType" SG_ 506 HuFMhSignalVal2 1;
BA_ "GenSigTimeoutMsg_HU_High_X445" SG_ 506 HuFMhSignalVal2 0;
BA_ "GenSigTimeoutMsg_HU_Mid_X445" SG_ 506 HuFMhSignalVal2 0;
BA_ "GenSigTimeoutTime_HU_High_X445" SG_ 506 HuFMhSignalVal2 0;
BA_ "GenSigTimeoutTime_HU_Mid_X445" SG_ 506 HuFMhSignalVal2 0;
BA_ "GenSigTimeoutMsg_IVI" SG_ 506 HuFMhSignalVal2 0;
BA_ "GenSigTimeoutTime_IVI" SG_ 506 HuFMhSignalVal2 0;
BA_ "GenSigTimeoutTime_HU_Mid_X451" SG_ 506 HuDriveAwayLockingActiveSignalVa 0;
BA_ "GenSigTimeoutTime_HU_High_X451" SG_ 506 HuDriveAwayLockingActiveSignalVa 0;
BA_ "GenSigTimeoutTime_HU_B" SG_ 506 HuDriveAwayLockingActiveSignalVa 0;
BA_ "GenSigTimeoutTime_HU_A" SG_ 506 HuDriveAwayLockingActiveSignalVa 0;
BA_ "GenSigTimeoutMsg_HU_Mid_X451" SG_ 506 HuDriveAwayLockingActiveSignalVa 0;
BA_ "GenSigTimeoutMsg_HU_High_X451" SG_ 506 HuDriveAwayLockingActiveSignalVa 0;
BA_ "GenSigTimeoutMsg_HU_B" SG_ 506 HuDriveAwayLockingActiveSignalVa 0;
BA_ "GenSigTimeoutMsg_HU_A" SG_ 506 HuDriveAwayLockingActiveSignalVa 0;
BA_ "GenSigSendType" SG_ 506 HuDriveAwayLockingActiveSignalVa 1;
BA_ "GenSigTimeoutMsg_HU_High_X445" SG_ 506 HuDriveAwayLockingActiveSignalVa 0;
BA_ "GenSigTimeoutMsg_HU_Mid_X445" SG_ 506 HuDriveAwayLockingActiveSignalVa 0;
BA_ "GenSigTimeoutTime_HU_High_X445" SG_ 506 HuDriveAwayLockingActiveSignalVa 0;
BA_ "GenSigTimeoutTime_HU_Mid_X445" SG_ 506 HuDriveAwayLockingActiveSignalVa 0;
BA_ "GenSigTimeoutMsg_IVI" SG_ 506 HuDriveAwayLockingActiveSignalVa 0;
BA_ "GenSigTimeoutTime_IVI" SG_ 506 HuDriveAwayLockingActiveSignalVa 0;
BA_ "SystemSignalLongSymbol" SG_ 506 HuDriveAwayLockingActiveSignalVa "HuDriveAwayLockingActiveSignalVal";
BA_ "GenSigTimeoutTime_HU_Mid_X451" SG_ 506 HuRKeUnlockActiveSignalVal 0;
BA_ "GenSigTimeoutTime_HU_High_X451" SG_ 506 HuRKeUnlockActiveSignalVal 0;
BA_ "GenSigTimeoutTime_HU_B" SG_ 506 HuRKeUnlockActiveSignalVal 0;
BA_ "GenSigTimeoutTime_HU_A" SG_ 506 HuRKeUnlockActiveSignalVal 0;
BA_ "GenSigTimeoutMsg_HU_Mid_X451" SG_ 506 HuRKeUnlockActiveSignalVal 0;
BA_ "GenSigTimeoutMsg_HU_High_X451" SG_ 506 HuRKeUnlockActiveSignalVal 0;
BA_ "GenSigTimeoutMsg_HU_B" SG_ 506 HuRKeUnlockActiveSignalVal 0;
BA_ "GenSigTimeoutMsg_HU_A" SG_ 506 HuRKeUnlockActiveSignalVal 0;
BA_ "GenSigSendType" SG_ 506 HuRKeUnlockActiveSignalVal 1;
BA_ "GenSigTimeoutMsg_HU_High_X445" SG_ 506 HuRKeUnlockActiveSignalVal 0;
BA_ "GenSigTimeoutMsg_HU_Mid_X445" SG_ 506 HuRKeUnlockActiveSignalVal 0;
BA_ "GenSigTimeoutTime_HU_High_X445" SG_ 506 HuRKeUnlockActiveSignalVal 0;
BA_ "GenSigTimeoutTime_HU_Mid_X445" SG_ 506 HuRKeUnlockActiveSignalVal 0;
BA_ "GenSigTimeoutMsg_IVI" SG_ 506 HuRKeUnlockActiveSignalVal 0;
BA_ "GenSigTimeoutTime_IVI" SG_ 506 HuRKeUnlockActiveSignalVal 0;
BA_ "GenSigTimeoutTime_HU_Mid_X451" SG_ 506 HuPKeUnlockActiveSignalVal 0;
BA_ "GenSigTimeoutTime_HU_High_X451" SG_ 506 HuPKeUnlockActiveSignalVal 0;
BA_ "GenSigTimeoutTime_HU_B" SG_ 506 HuPKeUnlockActiveSignalVal 0;
BA_ "GenSigTimeoutTime_HU_A" SG_ 506 HuPKeUnlockActiveSignalVal 0;
BA_ "GenSigTimeoutMsg_HU_Mid_X451" SG_ 506 HuPKeUnlockActiveSignalVal 0;
BA_ "GenSigTimeoutMsg_HU_High_X451" SG_ 506 HuPKeUnlockActiveSignalVal 0;
BA_ "GenSigTimeoutMsg_HU_B" SG_ 506 HuPKeUnlockActiveSignalVal 0;
BA_ "GenSigTimeoutMsg_HU_A" SG_ 506 HuPKeUnlockActiveSignalVal 0;
BA_ "GenSigSendType" SG_ 506 HuPKeUnlockActiveSignalVal 1;
BA_ "GenSigTimeoutMsg_HU_High_X445" SG_ 506 HuPKeUnlockActiveSignalVal 0;
BA_ "GenSigTimeoutMsg_HU_Mid_X445" SG_ 506 HuPKeUnlockActiveSignalVal 0;
BA_ "GenSigTimeoutTime_HU_High_X445" SG_ 506 HuPKeUnlockActiveSignalVal 0;
BA_ "GenSigTimeoutTime_HU_Mid_X445" SG_ 506 HuPKeUnlockActiveSignalVal 0;
BA_ "GenSigTimeoutMsg_IVI" SG_ 506 HuPKeUnlockActiveSignalVal 0;
BA_ "GenSigTimeoutTime_IVI" SG_ 506 HuPKeUnlockActiveSignalVal 0;
BA_ "GenSigTimeoutTime_HU_Mid_X451" SG_ 506 HuFMhSignalVal3 0;
BA_ "GenSigTimeoutTime_HU_High_X451" SG_ 506 HuFMhSignalVal3 0;
BA_ "GenSigTimeoutTime_HU_B" SG_ 506 HuFMhSignalVal3 0;
BA_ "GenSigTimeoutTime_HU_A" SG_ 506 HuFMhSignalVal3 0;
BA_ "GenSigTimeoutMsg_HU_Mid_X451" SG_ 506 HuFMhSignalVal3 0;
BA_ "GenSigTimeoutMsg_HU_High_X451" SG_ 506 HuFMhSignalVal3 0;
BA_ "GenSigTimeoutMsg_HU_B" SG_ 506 HuFMhSignalVal3 0;
BA_ "GenSigTimeoutMsg_HU_A" SG_ 506 HuFMhSignalVal3 0;
BA_ "GenSigSendType" SG_ 506 HuFMhSignalVal3 1;
BA_ "GenSigTimeoutMsg_HU_High_X445" SG_ 506 HuFMhSignalVal3 0;
BA_ "GenSigTimeoutMsg_HU_Mid_X445" SG_ 506 HuFMhSignalVal3 0;
BA_ "GenSigTimeoutTime_HU_High_X445" SG_ 506 HuFMhSignalVal3 0;
BA_ "GenSigTimeoutTime_HU_Mid_X445" SG_ 506 HuFMhSignalVal3 0;
BA_ "GenSigTimeoutMsg_IVI" SG_ 506 HuFMhSignalVal3 0;
BA_ "GenSigTimeoutTime_IVI" SG_ 506 HuFMhSignalVal3 0;
BA_ "GenSigTimeoutTime_HU_Mid_X451" SG_ 506 BCmFactorySettingReq 0;
BA_ "GenSigTimeoutTime_HU_High_X451" SG_ 506 BCmFactorySettingReq 0;
BA_ "GenSigTimeoutTime_HU_B" SG_ 506 BCmFactorySettingReq 0;
BA_ "GenSigTimeoutTime_HU_A" SG_ 506 BCmFactorySettingReq 0;
BA_ "GenSigTimeoutMsg_HU_Mid_X451" SG_ 506 BCmFactorySettingReq 0;
BA_ "GenSigTimeoutMsg_HU_High_X451" SG_ 506 BCmFactorySettingReq 0;
BA_ "GenSigTimeoutMsg_HU_B" SG_ 506 BCmFactorySettingReq 0;
BA_ "GenSigTimeoutMsg_HU_A" SG_ 506 BCmFactorySettingReq 0;
BA_ "GenSigSendType" SG_ 506 BCmFactorySettingReq 1;
BA_ "GenSigTimeoutMsg_HU_High_X445" SG_ 506 BCmFactorySettingReq 0;
BA_ "GenSigTimeoutMsg_HU_Mid_X445" SG_ 506 BCmFactorySettingReq 0;
BA_ "GenSigTimeoutTime_HU_High_X445" SG_ 506 BCmFactorySettingReq 0;
BA_ "GenSigTimeoutTime_HU_Mid_X445" SG_ 506 BCmFactorySettingReq 0;
BA_ "GenSigTimeoutMsg_IVI" SG_ 506 BCmFactorySettingReq 0;
BA_ "GenSigTimeoutTime_IVI" SG_ 506 BCmFactorySettingReq 0;
BA_ "GenSigTimeoutTime_HU_Mid_X451" SG_ 506 HuApproachLampSignalVal1 0;
BA_ "GenSigTimeoutTime_HU_High_X451" SG_ 506 HuApproachLampSignalVal1 0;
BA_ "GenSigTimeoutTime_HU_B" SG_ 506 HuApproachLampSignalVal1 0;
BA_ "GenSigTimeoutTime_HU_A" SG_ 506 HuApproachLampSignalVal1 0;
BA_ "GenSigTimeoutMsg_HU_Mid_X451" SG_ 506 HuApproachLampSignalVal1 0;
BA_ "GenSigTimeoutMsg_HU_High_X451" SG_ 506 HuApproachLampSignalVal1 0;
BA_ "GenSigTimeoutMsg_HU_B" SG_ 506 HuApproachLampSignalVal1 0;
BA_ "GenSigTimeoutMsg_HU_A" SG_ 506 HuApproachLampSignalVal1 0;
BA_ "GenSigSendType" SG_ 506 HuApproachLampSignalVal1 1;
BA_ "GenSigTimeoutMsg_HU_High_X445" SG_ 506 HuApproachLampSignalVal1 0;
BA_ "GenSigTimeoutMsg_HU_Mid_X445" SG_ 506 HuApproachLampSignalVal1 0;
BA_ "GenSigTimeoutTime_HU_High_X445" SG_ 506 HuApproachLampSignalVal1 0;
BA_ "GenSigTimeoutTime_HU_Mid_X445" SG_ 506 HuApproachLampSignalVal1 0;
BA_ "GenSigTimeoutMsg_IVI" SG_ 506 HuApproachLampSignalVal1 0;
BA_ "GenSigTimeoutTime_IVI" SG_ 506 HuApproachLampSignalVal1 0;
BA_ "GenSigTimeoutTime_HU_Mid_X451" SG_ 506 HuDRLActiveSignalVal 0;
BA_ "GenSigTimeoutTime_HU_High_X451" SG_ 506 HuDRLActiveSignalVal 0;
BA_ "GenSigTimeoutTime_HU_B" SG_ 506 HuDRLActiveSignalVal 0;
BA_ "GenSigTimeoutTime_HU_A" SG_ 506 HuDRLActiveSignalVal 0;
BA_ "GenSigTimeoutMsg_HU_Mid_X451" SG_ 506 HuDRLActiveSignalVal 0;
BA_ "GenSigTimeoutMsg_HU_High_X451" SG_ 506 HuDRLActiveSignalVal 0;
BA_ "GenSigTimeoutMsg_HU_B" SG_ 506 HuDRLActiveSignalVal 0;
BA_ "GenSigTimeoutMsg_HU_A" SG_ 506 HuDRLActiveSignalVal 0;
BA_ "GenSigSendType" SG_ 506 HuDRLActiveSignalVal 1;
BA_ "GenSigTimeoutMsg_HU_High_X445" SG_ 506 HuDRLActiveSignalVal 0;
BA_ "GenSigTimeoutMsg_HU_Mid_X445" SG_ 506 HuDRLActiveSignalVal 0;
BA_ "GenSigTimeoutTime_HU_High_X445" SG_ 506 HuDRLActiveSignalVal 0;
BA_ "GenSigTimeoutTime_HU_Mid_X445" SG_ 506 HuDRLActiveSignalVal 0;
BA_ "GenSigTimeoutMsg_IVI" SG_ 506 HuDRLActiveSignalVal 0;
BA_ "GenSigTimeoutTime_IVI" SG_ 506 HuDRLActiveSignalVal 0;
BA_ "GenSigTimeoutTime_HU_Mid_X451" SG_ 506 HuQueryInfo 0;
BA_ "GenSigTimeoutTime_HU_High_X451" SG_ 506 HuQueryInfo 0;
BA_ "GenSigTimeoutTime_HU_B" SG_ 506 HuQueryInfo 0;
BA_ "GenSigTimeoutTime_HU_A" SG_ 506 HuQueryInfo 0;
BA_ "GenSigTimeoutMsg_HU_Mid_X451" SG_ 506 HuQueryInfo 0;
BA_ "GenSigTimeoutMsg_HU_High_X451" SG_ 506 HuQueryInfo 0;
BA_ "GenSigTimeoutMsg_HU_B" SG_ 506 HuQueryInfo 0;
BA_ "GenSigTimeoutMsg_HU_A" SG_ 506 HuQueryInfo 0;
BA_ "GenSigSendType" SG_ 506 HuQueryInfo 1;
BA_ "GenSigTimeoutMsg_HU_High_X445" SG_ 506 HuQueryInfo 0;
BA_ "GenSigTimeoutMsg_HU_Mid_X445" SG_ 506 HuQueryInfo 0;
BA_ "GenSigTimeoutTime_HU_High_X445" SG_ 506 HuQueryInfo 0;
BA_ "GenSigTimeoutTime_HU_Mid_X445" SG_ 506 HuQueryInfo 0;
BA_ "GenSigTimeoutMsg_IVI" SG_ 506 HuQueryInfo 0;
BA_ "GenSigTimeoutTime_IVI" SG_ 506 HuQueryInfo 0;
BA_ "GenSigTimeoutTime_HU_Mid_X451" SG_ 506 HuApproachLampSignalVal2 0;
BA_ "GenSigTimeoutTime_HU_High_X451" SG_ 506 HuApproachLampSignalVal2 0;
BA_ "GenSigTimeoutTime_HU_B" SG_ 506 HuApproachLampSignalVal2 0;
BA_ "GenSigTimeoutTime_HU_A" SG_ 506 HuApproachLampSignalVal2 0;
BA_ "GenSigTimeoutMsg_HU_Mid_X451" SG_ 506 HuApproachLampSignalVal2 0;
BA_ "GenSigTimeoutMsg_HU_High_X451" SG_ 506 HuApproachLampSignalVal2 0;
BA_ "GenSigTimeoutMsg_HU_B" SG_ 506 HuApproachLampSignalVal2 0;
BA_ "GenSigTimeoutMsg_HU_A" SG_ 506 HuApproachLampSignalVal2 0;
BA_ "GenSigSendType" SG_ 506 HuApproachLampSignalVal2 1;
BA_ "GenSigTimeoutMsg_HU_High_X445" SG_ 506 HuApproachLampSignalVal2 0;
BA_ "GenSigTimeoutMsg_HU_Mid_X445" SG_ 506 HuApproachLampSignalVal2 0;
BA_ "GenSigTimeoutTime_HU_High_X445" SG_ 506 HuApproachLampSignalVal2 0;
BA_ "GenSigTimeoutTime_HU_Mid_X445" SG_ 506 HuApproachLampSignalVal2 0;
BA_ "GenSigTimeoutMsg_IVI" SG_ 506 HuApproachLampSignalVal2 0;
BA_ "GenSigTimeoutTime_IVI" SG_ 506 HuApproachLampSignalVal2 0;
BA_ "GenSigTimeoutTime_HU_Mid_X451" SG_ 506 HuApproachLampSignalVal3 0;
BA_ "GenSigTimeoutTime_HU_High_X451" SG_ 506 HuApproachLampSignalVal3 0;
BA_ "GenSigTimeoutTime_HU_B" SG_ 506 HuApproachLampSignalVal3 0;
BA_ "GenSigTimeoutTime_HU_A" SG_ 506 HuApproachLampSignalVal3 0;
BA_ "GenSigTimeoutMsg_HU_Mid_X451" SG_ 506 HuApproachLampSignalVal3 0;
BA_ "GenSigTimeoutMsg_HU_High_X451" SG_ 506 HuApproachLampSignalVal3 0;
BA_ "GenSigTimeoutMsg_HU_B" SG_ 506 HuApproachLampSignalVal3 0;
BA_ "GenSigTimeoutMsg_HU_A" SG_ 506 HuApproachLampSignalVal3 0;
BA_ "GenSigSendType" SG_ 506 HuApproachLampSignalVal3 1;
BA_ "GenSigTimeoutMsg_HU_High_X445" SG_ 506 HuApproachLampSignalVal3 0;
BA_ "GenSigTimeoutMsg_HU_Mid_X445" SG_ 506 HuApproachLampSignalVal3 0;
BA_ "GenSigTimeoutTime_HU_High_X445" SG_ 506 HuApproachLampSignalVal3 0;
BA_ "GenSigTimeoutTime_HU_Mid_X445" SG_ 506 HuApproachLampSignalVal3 0;
BA_ "GenSigTimeoutMsg_IVI" SG_ 506 HuApproachLampSignalVal3 0;
BA_ "GenSigTimeoutTime_IVI" SG_ 506 HuApproachLampSignalVal3 0;
BA_ "GenSigTimeoutTime_HU_Mid_X451" SG_ 508 HuMoodLightAllAreaActiveValue 0;
BA_ "GenSigTimeoutTime_HU_High_X451" SG_ 508 HuMoodLightAllAreaActiveValue 0;
BA_ "GenSigTimeoutTime_HU_B" SG_ 508 HuMoodLightAllAreaActiveValue 0;
BA_ "GenSigTimeoutTime_HU_A" SG_ 508 HuMoodLightAllAreaActiveValue 0;
BA_ "GenSigTimeoutMsg_HU_Mid_X451" SG_ 508 HuMoodLightAllAreaActiveValue 0;
BA_ "GenSigTimeoutMsg_HU_High_X451" SG_ 508 HuMoodLightAllAreaActiveValue 0;
BA_ "GenSigTimeoutMsg_HU_B" SG_ 508 HuMoodLightAllAreaActiveValue 0;
BA_ "GenSigTimeoutMsg_HU_A" SG_ 508 HuMoodLightAllAreaActiveValue 0;
BA_ "GenSigStartValue" SG_ 508 HuMoodLightAllAreaActiveValue 1;
BA_ "GenSigSendType" SG_ 508 HuMoodLightAllAreaActiveValue 1;
BA_ "GenSigInactiveValue" SG_ 508 HuMoodLightAllAreaActiveValue 1;
BA_ "GenSigTimeoutMsg_HU_High_X445" SG_ 508 HuMoodLightAllAreaActiveValue 0;
BA_ "GenSigTimeoutMsg_HU_Mid_X445" SG_ 508 HuMoodLightAllAreaActiveValue 0;
BA_ "GenSigTimeoutTime_HU_High_X445" SG_ 508 HuMoodLightAllAreaActiveValue 0;
BA_ "GenSigTimeoutTime_HU_Mid_X445" SG_ 508 HuMoodLightAllAreaActiveValue 0;
BA_ "GenSigTimeoutMsg_IVI" SG_ 508 HuMoodLightAllAreaActiveValue 0;
BA_ "GenSigTimeoutTime_IVI" SG_ 508 HuMoodLightAllAreaActiveValue 0;
BA_ "GenSigTimeoutTime_HU_Mid_X451" SG_ 508 HuMoodLightIllumSelActiveValue 0;
BA_ "GenSigTimeoutTime_HU_High_X451" SG_ 508 HuMoodLightIllumSelActiveValue 0;
BA_ "GenSigTimeoutTime_HU_B" SG_ 508 HuMoodLightIllumSelActiveValue 0;
BA_ "GenSigTimeoutTime_HU_A" SG_ 508 HuMoodLightIllumSelActiveValue 0;
BA_ "GenSigTimeoutMsg_HU_Mid_X451" SG_ 508 HuMoodLightIllumSelActiveValue 0;
BA_ "GenSigTimeoutMsg_HU_High_X451" SG_ 508 HuMoodLightIllumSelActiveValue 0;
BA_ "GenSigTimeoutMsg_HU_B" SG_ 508 HuMoodLightIllumSelActiveValue 0;
BA_ "GenSigTimeoutMsg_HU_A" SG_ 508 HuMoodLightIllumSelActiveValue 0;
BA_ "GenSigSendType" SG_ 508 HuMoodLightIllumSelActiveValue 1;
BA_ "GenSigTimeoutMsg_HU_High_X445" SG_ 508 HuMoodLightIllumSelActiveValue 0;
BA_ "GenSigTimeoutMsg_HU_Mid_X445" SG_ 508 HuMoodLightIllumSelActiveValue 0;
BA_ "GenSigTimeoutTime_HU_High_X445" SG_ 508 HuMoodLightIllumSelActiveValue 0;
BA_ "GenSigTimeoutTime_HU_Mid_X445" SG_ 508 HuMoodLightIllumSelActiveValue 0;
BA_ "GenSigTimeoutMsg_IVI" SG_ 508 HuMoodLightIllumSelActiveValue 0;
BA_ "GenSigTimeoutTime_IVI" SG_ 508 HuMoodLightIllumSelActiveValue 0;
BA_ "GenSigTimeoutTime_HU_Mid_X451" SG_ 508 HuMoodLightActiveColourValue 0;
BA_ "GenSigTimeoutTime_HU_High_X451" SG_ 508 HuMoodLightActiveColourValue 0;
BA_ "GenSigTimeoutTime_HU_B" SG_ 508 HuMoodLightActiveColourValue 0;
BA_ "GenSigTimeoutTime_HU_A" SG_ 508 HuMoodLightActiveColourValue 0;
BA_ "GenSigTimeoutMsg_HU_Mid_X451" SG_ 508 HuMoodLightActiveColourValue 0;
BA_ "GenSigTimeoutMsg_HU_High_X451" SG_ 508 HuMoodLightActiveColourValue 0;
BA_ "GenSigTimeoutMsg_HU_B" SG_ 508 HuMoodLightActiveColourValue 0;
BA_ "GenSigTimeoutMsg_HU_A" SG_ 508 HuMoodLightActiveColourValue 0;
BA_ "GenSigSendType" SG_ 508 HuMoodLightActiveColourValue 1;
BA_ "GenSigTimeoutMsg_HU_High_X445" SG_ 508 HuMoodLightActiveColourValue 0;
BA_ "GenSigTimeoutMsg_HU_Mid_X445" SG_ 508 HuMoodLightActiveColourValue 0;
BA_ "GenSigTimeoutTime_HU_High_X445" SG_ 508 HuMoodLightActiveColourValue 0;
BA_ "GenSigTimeoutTime_HU_Mid_X445" SG_ 508 HuMoodLightActiveColourValue 0;
BA_ "GenSigTimeoutMsg_IVI" SG_ 508 HuMoodLightActiveColourValue 0;
BA_ "GenSigTimeoutTime_IVI" SG_ 508 HuMoodLightActiveColourValue 0;
BA_ "GenSigTimeoutTime_HU_Mid_X451" SG_ 508 HuMoodLightRearAreaActiveValue 0;
BA_ "GenSigTimeoutTime_HU_High_X451" SG_ 508 HuMoodLightRearAreaActiveValue 0;
BA_ "GenSigTimeoutTime_HU_B" SG_ 508 HuMoodLightRearAreaActiveValue 0;
BA_ "GenSigTimeoutTime_HU_A" SG_ 508 HuMoodLightRearAreaActiveValue 0;
BA_ "GenSigTimeoutMsg_HU_Mid_X451" SG_ 508 HuMoodLightRearAreaActiveValue 0;
BA_ "GenSigTimeoutMsg_HU_High_X451" SG_ 508 HuMoodLightRearAreaActiveValue 0;
BA_ "GenSigTimeoutMsg_HU_B" SG_ 508 HuMoodLightRearAreaActiveValue 0;
BA_ "GenSigTimeoutMsg_HU_A" SG_ 508 HuMoodLightRearAreaActiveValue 0;
BA_ "GenSigStartValue" SG_ 508 HuMoodLightRearAreaActiveValue 1;
BA_ "GenSigSendType" SG_ 508 HuMoodLightRearAreaActiveValue 1;
BA_ "GenSigInactiveValue" SG_ 508 HuMoodLightRearAreaActiveValue 1;
BA_ "GenSigTimeoutMsg_HU_High_X445" SG_ 508 HuMoodLightRearAreaActiveValue 0;
BA_ "GenSigTimeoutMsg_HU_Mid_X445" SG_ 508 HuMoodLightRearAreaActiveValue 0;
BA_ "GenSigTimeoutTime_HU_High_X445" SG_ 508 HuMoodLightRearAreaActiveValue 0;
BA_ "GenSigTimeoutTime_HU_Mid_X445" SG_ 508 HuMoodLightRearAreaActiveValue 0;
BA_ "GenSigTimeoutMsg_IVI" SG_ 508 HuMoodLightRearAreaActiveValue 0;
BA_ "GenSigTimeoutTime_IVI" SG_ 508 HuMoodLightRearAreaActiveValue 0;
BA_ "GenSigTimeoutTime_HU_Mid_X451" SG_ 508 HuMoodLightFrontRHAreaActiveValu 0;
BA_ "GenSigTimeoutTime_HU_High_X451" SG_ 508 HuMoodLightFrontRHAreaActiveValu 0;
BA_ "GenSigTimeoutTime_HU_B" SG_ 508 HuMoodLightFrontRHAreaActiveValu 0;
BA_ "GenSigTimeoutTime_HU_A" SG_ 508 HuMoodLightFrontRHAreaActiveValu 0;
BA_ "GenSigTimeoutMsg_HU_Mid_X451" SG_ 508 HuMoodLightFrontRHAreaActiveValu 0;
BA_ "GenSigTimeoutMsg_HU_High_X451" SG_ 508 HuMoodLightFrontRHAreaActiveValu 0;
BA_ "GenSigTimeoutMsg_HU_B" SG_ 508 HuMoodLightFrontRHAreaActiveValu 0;
BA_ "GenSigTimeoutMsg_HU_A" SG_ 508 HuMoodLightFrontRHAreaActiveValu 0;
BA_ "GenSigStartValue" SG_ 508 HuMoodLightFrontRHAreaActiveValu 1;
BA_ "GenSigSendType" SG_ 508 HuMoodLightFrontRHAreaActiveValu 1;
BA_ "GenSigInactiveValue" SG_ 508 HuMoodLightFrontRHAreaActiveValu 1;
BA_ "GenSigTimeoutMsg_HU_High_X445" SG_ 508 HuMoodLightFrontRHAreaActiveValu 0;
BA_ "GenSigTimeoutMsg_HU_Mid_X445" SG_ 508 HuMoodLightFrontRHAreaActiveValu 0;
BA_ "GenSigTimeoutTime_HU_High_X445" SG_ 508 HuMoodLightFrontRHAreaActiveValu 0;
BA_ "GenSigTimeoutTime_HU_Mid_X445" SG_ 508 HuMoodLightFrontRHAreaActiveValu 0;
BA_ "GenSigTimeoutMsg_IVI" SG_ 508 HuMoodLightFrontRHAreaActiveValu 0;
BA_ "GenSigTimeoutTime_IVI" SG_ 508 HuMoodLightFrontRHAreaActiveValu 0;
BA_ "SystemSignalLongSymbol" SG_ 508 HuMoodLightFrontRHAreaActiveValu "HuMoodLightFrontRHAreaActiveValue";
BA_ "GenSigTimeoutTime_HU_Mid_X451" SG_ 508 HuMoodLightFloorConsoleAreaActiv 0;
BA_ "GenSigTimeoutTime_HU_High_X451" SG_ 508 HuMoodLightFloorConsoleAreaActiv 0;
BA_ "GenSigTimeoutTime_HU_B" SG_ 508 HuMoodLightFloorConsoleAreaActiv 0;
BA_ "GenSigTimeoutTime_HU_A" SG_ 508 HuMoodLightFloorConsoleAreaActiv 0;
BA_ "GenSigTimeoutMsg_HU_Mid_X451" SG_ 508 HuMoodLightFloorConsoleAreaActiv 0;
BA_ "GenSigTimeoutMsg_HU_High_X451" SG_ 508 HuMoodLightFloorConsoleAreaActiv 0;
BA_ "GenSigTimeoutMsg_HU_B" SG_ 508 HuMoodLightFloorConsoleAreaActiv 0;
BA_ "GenSigTimeoutMsg_HU_A" SG_ 508 HuMoodLightFloorConsoleAreaActiv 0;
BA_ "GenSigStartValue" SG_ 508 HuMoodLightFloorConsoleAreaActiv 1;
BA_ "GenSigSendType" SG_ 508 HuMoodLightFloorConsoleAreaActiv 1;
BA_ "GenSigInactiveValue" SG_ 508 HuMoodLightFloorConsoleAreaActiv 1;
BA_ "GenSigTimeoutMsg_HU_High_X445" SG_ 508 HuMoodLightFloorConsoleAreaActiv 0;
BA_ "GenSigTimeoutMsg_HU_Mid_X445" SG_ 508 HuMoodLightFloorConsoleAreaActiv 0;
BA_ "GenSigTimeoutTime_HU_High_X445" SG_ 508 HuMoodLightFloorConsoleAreaActiv 0;
BA_ "GenSigTimeoutTime_HU_Mid_X445" SG_ 508 HuMoodLightFloorConsoleAreaActiv 0;
BA_ "GenSigTimeoutMsg_IVI" SG_ 508 HuMoodLightFloorConsoleAreaActiv 0;
BA_ "GenSigTimeoutTime_IVI" SG_ 508 HuMoodLightFloorConsoleAreaActiv 0;
BA_ "SystemSignalLongSymbol" SG_ 508 HuMoodLightFloorConsoleAreaActiv "HuMoodLightFloorConsoleAreaActiveValue";
BA_ "GenSigTimeoutTime_HU_Mid_X451" SG_ 508 HuMoodLightData 0;
BA_ "GenSigTimeoutTime_HU_High_X451" SG_ 508 HuMoodLightData 0;
BA_ "GenSigTimeoutTime_HU_B" SG_ 508 HuMoodLightData 0;
BA_ "GenSigTimeoutTime_HU_A" SG_ 508 HuMoodLightData 0;
BA_ "GenSigTimeoutMsg_HU_Mid_X451" SG_ 508 HuMoodLightData 0;
BA_ "GenSigTimeoutMsg_HU_High_X451" SG_ 508 HuMoodLightData 0;
BA_ "GenSigTimeoutMsg_HU_B" SG_ 508 HuMoodLightData 0;
BA_ "GenSigTimeoutMsg_HU_A" SG_ 508 HuMoodLightData 0;
BA_ "GenSigSendType" SG_ 508 HuMoodLightData 1;
BA_ "GenSigTimeoutMsg_HU_High_X445" SG_ 508 HuMoodLightData 0;
BA_ "GenSigTimeoutMsg_HU_Mid_X445" SG_ 508 HuMoodLightData 0;
BA_ "GenSigTimeoutTime_HU_High_X445" SG_ 508 HuMoodLightData 0;
BA_ "GenSigTimeoutTime_HU_Mid_X445" SG_ 508 HuMoodLightData 0;
BA_ "GenSigTimeoutMsg_IVI" SG_ 508 HuMoodLightData 0;
BA_ "GenSigTimeoutTime_IVI" SG_ 508 HuMoodLightData 0;
BA_ "GenSigTimeoutTime_HU_Mid_X451" SG_ 508 HuMoodLightIllumPossibleLevels 0;
BA_ "GenSigTimeoutTime_HU_High_X451" SG_ 508 HuMoodLightIllumPossibleLevels 0;
BA_ "GenSigTimeoutTime_HU_B" SG_ 508 HuMoodLightIllumPossibleLevels 0;
BA_ "GenSigTimeoutTime_HU_A" SG_ 508 HuMoodLightIllumPossibleLevels 0;
BA_ "GenSigTimeoutMsg_HU_Mid_X451" SG_ 508 HuMoodLightIllumPossibleLevels 0;
BA_ "GenSigTimeoutMsg_HU_High_X451" SG_ 508 HuMoodLightIllumPossibleLevels 0;
BA_ "GenSigTimeoutMsg_HU_B" SG_ 508 HuMoodLightIllumPossibleLevels 0;
BA_ "GenSigTimeoutMsg_HU_A" SG_ 508 HuMoodLightIllumPossibleLevels 0;
BA_ "GenSigStartValue" SG_ 508 HuMoodLightIllumPossibleLevels 5;
BA_ "GenSigSendType" SG_ 508 HuMoodLightIllumPossibleLevels 1;
BA_ "GenSigInactiveValue" SG_ 508 HuMoodLightIllumPossibleLevels 5;
BA_ "GenSigTimeoutMsg_HU_High_X445" SG_ 508 HuMoodLightIllumPossibleLevels 0;
BA_ "GenSigTimeoutMsg_HU_Mid_X445" SG_ 508 HuMoodLightIllumPossibleLevels 0;
BA_ "GenSigTimeoutTime_HU_High_X445" SG_ 508 HuMoodLightIllumPossibleLevels 0;
BA_ "GenSigTimeoutTime_HU_Mid_X445" SG_ 508 HuMoodLightIllumPossibleLevels 0;
BA_ "GenSigTimeoutMsg_IVI" SG_ 508 HuMoodLightIllumPossibleLevels 0;
BA_ "GenSigTimeoutTime_IVI" SG_ 508 HuMoodLightIllumPossibleLevels 0;
BA_ "GenSigTimeoutTime_HU_Mid_X451" SG_ 508 HuMoodLightHotMagentaColorSelOnH 0;
BA_ "GenSigTimeoutTime_HU_High_X451" SG_ 508 HuMoodLightHotMagentaColorSelOnH 0;
BA_ "GenSigTimeoutTime_HU_B" SG_ 508 HuMoodLightHotMagentaColorSelOnH 0;
BA_ "GenSigTimeoutTime_HU_A" SG_ 508 HuMoodLightHotMagentaColorSelOnH 0;
BA_ "GenSigTimeoutMsg_HU_Mid_X451" SG_ 508 HuMoodLightHotMagentaColorSelOnH 0;
BA_ "GenSigTimeoutMsg_HU_High_X451" SG_ 508 HuMoodLightHotMagentaColorSelOnH 0;
BA_ "GenSigTimeoutMsg_HU_B" SG_ 508 HuMoodLightHotMagentaColorSelOnH 0;
BA_ "GenSigTimeoutMsg_HU_A" SG_ 508 HuMoodLightHotMagentaColorSelOnH 0;
BA_ "GenSigSendType" SG_ 508 HuMoodLightHotMagentaColorSelOnH 1;
BA_ "GenSigTimeoutMsg_HU_High_X445" SG_ 508 HuMoodLightHotMagentaColorSelOnH 0;
BA_ "GenSigTimeoutMsg_HU_Mid_X445" SG_ 508 HuMoodLightHotMagentaColorSelOnH 0;
BA_ "GenSigTimeoutTime_HU_High_X445" SG_ 508 HuMoodLightHotMagentaColorSelOnH 0;
BA_ "GenSigTimeoutTime_HU_Mid_X445" SG_ 508 HuMoodLightHotMagentaColorSelOnH 0;
BA_ "GenSigTimeoutMsg_IVI" SG_ 508 HuMoodLightHotMagentaColorSelOnH 0;
BA_ "GenSigTimeoutTime_IVI" SG_ 508 HuMoodLightHotMagentaColorSelOnH 0;
BA_ "SystemSignalLongSymbol" SG_ 508 HuMoodLightHotMagentaColorSelOnH "HuMoodLightHotMagentaColorSelOnHU";
BA_ "GenSigTimeoutTime_HU_Mid_X451" SG_ 508 HuMoodLightGoldYellowColorSelOnH 0;
BA_ "GenSigTimeoutTime_HU_High_X451" SG_ 508 HuMoodLightGoldYellowColorSelOnH 0;
BA_ "GenSigTimeoutTime_HU_B" SG_ 508 HuMoodLightGoldYellowColorSelOnH 0;
BA_ "GenSigTimeoutTime_HU_A" SG_ 508 HuMoodLightGoldYellowColorSelOnH 0;
BA_ "GenSigTimeoutMsg_HU_Mid_X451" SG_ 508 HuMoodLightGoldYellowColorSelOnH 0;
BA_ "GenSigTimeoutMsg_HU_High_X451" SG_ 508 HuMoodLightGoldYellowColorSelOnH 0;
BA_ "GenSigTimeoutMsg_HU_B" SG_ 508 HuMoodLightGoldYellowColorSelOnH 0;
BA_ "GenSigTimeoutMsg_HU_A" SG_ 508 HuMoodLightGoldYellowColorSelOnH 0;
BA_ "GenSigSendType" SG_ 508 HuMoodLightGoldYellowColorSelOnH 1;
BA_ "GenSigTimeoutMsg_HU_High_X445" SG_ 508 HuMoodLightGoldYellowColorSelOnH 0;
BA_ "GenSigTimeoutMsg_HU_Mid_X445" SG_ 508 HuMoodLightGoldYellowColorSelOnH 0;
BA_ "GenSigTimeoutTime_HU_High_X445" SG_ 508 HuMoodLightGoldYellowColorSelOnH 0;
BA_ "GenSigTimeoutTime_HU_Mid_X445" SG_ 508 HuMoodLightGoldYellowColorSelOnH 0;
BA_ "GenSigTimeoutMsg_IVI" SG_ 508 HuMoodLightGoldYellowColorSelOnH 0;
BA_ "GenSigTimeoutTime_IVI" SG_ 508 HuMoodLightGoldYellowColorSelOnH 0;
BA_ "SystemSignalLongSymbol" SG_ 508 HuMoodLightGoldYellowColorSelOnH "HuMoodLightGoldYellowColorSelOnHU";
BA_ "GenSigTimeoutTime_HU_Mid_X451" SG_ 508 HuMoodLightFrenchLimeColorSelOnH 0;
BA_ "GenSigTimeoutTime_HU_High_X451" SG_ 508 HuMoodLightFrenchLimeColorSelOnH 0;
BA_ "GenSigTimeoutTime_HU_B" SG_ 508 HuMoodLightFrenchLimeColorSelOnH 0;
BA_ "GenSigTimeoutTime_HU_A" SG_ 508 HuMoodLightFrenchLimeColorSelOnH 0;
BA_ "GenSigTimeoutMsg_HU_Mid_X451" SG_ 508 HuMoodLightFrenchLimeColorSelOnH 0;
BA_ "GenSigTimeoutMsg_HU_High_X451" SG_ 508 HuMoodLightFrenchLimeColorSelOnH 0;
BA_ "GenSigTimeoutMsg_HU_B" SG_ 508 HuMoodLightFrenchLimeColorSelOnH 0;
BA_ "GenSigTimeoutMsg_HU_A" SG_ 508 HuMoodLightFrenchLimeColorSelOnH 0;
BA_ "GenSigSendType" SG_ 508 HuMoodLightFrenchLimeColorSelOnH 1;
BA_ "GenSigTimeoutMsg_HU_High_X445" SG_ 508 HuMoodLightFrenchLimeColorSelOnH 0;
BA_ "GenSigTimeoutMsg_HU_Mid_X445" SG_ 508 HuMoodLightFrenchLimeColorSelOnH 0;
BA_ "GenSigTimeoutTime_HU_High_X445" SG_ 508 HuMoodLightFrenchLimeColorSelOnH 0;
BA_ "GenSigTimeoutTime_HU_Mid_X445" SG_ 508 HuMoodLightFrenchLimeColorSelOnH 0;
BA_ "GenSigTimeoutMsg_IVI" SG_ 508 HuMoodLightFrenchLimeColorSelOnH 0;
BA_ "GenSigTimeoutTime_IVI" SG_ 508 HuMoodLightFrenchLimeColorSelOnH 0;
BA_ "SystemSignalLongSymbol" SG_ 508 HuMoodLightFrenchLimeColorSelOnH "HuMoodLightFrenchLimeColorSelOnHU";
BA_ "GenSigTimeoutTime_HU_Mid_X451" SG_ 508 HuMoodLightFrontLHAreaActiveValu 0;
BA_ "GenSigTimeoutTime_HU_High_X451" SG_ 508 HuMoodLightFrontLHAreaActiveValu 0;
BA_ "GenSigTimeoutTime_HU_B" SG_ 508 HuMoodLightFrontLHAreaActiveValu 0;
BA_ "GenSigTimeoutTime_HU_A" SG_ 508 HuMoodLightFrontLHAreaActiveValu 0;
BA_ "GenSigTimeoutMsg_HU_Mid_X451" SG_ 508 HuMoodLightFrontLHAreaActiveValu 0;
BA_ "GenSigTimeoutMsg_HU_High_X451" SG_ 508 HuMoodLightFrontLHAreaActiveValu 0;
BA_ "GenSigTimeoutMsg_HU_B" SG_ 508 HuMoodLightFrontLHAreaActiveValu 0;
BA_ "GenSigTimeoutMsg_HU_A" SG_ 508 HuMoodLightFrontLHAreaActiveValu 0;
BA_ "GenSigStartValue" SG_ 508 HuMoodLightFrontLHAreaActiveValu 1;
BA_ "GenSigSendType" SG_ 508 HuMoodLightFrontLHAreaActiveValu 1;
BA_ "GenSigInactiveValue" SG_ 508 HuMoodLightFrontLHAreaActiveValu 1;
BA_ "GenSigTimeoutMsg_HU_High_X445" SG_ 508 HuMoodLightFrontLHAreaActiveValu 0;
BA_ "GenSigTimeoutMsg_HU_Mid_X445" SG_ 508 HuMoodLightFrontLHAreaActiveValu 0;
BA_ "GenSigTimeoutTime_HU_High_X445" SG_ 508 HuMoodLightFrontLHAreaActiveValu 0;
BA_ "GenSigTimeoutTime_HU_Mid_X445" SG_ 508 HuMoodLightFrontLHAreaActiveValu 0;
BA_ "GenSigTimeoutMsg_IVI" SG_ 508 HuMoodLightFrontLHAreaActiveValu 0;
BA_ "GenSigTimeoutTime_IVI" SG_ 508 HuMoodLightFrontLHAreaActiveValu 0;
BA_ "SystemSignalLongSymbol" SG_ 508 HuMoodLightFrontLHAreaActiveValu "HuMoodLightFrontLHAreaActiveValue";
BA_ "GenSigTimeoutTime_HU_Mid_X451" SG_ 508 HuMoodLightPossibleModes 0;
BA_ "GenSigTimeoutTime_HU_High_X451" SG_ 508 HuMoodLightPossibleModes 0;
BA_ "GenSigTimeoutTime_HU_B" SG_ 508 HuMoodLightPossibleModes 0;
BA_ "GenSigTimeoutTime_HU_A" SG_ 508 HuMoodLightPossibleModes 0;
BA_ "GenSigTimeoutMsg_HU_Mid_X451" SG_ 508 HuMoodLightPossibleModes 0;
BA_ "GenSigTimeoutMsg_HU_High_X451" SG_ 508 HuMoodLightPossibleModes 0;
BA_ "GenSigTimeoutMsg_HU_B" SG_ 508 HuMoodLightPossibleModes 0;
BA_ "GenSigTimeoutMsg_HU_A" SG_ 508 HuMoodLightPossibleModes 0;
BA_ "GenSigStartValue" SG_ 508 HuMoodLightPossibleModes 2;
BA_ "GenSigSendType" SG_ 508 HuMoodLightPossibleModes 1;
BA_ "GenSigInactiveValue" SG_ 508 HuMoodLightPossibleModes 2;
BA_ "GenSigTimeoutMsg_HU_High_X445" SG_ 508 HuMoodLightPossibleModes 0;
BA_ "GenSigTimeoutMsg_HU_Mid_X445" SG_ 508 HuMoodLightPossibleModes 0;
BA_ "GenSigTimeoutTime_HU_High_X445" SG_ 508 HuMoodLightPossibleModes 0;
BA_ "GenSigTimeoutTime_HU_Mid_X445" SG_ 508 HuMoodLightPossibleModes 0;
BA_ "GenSigTimeoutMsg_IVI" SG_ 508 HuMoodLightPossibleModes 0;
BA_ "GenSigTimeoutTime_IVI" SG_ 508 HuMoodLightPossibleModes 0;
BA_ "GenSigTimeoutTime_HU_Mid_X451" SG_ 508 HuMoodLightActiveModeValue 0;
BA_ "GenSigTimeoutTime_HU_High_X451" SG_ 508 HuMoodLightActiveModeValue 0;
BA_ "GenSigTimeoutTime_HU_B" SG_ 508 HuMoodLightActiveModeValue 0;
BA_ "GenSigTimeoutTime_HU_A" SG_ 508 HuMoodLightActiveModeValue 0;
BA_ "GenSigTimeoutMsg_HU_Mid_X451" SG_ 508 HuMoodLightActiveModeValue 0;
BA_ "GenSigTimeoutMsg_HU_High_X451" SG_ 508 HuMoodLightActiveModeValue 0;
BA_ "GenSigTimeoutMsg_HU_B" SG_ 508 HuMoodLightActiveModeValue 0;
BA_ "GenSigTimeoutMsg_HU_A" SG_ 508 HuMoodLightActiveModeValue 0;
BA_ "GenSigSendType" SG_ 508 HuMoodLightActiveModeValue 1;
BA_ "GenSigTimeoutMsg_HU_High_X445" SG_ 508 HuMoodLightActiveModeValue 0;
BA_ "GenSigTimeoutMsg_HU_Mid_X445" SG_ 508 HuMoodLightActiveModeValue 0;
BA_ "GenSigTimeoutTime_HU_High_X445" SG_ 508 HuMoodLightActiveModeValue 0;
BA_ "GenSigTimeoutTime_HU_Mid_X445" SG_ 508 HuMoodLightActiveModeValue 0;
BA_ "GenSigTimeoutMsg_IVI" SG_ 508 HuMoodLightActiveModeValue 0;
BA_ "GenSigTimeoutTime_IVI" SG_ 508 HuMoodLightActiveModeValue 0;
BA_ "GenSigTimeoutTime_HU_Mid_X451" SG_ 508 HuMoodLightPolarBrightWhiteColor 0;
BA_ "GenSigTimeoutTime_HU_High_X451" SG_ 508 HuMoodLightPolarBrightWhiteColor 0;
BA_ "GenSigTimeoutTime_HU_B" SG_ 508 HuMoodLightPolarBrightWhiteColor 0;
BA_ "GenSigTimeoutTime_HU_A" SG_ 508 HuMoodLightPolarBrightWhiteColor 0;
BA_ "GenSigTimeoutMsg_HU_Mid_X451" SG_ 508 HuMoodLightPolarBrightWhiteColor 0;
BA_ "GenSigTimeoutMsg_HU_High_X451" SG_ 508 HuMoodLightPolarBrightWhiteColor 0;
BA_ "GenSigTimeoutMsg_HU_B" SG_ 508 HuMoodLightPolarBrightWhiteColor 0;
BA_ "GenSigTimeoutMsg_HU_A" SG_ 508 HuMoodLightPolarBrightWhiteColor 0;
BA_ "GenSigSendType" SG_ 508 HuMoodLightPolarBrightWhiteColor 1;
BA_ "GenSigTimeoutMsg_HU_High_X445" SG_ 508 HuMoodLightPolarBrightWhiteColor 0;
BA_ "GenSigTimeoutMsg_HU_Mid_X445" SG_ 508 HuMoodLightPolarBrightWhiteColor 0;
BA_ "GenSigTimeoutTime_HU_High_X445" SG_ 508 HuMoodLightPolarBrightWhiteColor 0;
BA_ "GenSigTimeoutTime_HU_Mid_X445" SG_ 508 HuMoodLightPolarBrightWhiteColor 0;
BA_ "GenSigTimeoutMsg_IVI" SG_ 508 HuMoodLightPolarBrightWhiteColor 0;
BA_ "GenSigTimeoutTime_IVI" SG_ 508 HuMoodLightPolarBrightWhiteColor 0;
BA_ "SystemSignalLongSymbol" SG_ 508 HuMoodLightPolarBrightWhiteColor "HuMoodLightPolarBrightWhiteColorSelOnHU";
BA_ "GenSigTimeoutTime_HU_Mid_X451" SG_ 508 HuMoodLightAeroBlueColorSelOnHU 0;
BA_ "GenSigTimeoutTime_HU_High_X451" SG_ 508 HuMoodLightAeroBlueColorSelOnHU 0;
BA_ "GenSigTimeoutTime_HU_B" SG_ 508 HuMoodLightAeroBlueColorSelOnHU 0;
BA_ "GenSigTimeoutTime_HU_A" SG_ 508 HuMoodLightAeroBlueColorSelOnHU 0;
BA_ "GenSigTimeoutMsg_HU_Mid_X451" SG_ 508 HuMoodLightAeroBlueColorSelOnHU 0;
BA_ "GenSigTimeoutMsg_HU_High_X451" SG_ 508 HuMoodLightAeroBlueColorSelOnHU 0;
BA_ "GenSigTimeoutMsg_HU_B" SG_ 508 HuMoodLightAeroBlueColorSelOnHU 0;
BA_ "GenSigTimeoutMsg_HU_A" SG_ 508 HuMoodLightAeroBlueColorSelOnHU 0;
BA_ "GenSigSendType" SG_ 508 HuMoodLightAeroBlueColorSelOnHU 1;
BA_ "GenSigTimeoutMsg_HU_High_X445" SG_ 508 HuMoodLightAeroBlueColorSelOnHU 0;
BA_ "GenSigTimeoutMsg_HU_Mid_X445" SG_ 508 HuMoodLightAeroBlueColorSelOnHU 0;
BA_ "GenSigTimeoutTime_HU_High_X445" SG_ 508 HuMoodLightAeroBlueColorSelOnHU 0;
BA_ "GenSigTimeoutTime_HU_Mid_X445" SG_ 508 HuMoodLightAeroBlueColorSelOnHU 0;
BA_ "GenSigTimeoutMsg_IVI" SG_ 508 HuMoodLightAeroBlueColorSelOnHU 0;
BA_ "GenSigTimeoutTime_IVI" SG_ 508 HuMoodLightAeroBlueColorSelOnHU 0;
BA_ "GenSigTimeoutTime_HU_Mid_X451" SG_ 508 HuMoodLightPurpleColorSelOnHU 0;
BA_ "GenSigTimeoutTime_HU_High_X451" SG_ 508 HuMoodLightPurpleColorSelOnHU 0;
BA_ "GenSigTimeoutTime_HU_B" SG_ 508 HuMoodLightPurpleColorSelOnHU 0;
BA_ "GenSigTimeoutTime_HU_A" SG_ 508 HuMoodLightPurpleColorSelOnHU 0;
BA_ "GenSigTimeoutMsg_HU_Mid_X451" SG_ 508 HuMoodLightPurpleColorSelOnHU 0;
BA_ "GenSigTimeoutMsg_HU_High_X451" SG_ 508 HuMoodLightPurpleColorSelOnHU 0;
BA_ "GenSigTimeoutMsg_HU_B" SG_ 508 HuMoodLightPurpleColorSelOnHU 0;
BA_ "GenSigTimeoutMsg_HU_A" SG_ 508 HuMoodLightPurpleColorSelOnHU 0;
BA_ "GenSigSendType" SG_ 508 HuMoodLightPurpleColorSelOnHU 1;
BA_ "GenSigTimeoutMsg_HU_High_X445" SG_ 508 HuMoodLightPurpleColorSelOnHU 0;
BA_ "GenSigTimeoutMsg_HU_Mid_X445" SG_ 508 HuMoodLightPurpleColorSelOnHU 0;
BA_ "GenSigTimeoutTime_HU_High_X445" SG_ 508 HuMoodLightPurpleColorSelOnHU 0;
BA_ "GenSigTimeoutTime_HU_Mid_X445" SG_ 508 HuMoodLightPurpleColorSelOnHU 0;
BA_ "GenSigTimeoutMsg_IVI" SG_ 508 HuMoodLightPurpleColorSelOnHU 0;
BA_ "GenSigTimeoutTime_IVI" SG_ 508 HuMoodLightPurpleColorSelOnHU 0;
BA_ "GenSigTimeoutTime_HU_Mid_X451" SG_ 508 HuMoodLightFluorescentGreenColor 0;
BA_ "GenSigTimeoutTime_HU_High_X451" SG_ 508 HuMoodLightFluorescentGreenColor 0;
BA_ "GenSigTimeoutTime_HU_B" SG_ 508 HuMoodLightFluorescentGreenColor 0;
BA_ "GenSigTimeoutTime_HU_A" SG_ 508 HuMoodLightFluorescentGreenColor 0;
BA_ "GenSigTimeoutMsg_HU_Mid_X451" SG_ 508 HuMoodLightFluorescentGreenColor 0;
BA_ "GenSigTimeoutMsg_HU_High_X451" SG_ 508 HuMoodLightFluorescentGreenColor 0;
BA_ "GenSigTimeoutMsg_HU_B" SG_ 508 HuMoodLightFluorescentGreenColor 0;
BA_ "GenSigTimeoutMsg_HU_A" SG_ 508 HuMoodLightFluorescentGreenColor 0;
BA_ "GenSigSendType" SG_ 508 HuMoodLightFluorescentGreenColor 1;
BA_ "GenSigTimeoutMsg_HU_High_X445" SG_ 508 HuMoodLightFluorescentGreenColor 0;
BA_ "GenSigTimeoutMsg_HU_Mid_X445" SG_ 508 HuMoodLightFluorescentGreenColor 0;
BA_ "GenSigTimeoutTime_HU_High_X445" SG_ 508 HuMoodLightFluorescentGreenColor 0;
BA_ "GenSigTimeoutTime_HU_Mid_X445" SG_ 508 HuMoodLightFluorescentGreenColor 0;
BA_ "GenSigTimeoutMsg_IVI" SG_ 508 HuMoodLightFluorescentGreenColor 0;
BA_ "GenSigTimeoutTime_IVI" SG_ 508 HuMoodLightFluorescentGreenColor 0;
BA_ "SystemSignalLongSymbol" SG_ 508 HuMoodLightFluorescentGreenColor "HuMoodLightFluorescentGreenColorSelOnHU";
BA_ "GenSigTimeoutTime_HU_Mid_X451" SG_ 508 HuMoodLightCyanBlueColorSelOnHU 0;
BA_ "GenSigTimeoutTime_HU_High_X451" SG_ 508 HuMoodLightCyanBlueColorSelOnHU 0;
BA_ "GenSigTimeoutTime_HU_B" SG_ 508 HuMoodLightCyanBlueColorSelOnHU 0;
BA_ "GenSigTimeoutTime_HU_A" SG_ 508 HuMoodLightCyanBlueColorSelOnHU 0;
BA_ "GenSigTimeoutMsg_HU_Mid_X451" SG_ 508 HuMoodLightCyanBlueColorSelOnHU 0;
BA_ "GenSigTimeoutMsg_HU_High_X451" SG_ 508 HuMoodLightCyanBlueColorSelOnHU 0;
BA_ "GenSigTimeoutMsg_HU_B" SG_ 508 HuMoodLightCyanBlueColorSelOnHU 0;
BA_ "GenSigTimeoutMsg_HU_A" SG_ 508 HuMoodLightCyanBlueColorSelOnHU 0;
BA_ "GenSigSendType" SG_ 508 HuMoodLightCyanBlueColorSelOnHU 1;
BA_ "GenSigTimeoutMsg_HU_High_X445" SG_ 508 HuMoodLightCyanBlueColorSelOnHU 0;
BA_ "GenSigTimeoutMsg_HU_Mid_X445" SG_ 508 HuMoodLightCyanBlueColorSelOnHU 0;
BA_ "GenSigTimeoutTime_HU_High_X445" SG_ 508 HuMoodLightCyanBlueColorSelOnHU 0;
BA_ "GenSigTimeoutTime_HU_Mid_X445" SG_ 508 HuMoodLightCyanBlueColorSelOnHU 0;
BA_ "GenSigTimeoutMsg_IVI" SG_ 508 HuMoodLightCyanBlueColorSelOnHU 0;
BA_ "GenSigTimeoutTime_IVI" SG_ 508 HuMoodLightCyanBlueColorSelOnHU 0;
BA_ "GenSigTimeoutTime_HU_Mid_X451" SG_ 508 HuMoodLightCoolBlueColorSelOnHU 0;
BA_ "GenSigTimeoutTime_HU_High_X451" SG_ 508 HuMoodLightCoolBlueColorSelOnHU 0;
BA_ "GenSigTimeoutTime_HU_B" SG_ 508 HuMoodLightCoolBlueColorSelOnHU 0;
BA_ "GenSigTimeoutTime_HU_A" SG_ 508 HuMoodLightCoolBlueColorSelOnHU 0;
BA_ "GenSigTimeoutMsg_HU_Mid_X451" SG_ 508 HuMoodLightCoolBlueColorSelOnHU 0;
BA_ "GenSigTimeoutMsg_HU_High_X451" SG_ 508 HuMoodLightCoolBlueColorSelOnHU 0;
BA_ "GenSigTimeoutMsg_HU_B" SG_ 508 HuMoodLightCoolBlueColorSelOnHU 0;
BA_ "GenSigTimeoutMsg_HU_A" SG_ 508 HuMoodLightCoolBlueColorSelOnHU 0;
BA_ "GenSigSendType" SG_ 508 HuMoodLightCoolBlueColorSelOnHU 1;
BA_ "GenSigTimeoutMsg_HU_High_X445" SG_ 508 HuMoodLightCoolBlueColorSelOnHU 0;
BA_ "GenSigTimeoutMsg_HU_Mid_X445" SG_ 508 HuMoodLightCoolBlueColorSelOnHU 0;
BA_ "GenSigTimeoutTime_HU_High_X445" SG_ 508 HuMoodLightCoolBlueColorSelOnHU 0;
BA_ "GenSigTimeoutTime_HU_Mid_X445" SG_ 508 HuMoodLightCoolBlueColorSelOnHU 0;
BA_ "GenSigTimeoutMsg_IVI" SG_ 508 HuMoodLightCoolBlueColorSelOnHU 0;
BA_ "GenSigTimeoutTime_IVI" SG_ 508 HuMoodLightCoolBlueColorSelOnHU 0;
BA_ "GenSigTimeoutTime_HU_Mid_X451" SG_ 508 HuMoodLightIvoryOFFWhiteColorSel 0;
BA_ "GenSigTimeoutTime_HU_High_X451" SG_ 508 HuMoodLightIvoryOFFWhiteColorSel 0;
BA_ "GenSigTimeoutTime_HU_B" SG_ 508 HuMoodLightIvoryOFFWhiteColorSel 0;
BA_ "GenSigTimeoutTime_HU_A" SG_ 508 HuMoodLightIvoryOFFWhiteColorSel 0;
BA_ "GenSigTimeoutMsg_HU_Mid_X451" SG_ 508 HuMoodLightIvoryOFFWhiteColorSel 0;
BA_ "GenSigTimeoutMsg_HU_High_X451" SG_ 508 HuMoodLightIvoryOFFWhiteColorSel 0;
BA_ "GenSigTimeoutMsg_HU_B" SG_ 508 HuMoodLightIvoryOFFWhiteColorSel 0;
BA_ "GenSigTimeoutMsg_HU_A" SG_ 508 HuMoodLightIvoryOFFWhiteColorSel 0;
BA_ "GenSigSendType" SG_ 508 HuMoodLightIvoryOFFWhiteColorSel 1;
BA_ "GenSigTimeoutMsg_HU_High_X445" SG_ 508 HuMoodLightIvoryOFFWhiteColorSel 0;
BA_ "GenSigTimeoutMsg_HU_Mid_X445" SG_ 508 HuMoodLightIvoryOFFWhiteColorSel 0;
BA_ "GenSigTimeoutTime_HU_High_X445" SG_ 508 HuMoodLightIvoryOFFWhiteColorSel 0;
BA_ "GenSigTimeoutTime_HU_Mid_X445" SG_ 508 HuMoodLightIvoryOFFWhiteColorSel 0;
BA_ "GenSigTimeoutMsg_IVI" SG_ 508 HuMoodLightIvoryOFFWhiteColorSel 0;
BA_ "GenSigTimeoutTime_IVI" SG_ 508 HuMoodLightIvoryOFFWhiteColorSel 0;
BA_ "SystemSignalLongSymbol" SG_ 508 HuMoodLightIvoryOFFWhiteColorSel "HuMoodLightIvoryOFFWhiteColorSelOnHU";
BA_ "GenSigTimeoutTime_HU_Mid_X451" SG_ 508 HuMoodLightIceBlueColorSelOnHU 0;
BA_ "GenSigTimeoutTime_HU_High_X451" SG_ 508 HuMoodLightIceBlueColorSelOnHU 0;
BA_ "GenSigTimeoutTime_HU_B" SG_ 508 HuMoodLightIceBlueColorSelOnHU 0;
BA_ "GenSigTimeoutTime_HU_A" SG_ 508 HuMoodLightIceBlueColorSelOnHU 0;
BA_ "GenSigTimeoutMsg_HU_Mid_X451" SG_ 508 HuMoodLightIceBlueColorSelOnHU 0;
BA_ "GenSigTimeoutMsg_HU_High_X451" SG_ 508 HuMoodLightIceBlueColorSelOnHU 0;
BA_ "GenSigTimeoutMsg_HU_B" SG_ 508 HuMoodLightIceBlueColorSelOnHU 0;
BA_ "GenSigTimeoutMsg_HU_A" SG_ 508 HuMoodLightIceBlueColorSelOnHU 0;
BA_ "GenSigSendType" SG_ 508 HuMoodLightIceBlueColorSelOnHU 1;
BA_ "GenSigTimeoutMsg_HU_High_X445" SG_ 508 HuMoodLightIceBlueColorSelOnHU 0;
BA_ "GenSigTimeoutMsg_HU_Mid_X445" SG_ 508 HuMoodLightIceBlueColorSelOnHU 0;
BA_ "GenSigTimeoutTime_HU_High_X445" SG_ 508 HuMoodLightIceBlueColorSelOnHU 0;
BA_ "GenSigTimeoutTime_HU_Mid_X445" SG_ 508 HuMoodLightIceBlueColorSelOnHU 0;
BA_ "GenSigTimeoutMsg_IVI" SG_ 508 HuMoodLightIceBlueColorSelOnHU 0;
BA_ "GenSigTimeoutTime_IVI" SG_ 508 HuMoodLightIceBlueColorSelOnHU 0;
BA_ "GenSigTimeoutTime_HU_Mid_X451" SG_ 508 HuMoodLightTuscanRedColorSelOnHU 0;
BA_ "GenSigTimeoutTime_HU_High_X451" SG_ 508 HuMoodLightTuscanRedColorSelOnHU 0;
BA_ "GenSigTimeoutTime_HU_B" SG_ 508 HuMoodLightTuscanRedColorSelOnHU 0;
BA_ "GenSigTimeoutTime_HU_A" SG_ 508 HuMoodLightTuscanRedColorSelOnHU 0;
BA_ "GenSigTimeoutMsg_HU_Mid_X451" SG_ 508 HuMoodLightTuscanRedColorSelOnHU 0;
BA_ "GenSigTimeoutMsg_HU_High_X451" SG_ 508 HuMoodLightTuscanRedColorSelOnHU 0;
BA_ "GenSigTimeoutMsg_HU_B" SG_ 508 HuMoodLightTuscanRedColorSelOnHU 0;
BA_ "GenSigTimeoutMsg_HU_A" SG_ 508 HuMoodLightTuscanRedColorSelOnHU 0;
BA_ "GenSigSendType" SG_ 508 HuMoodLightTuscanRedColorSelOnHU 1;
BA_ "GenSigTimeoutMsg_HU_High_X445" SG_ 508 HuMoodLightTuscanRedColorSelOnHU 0;
BA_ "GenSigTimeoutMsg_HU_Mid_X445" SG_ 508 HuMoodLightTuscanRedColorSelOnHU 0;
BA_ "GenSigTimeoutTime_HU_High_X445" SG_ 508 HuMoodLightTuscanRedColorSelOnHU 0;
BA_ "GenSigTimeoutTime_HU_Mid_X445" SG_ 508 HuMoodLightTuscanRedColorSelOnHU 0;
BA_ "GenSigTimeoutMsg_IVI" SG_ 508 HuMoodLightTuscanRedColorSelOnHU 0;
BA_ "GenSigTimeoutTime_IVI" SG_ 508 HuMoodLightTuscanRedColorSelOnHU 0;
BA_ "GenSigTimeoutTime_HU_Mid_X451" SG_ 508 HuMoodLightTealGreenColorSelOnHU 0;
BA_ "GenSigTimeoutTime_HU_High_X451" SG_ 508 HuMoodLightTealGreenColorSelOnHU 0;
BA_ "GenSigTimeoutTime_HU_B" SG_ 508 HuMoodLightTealGreenColorSelOnHU 0;
BA_ "GenSigTimeoutTime_HU_A" SG_ 508 HuMoodLightTealGreenColorSelOnHU 0;
BA_ "GenSigTimeoutMsg_HU_Mid_X451" SG_ 508 HuMoodLightTealGreenColorSelOnHU 0;
BA_ "GenSigTimeoutMsg_HU_High_X451" SG_ 508 HuMoodLightTealGreenColorSelOnHU 0;
BA_ "GenSigTimeoutMsg_HU_B" SG_ 508 HuMoodLightTealGreenColorSelOnHU 0;
BA_ "GenSigTimeoutMsg_HU_A" SG_ 508 HuMoodLightTealGreenColorSelOnHU 0;
BA_ "GenSigSendType" SG_ 508 HuMoodLightTealGreenColorSelOnHU 1;
BA_ "GenSigTimeoutMsg_HU_High_X445" SG_ 508 HuMoodLightTealGreenColorSelOnHU 0;
BA_ "GenSigTimeoutMsg_HU_Mid_X445" SG_ 508 HuMoodLightTealGreenColorSelOnHU 0;
BA_ "GenSigTimeoutTime_HU_High_X445" SG_ 508 HuMoodLightTealGreenColorSelOnHU 0;
BA_ "GenSigTimeoutTime_HU_Mid_X445" SG_ 508 HuMoodLightTealGreenColorSelOnHU 0;
BA_ "GenSigTimeoutMsg_IVI" SG_ 508 HuMoodLightTealGreenColorSelOnHU 0;
BA_ "GenSigTimeoutTime_IVI" SG_ 508 HuMoodLightTealGreenColorSelOnHU 0;
BA_ "GenSigTimeoutTime_HU_Mid_X451" SG_ 508 HuMoodLightRubyRedColorSelOnHU 0;
BA_ "GenSigTimeoutTime_HU_High_X451" SG_ 508 HuMoodLightRubyRedColorSelOnHU 0;
BA_ "GenSigTimeoutTime_HU_B" SG_ 508 HuMoodLightRubyRedColorSelOnHU 0;
BA_ "GenSigTimeoutTime_HU_A" SG_ 508 HuMoodLightRubyRedColorSelOnHU 0;
BA_ "GenSigTimeoutMsg_HU_Mid_X451" SG_ 508 HuMoodLightRubyRedColorSelOnHU 0;
BA_ "GenSigTimeoutMsg_HU_High_X451" SG_ 508 HuMoodLightRubyRedColorSelOnHU 0;
BA_ "GenSigTimeoutMsg_HU_B" SG_ 508 HuMoodLightRubyRedColorSelOnHU 0;
BA_ "GenSigTimeoutMsg_HU_A" SG_ 508 HuMoodLightRubyRedColorSelOnHU 0;
BA_ "GenSigSendType" SG_ 508 HuMoodLightRubyRedColorSelOnHU 1;
BA_ "GenSigTimeoutMsg_HU_High_X445" SG_ 508 HuMoodLightRubyRedColorSelOnHU 0;
BA_ "GenSigTimeoutMsg_HU_Mid_X445" SG_ 508 HuMoodLightRubyRedColorSelOnHU 0;
BA_ "GenSigTimeoutTime_HU_High_X445" SG_ 508 HuMoodLightRubyRedColorSelOnHU 0;
BA_ "GenSigTimeoutTime_HU_Mid_X445" SG_ 508 HuMoodLightRubyRedColorSelOnHU 0;
BA_ "GenSigTimeoutMsg_IVI" SG_ 508 HuMoodLightRubyRedColorSelOnHU 0;
BA_ "GenSigTimeoutTime_IVI" SG_ 508 HuMoodLightRubyRedColorSelOnHU 0;
BA_ "GenSigTimeoutTime_HU_Mid_X451" SG_ 508 HuMoodLightOrangeColorSelOnHU 0;
BA_ "GenSigTimeoutTime_HU_High_X451" SG_ 508 HuMoodLightOrangeColorSelOnHU 0;
BA_ "GenSigTimeoutTime_HU_B" SG_ 508 HuMoodLightOrangeColorSelOnHU 0;
BA_ "GenSigTimeoutTime_HU_A" SG_ 508 HuMoodLightOrangeColorSelOnHU 0;
BA_ "GenSigTimeoutMsg_HU_Mid_X451" SG_ 508 HuMoodLightOrangeColorSelOnHU 0;
BA_ "GenSigTimeoutMsg_HU_High_X451" SG_ 508 HuMoodLightOrangeColorSelOnHU 0;
BA_ "GenSigTimeoutMsg_HU_B" SG_ 508 HuMoodLightOrangeColorSelOnHU 0;
BA_ "GenSigTimeoutMsg_HU_A" SG_ 508 HuMoodLightOrangeColorSelOnHU 0;
BA_ "GenSigSendType" SG_ 508 HuMoodLightOrangeColorSelOnHU 1;
BA_ "GenSigTimeoutMsg_HU_High_X445" SG_ 508 HuMoodLightOrangeColorSelOnHU 0;
BA_ "GenSigTimeoutMsg_HU_Mid_X445" SG_ 508 HuMoodLightOrangeColorSelOnHU 0;
BA_ "GenSigTimeoutTime_HU_High_X445" SG_ 508 HuMoodLightOrangeColorSelOnHU 0;
BA_ "GenSigTimeoutTime_HU_Mid_X445" SG_ 508 HuMoodLightOrangeColorSelOnHU 0;
BA_ "GenSigTimeoutMsg_IVI" SG_ 508 HuMoodLightOrangeColorSelOnHU 0;
BA_ "GenSigTimeoutTime_IVI" SG_ 508 HuMoodLightOrangeColorSelOnHU 0;
BA_ "GenSigTimeoutTime_HU_Mid_X451" SG_ 508 HuMoodLightPurpleTaupeSelOnHU 0;
BA_ "GenSigTimeoutTime_HU_High_X451" SG_ 508 HuMoodLightPurpleTaupeSelOnHU 0;
BA_ "GenSigTimeoutTime_HU_B" SG_ 508 HuMoodLightPurpleTaupeSelOnHU 0;
BA_ "GenSigTimeoutTime_HU_A" SG_ 508 HuMoodLightPurpleTaupeSelOnHU 0;
BA_ "GenSigTimeoutMsg_HU_Mid_X451" SG_ 508 HuMoodLightPurpleTaupeSelOnHU 0;
BA_ "GenSigTimeoutMsg_HU_High_X451" SG_ 508 HuMoodLightPurpleTaupeSelOnHU 0;
BA_ "GenSigTimeoutMsg_HU_B" SG_ 508 HuMoodLightPurpleTaupeSelOnHU 0;
BA_ "GenSigTimeoutMsg_HU_A" SG_ 508 HuMoodLightPurpleTaupeSelOnHU 0;
BA_ "GenSigSendType" SG_ 508 HuMoodLightPurpleTaupeSelOnHU 1;
BA_ "GenSigTimeoutMsg_HU_High_X445" SG_ 508 HuMoodLightPurpleTaupeSelOnHU 0;
BA_ "GenSigTimeoutMsg_HU_Mid_X445" SG_ 508 HuMoodLightPurpleTaupeSelOnHU 0;
BA_ "GenSigTimeoutTime_HU_High_X445" SG_ 508 HuMoodLightPurpleTaupeSelOnHU 0;
BA_ "GenSigTimeoutTime_HU_Mid_X445" SG_ 508 HuMoodLightPurpleTaupeSelOnHU 0;
BA_ "GenSigTimeoutMsg_IVI" SG_ 508 HuMoodLightPurpleTaupeSelOnHU 0;
BA_ "GenSigTimeoutTime_IVI" SG_ 508 HuMoodLightPurpleTaupeSelOnHU 0;
VAL_ 499 CCmHuRearBlowerSwitchAck2 3 "Reserved" 2 "Not updated due to switch position 0" 1 "Updated" 0 "Not updated" ;
VAL_ 499 CCmHuCtrlPnlSwitchAck 1 "Updated" 0 "Not Updated" ;
VAL_ 499 CCmHuExpressCoolSwitchAck 1 "Updated" 0 "Not updated" ;
VAL_ 499 CCmHuRearBlowerSwitchAck 1 "Updated" 0 "Not updated" ;
VAL_ 499 CCmHuFanSpdAck 1 "Updated" 0 "Not Updated" ;
VAL_ 499 CCmHuDistribSwitchAck 1 "Updated" 0 "Not Updated" ;
VAL_ 499 CCmHuMaxDefrstSwitchAck 1 "Updated" 0 "Not Updated" ;
VAL_ 499 CCmHuEconModeSwitchAck 1 "Updated" 0 "Not Updated" ;
VAL_ 499 CCmHuAutoSwitchAck 1 "Updated" 0 "Not Updated" ;
VAL_ 499 CCmHuRearDefogSwitchAck 1 "Updated" 0 "Not Updated" ;
VAL_ 499 CCmHuAirConCompSwitchAck 1 "Updated" 0 "Not Updated" ;
VAL_ 499 CCmHuErrAck 1 "Updated" 0 "Not updated" ;
VAL_ 499 CCmHuTempWhlAck 1 "Updated" 0 "Not Updated" ;
VAL_ 499 CCmHuFreshAirRecircSwitchAck 1 "Updated" 0 "Not Updated" ;
VAL_ 499 CCmHuDualModeSwitchAck 1 "Updated" 0 "Not Updated" ;
VAL_ 499 CCmHuTempWhlPassAck 1 "Updated" 0 "Not Updated" ;
VAL_ 499 CCmHuTempWhlDrvrAck 1 "Updated" 0 "Not Updated" ;
VAL_ 500 CCmHuSwitchStatusStuckWarn 31 "Reserved
" 30 "Reserved
" 29 "Reserved" 28 "Reserved" 27 "Reserved
" 26 "Reserved" 25 "Reserved" 24 "Reserved" 23 "Reserved" 22 "Reserved
" 21 "Reserved" 20 "Reserved" 19 "Reserved" 18 "Reserved" 17 "Reserved" 16 "Reserved
" 15 "Reserved" 14 "Reserved" 13 "Reserved" 12 "Reserved" 11 "Reserved" 10 "Reserved" 9 "Rear defog stuck" 8 "Distribution button stuck" 7 "Recirculation button stuck" 6 "Maxdefrost button stuck" 5 "Dual button stuck" 4 "Off button stuck" 3 "Auto button stuck
" 2 "Econ button stuck" 1 "AC Button stuck" 0 "CCmHuSwitchStatusStuckWarnClear" ;
VAL_ 500 CCmHuQueryFlag 1 "Query" 0 "No Query" ;
VAL_ 500 CCmHuFanControlDuringVR 3 "Reserved" 2 "Available" 1 "Not Available" 0 "Reserved" ;
VAL_ 504 BCmAutoRelockActiveSignalVal 1 "Active value for Auto Relock feature is Enabled " 0 "Active value for Auto Relock feature is Disabled " ;
VAL_ 504 BCmFMhActiveSignalVal 3 "Reserved" 2 "Active value is BCmFMhSignalVal3" 1 "Active value is BCmFMhSignalVal2" 0 "Active value is BCmFMhSignalVal1" ;
VAL_ 504 BCmFMhSignalVal1 31 "Reserved" 30 "Reserved" 29 "Reserved" 28 "Reserved" 27 "Reserved" 26 "Reserved" 25 "Reserved" 24 "Possible value selected is 240" 23 "Possible value selected is 230" 22 "Possible value selected is 220" 21 "Possible value selected is 210" 20 "Possible value selected is 200" 19 "Possible value selected is 190" 18 "Possible value selected is 180" 17 "Possible value selected is 170" 16 "Possible value selected is 160" 15 "Possible value selected is 150" 14 "Possible value selected is 140" 13 "Possible value selected is 130" 12 "Possible value selected is 120" 11 "Possible value selected is 110" 10 "Possible value selected is 100" 9 "Possible value selected is 90" 8 "Possible value selected is 80" 7 "Possible value selected is 70" 6 "Possible value selected is 60" 5 "Possible value selected is 50" 4 "Possible value selected is 40" 3 "Possible value selected is 30" 2 "Possible value selected is 20" 1 "Possible value selected is 10" 0 "Possible value selected is 0" ;
VAL_ 504 BCmVehLockHornReqActiveSignalVal 1 "Active value for vehicle Lock Horn Request feature is ON" 0 "Active value for vehicle Lock Horn Request feature is OFF" ;
VAL_ 504 BCmApproachLampActiveSignalVal 3 "Reserved" 2 "Active value is BCmApproachLampSignalVal3" 1 "Active value is BCmApproachLampSignalVal2" 0 "Active value is BCmApproachLampSignalVal1" ;
VAL_ 504 BCmFMhSignalVal2 31 "Reserved" 30 "Reserved" 29 "Reserved" 28 "Reserved" 27 "Reserved" 26 "Reserved" 25 "Reserved" 24 "Possible value selected is 240" 23 "Possible value selected is 230" 22 "Possible value selected is 220" 21 "Possible value selected is 210" 20 "Possible value selected is 200" 19 "Possible value selected is 190" 18 "Possible value selected is 180" 17 "Possible value selected is 170" 16 "Possible value selected is 160" 15 "Possible value selected is 150" 14 "Possible value selected is 140" 13 "Possible value selected is 130" 12 "Possible value selected is 120" 11 "Possible value selected is 110" 10 "Possible value selected is 100" 9 "Possible value selected is 90" 8 "Possible value selected is 80" 7 "Possible value selected is 70" 6 "Possible value selected is 60" 5 "Possible value selected is 50" 4 "Possible value selected is 40" 3 "Possible value selected is 30" 2 "Possible value selected is 20" 1 "Possible value selected is 10" 0 "Possible value selected is 0" ;
VAL_ 504 BCmDriveAwayLockingActiveSignalV 1 "Active value for Drive Away Locking feature is Enabled" 0 "Active value for Drive Away Locking feature is Disabled" ;
VAL_ 504 BCmRKeUnlockState 1 "Vehicle unlock feature with RKE is enabled in BCM" 0 "Vehicle unlock feature with RKE is disabled in BCM" ;
VAL_ 504 BCmPKeUnlockState 1 "Vehicle unlock feature with PKE is enabled in BCM" 0 "Vehicle unlock feature with PKE is disabled in BCM" ;
VAL_ 504 BCmFMhSignalVal3 31 "Reserved" 30 "Reserved" 29 "Reserved" 28 "Reserved" 27 "Reserved" 26 "Reserved" 25 "Reserved" 24 "Possible value selected is 240" 23 "Possible value selected is 230" 22 "Possible value selected is 220" 21 "Possible value selected is 210" 20 "Possible value selected is 200" 19 "Possible value selected is 190" 18 "Possible value selected is 180" 17 "Possible value selected is 170" 16 "Possible value selected is 160" 15 "Possible value selected is 150" 14 "Possible value selected is 140" 13 "Possible value selected is 130" 12 "Possible value selected is 120" 11 "Possible value selected is 110" 10 "Possible value selected is 100" 9 "Possible value selected is 90" 8 "Possible value selected is 80" 7 "Possible value selected is 70" 6 "Possible value selected is 60" 5 "Possible value selected is 50" 4 "Possible value selected is 40" 3 "Possible value selected is 30" 2 "Possible value selected is 20" 1 "Possible value selected is 10" 0 "Possible value selected is 0" ;
VAL_ 504 BCmAutoRelockState 1 "Auto Relock feature is enabled in BCM" 0 "Auto Relock feature is disabled in BCM" ;
VAL_ 504 BCmFMhState 1 "FMH feature is enabled in BCM" 0 "FMH feature is disabled in BCM" ;
VAL_ 504 BCmUCsState 1 "UCS State Enabled" 0 "UCS State Disabled" ;
VAL_ 504 BCmApproachLampSignalVal1 31 "Reserved" 30 "Reserved" 29 "Reserved" 28 "Reserved" 27 "Reserved" 26 "Reserved" 25 "Reserved" 24 "Possible value selected is 240" 23 "Possible value selected is 230" 22 "Possible value selected is 220" 21 "Possible value selected is 210" 20 "Possible value selected is 200" 19 "Possible value selected is 190" 18 "Possible value selected is 180" 17 "Possible value selected is 170" 16 "Possible value selected is 160" 15 "Possible value selected is 150" 14 "Possible value selected is 140" 13 "Possible value selected is 130" 12 "Possible value selected is 120" 11 "Possible value selected is 110" 10 "Possible value selected is 100" 9 "Possible value selected is 90" 8 "Possible value selected is 80" 7 "Possible value selected is 70" 6 "Possible value selected is 60" 5 "Possible value selected is 50" 4 "Possible value selected is 40" 3 "Possible value selected is 30" 2 "Possible value selected is 20" 1 "Possible value selected is 10" 0 "Possible value selected is 0" ;
VAL_ 504 BCmPKeUnlockActiveSignalVal 1 "Active value for vehicle Unlock with PKE feature is Double Stage Unlock " 0 "Active value for vehicle Unlock with PKE feature is Single Stage Unlock" ;
VAL_ 504 BCmRKeUnlockActiveSignalVal 1 "Active value for vehicle Unlock with RKE feature is Double Stage Unlock" 0 "Active value for vehicle Unlock with RKE feature is Single Stage Unlock" ;
VAL_ 504 BCmDriveAwayLockingState 1 "Drive Away Locking feature is enabled in BCM" 0 "Drive Away Locking feature is disabled in BCM" ;
VAL_ 504 BCmApproachLampSignalVal2 31 "Reserved" 30 "Reserved" 29 "Reserved" 28 "Reserved" 27 "Reserved" 26 "Reserved" 25 "Reserved" 24 "Possible value selected is 240" 23 "Possible value selected is 230" 22 "Possible value selected is 220" 21 "Possible value selected is 210" 20 "Possible value selected is 200" 19 "Possible value selected is 190" 18 "Possible value selected is 180" 17 "Possible value selected is 170" 16 "Possible value selected is 160" 15 "Possible value selected is 150" 14 "Possible value selected is 140" 13 "Possible value selected is 130" 12 "Possible value selected is 120" 11 "Possible value selected is 110" 10 "Possible value selected is 100" 9 "Possible value selected is 90" 8 "Possible value selected is 80" 7 "Possible value selected is 70" 6 "Possible value selected is 60" 5 "Possible value selected is 50" 4 "Possible value selected is 40" 3 "Possible value selected is 30" 2 "Possible value selected is 20" 1 "Possible value selected is 10" 0 "Possible value selected is 0" ;
VAL_ 504 AmbLightModeIllumOnHu 1 "Mode and Illumination Display is Enabled" 0 "Mode and Illumination Display is Disabled" ;
VAL_ 504 BCmApproachLampState 1 "Approach Lamp feature is enabled in BCM" 0 "Approach Lamp feature is disabled in BCM" ;
VAL_ 504 BCmVehLockHornReqState 1 "Horn request feature on vehicle lock is enabled in BCM" 0 "Horn request feature on vehicle lock is disabled in BCM" ;
VAL_ 504 BCmApproachLampSignalVal3 31 "Reserved" 30 "Reserved" 29 "Reserved" 28 "Reserved" 27 "Reserved" 26 "Reserved" 25 "Reserved" 24 "Possible value selected is 240" 23 "Possible value selected is 230" 22 "Possible value selected is 220" 21 "Possible value selected is 210" 20 "Possible value selected is 200" 19 "Possible value selected is 190" 18 "Possible value selected is 180" 17 "Possible value selected is 170" 16 "Possible value selected is 160" 15 "Possible value selected is 150" 14 "Possible value selected is 140" 13 "Possible value selected is 130" 12 "Possible value selected is 120" 11 "Possible value selected is 110" 10 "Possible value selected is 100" 9 "Possible value selected is 90" 8 "Possible value selected is 80" 7 "Possible value selected is 70" 6 "Possible value selected is 60" 5 "Possible value selected is 50" 4 "Possible value selected is 40" 3 "Possible value selected is 30" 2 "Possible value selected is 20" 1 "Possible value selected is 10" 0 "Possible value selected is 0" ;
VAL_ 504 BCmDRLActiveSignalVal 1 "Active value for DRL feature is Enabled" 0 "Active value for DRL feature is Disabled " ;
VAL_ 504 BCmDRLState 1 "DRL feature is enabled in BCM" 0 "DRL feature is disabled in BCM" ;
VAL_ 504 BCmMoodLightState 1 "Mood lighting selection on HU is Enabled" 0 "Mood lighting selection on HU is Disabled" ;
VAL_ 504 BCmUcsData 3 "Reserved" 2 "BCM sends UCS data to HU" 1 "BCM Acknowledges the UCS data" 0 "Reserved" ;
VAL_ 505 BCmMoodLightAllAreaActiveValue 1 "ON" 0 "OFF" ;
VAL_ 505 BCmMoodLightIllumSelActiveVal 7 "Reserved" 6 "Reserved" 5 "Level 5 Intensity" 4 "Level 4 Intensity" 3 "Level 3 Intensity" 2 "Level 2 Intensity" 1 "Level 1 Intensity" 0 "Reserved" ;
VAL_ 505 BCmMoodLightActiveColour 15 "Cyan Blue" 14 "Teal Green" 13 "French Lime" 12 "Gold Yellow" 11 "Tuscan Red" 10 "Aero Blue" 9 "Hot Magenta" 8 "Purple Taupe" 7 "Ruby (Red)" 6 "Fluorescent Green" 5 "Orange" 4 "Purple" 3 "Ivory (Off White)" 2 "Polar(Bright White)" 1 "Cool Blue" 0 "Ice Blue" ;
VAL_ 505 BCmMoodLightRearAreaActiveValue 1 "ON" 0 "OFF" ;
VAL_ 505 BCmMoodLightFrontRHAreaActiveVal 1 "ON" 0 "OFF" ;
VAL_ 505 BCmMoodLightFloorConsoleAreaActi 1 "ON" 0 "OFF" ;
VAL_ 505 BCmMoodLightData 3 "Reserved" 2 "BCM sends Mood light data to HU" 1 "BCM Acknowledges the Mood light data sent by HU" 0 "Reserved" ;
VAL_ 505 BCmMoodLightIllumPossibleLevels 7 "Reserved" 6 "Reserved" 5 "Intensity5" 4 "Intensity4" 3 "Intensity3" 2 "Intensity2" 1 "Intensity1" 0 "Reserved" ;
VAL_ 505 BCmMoodLightHotMagentaColorSelOn 1 "Present" 0 "Not Present" ;
VAL_ 505 BCmMoodLightGoldYellowColorSelOn 1 "Present" 0 "Not Present" ;
VAL_ 505 BCmMoodLightFrenchLimeColorSelOn 1 "Present" 0 "Not Present" ;
VAL_ 505 BCmMoodLightFrontLHAreaActiveVal 1 "ON" 0 "OFF" ;
VAL_ 505 BCmMoodLightPossibleModes 3 "AUTO, OFF, ON" 2 "OFF, ON" 1 "No Mode selection" 0 "Reserved" ;
VAL_ 505 BCmMoodLightActiveModeValue 3 "Reserved" 2 "ON" 1 "OFF" 0 "AUTO" ;
VAL_ 505 BCmMoodLightPolarBrightWhiteColo 1 "Present" 0 "Not Present" ;
VAL_ 505 BCmMoodLightAeroBlueColorSelOnHU 1 "Present" 0 "Not Present" ;
VAL_ 505 BCmMoodLightPurpleColorSelOnHU 1 "Present" 0 "Not Present" ;
VAL_ 505 BCmMoodLightFluorescentGreenColo 1 "Present" 0 "Not Present" ;
VAL_ 505 BCmMoodLightCyanBlueColorSelOnHU 1 "Present" 0 "Not Present" ;
VAL_ 505 BCmMoodLightCoolBlueColorSelOnHU 1 "Present" 0 "Not Present" ;
VAL_ 505 BCmMoodLightIvoryOFFWhiteColorSe 1 "Present" 0 "Not Present" ;
VAL_ 505 BCmMoodLightIceBlueColorSelOnHU 1 "Present" 0 "Not Present" ;
VAL_ 505 BCmMoodLightTuscanRedColorSelOnH 1 "Present" 0 "Not Present" ;
VAL_ 505 BCmMoodLightTealGreenColorSelOnH 1 "Present" 0 "Not Present" ;
VAL_ 505 BCmMoodLightRubyRedColorSelOnHU 1 "Present" 0 "Not Present" ;
VAL_ 505 BCmMoodLightOrangeColorSelOnHU 1 "Present" 0 "Not Present" ;
VAL_ 505 BCmMoodLightPurpleTaupeColorSelO 1 "Present" 0 "Not Present" ;
VAL_ 505 BCmMoodLightLocationSel 1 "Mood lighting location selection on HU is Enabled" 0 "Mood lighting location selection on HU is Disabled" ;
VAL_ 505 BCmMoodLightAllAreaSelOnHU 1 "Present" 0 "Not Present" ;
VAL_ 505 BCmMoodLightFrontLHAreaSelOnHU 1 "Present" 0 "Not Present" ;
VAL_ 505 BCmMoodLightRearAreaSelOnHU 1 "Present" 0 "Not Present" ;
VAL_ 505 BCmMoodLightFloorConsoleAreaSelO 1 "Present" 0 "Not Present" ;
VAL_ 505 BCmMoodLightState 1 "Mood lighting selection on HU is Enabled" 0 "Mood lighting selection on HU is Disabled" ;
VAL_ 505 BCmMoodLightFrontRHAreaSelOnHU 1 "Present" 0 "Not Present" ;
VAL_ 506 HuAutoRelockActiveSignalVal 1 "Active value for Auto Relock feature is Enabled" 0 "Active value for Auto Relock feature is Disabled" ;
VAL_ 506 HuFMhActiveSignalVal 3 "Reserved" 2 "Active value is HuFMhPossibleVal3" 1 "Active value is HuFMhPossibleVal2" 0 "Active value is HuFMhPossibleVal1" ;
VAL_ 506 HuFMhSignalVal1 31 "Reserved" 30 "Reserved" 29 "Reserved" 28 "Reserved" 27 "Reserved" 26 "Reserved" 25 "Reserved" 24 "Possible value selected is 240" 23 "Possible value selected is 230" 22 "Possible value selected is 220" 21 "Possible value selected is 210" 20 "Possible value selected is 200" 19 "Possible value selected is 190" 18 "Possible value selected is 180" 17 "Possible value selected is 170" 16 "Possible value selected is 160" 15 "Possible value selected is 150" 14 "Possible value selected is 140" 13 "Possible value selected is 130" 12 "Possible value selected is 120" 11 "Possible value selected is 110" 10 "Possible value selected is 100" 9 "Possible value selected is 90" 8 "Possible value selected is 80" 7 "Possible value selected is 70" 6 "Possible value selected is 60" 5 "Possible value selected is 50" 4 "Possible value selected is 40" 3 "Possible value selected is 30" 2 "Possible value selected is 20" 1 "Possible value selected is 10" 0 "Possible value selected is 0" ;
VAL_ 506 HuVehLockHornReqActiveSignalVal 1 "Active value for vehicle Lock Horn Request feature is ON" 0 "Active value for Vehicle Lock Horn Request feature is OFF
" ;
VAL_ 506 HuApproachLampActiveSignalVal 3 "Reserved" 2 "Active value is HuApproachLampSignalVal3" 1 "Active value is HuApproachLampSignalVal2" 0 "Active value is HuApproachLampSignalVal1" ;
VAL_ 506 HuFMhSignalVal2 31 "Reserved" 30 "Reserved" 29 "Reserved" 28 "Reserved" 27 "Reserved" 26 "Reserved" 25 "Reserved" 24 "Possible value selected is 240" 23 "Possible value selected is 230" 22 "Possible value selected is 220" 21 "Possible value selected is 210" 20 "Possible value selected is 200" 19 "Possible value selected is 190" 18 "Possible value selected is 180" 17 "Possible value selected is 170" 16 "Possible value selected is 160" 15 "Possible value selected is 150" 14 "Possible value selected is 140" 13 "Possible value selected is 130" 12 "Possible value selected is 120" 11 "Possible value selected is 110" 10 "Possible value selected is 100" 9 "Possible value selected is 90" 8 "Possible value selected is 80" 7 "Possible value selected is 70" 6 "Possible value selected is 60" 5 "Possible value selected is 50" 4 "Possible value selected is 40" 3 "Possible value selected is 30" 2 "Possible value selected is 20" 1 "Possible value selected is 10" 0 "Possible value selected is 0" ;
VAL_ 506 HuDriveAwayLockingActiveSignalVa 1 "Active value for Drive Away Locking feature is Enabled" 0 "Active value for Drive Away Locking feature is Disabled
" ;
VAL_ 506 HuRKeUnlockActiveSignalVal 1 "Active value for vehicle Unlock with RKE feature is Double Stage Unlock" 0 "Active value for vehicle Unlock with RKE feature is Single Stage Unlock
" ;
VAL_ 506 HuPKeUnlockActiveSignalVal 1 "Active value for vehicle Unlock with PKE feature is Double Stage Unlock" 0 "Active value for vehicle Unlock with PKE feature is Single Stage Unlock
" ;
VAL_ 506 HuFMhSignalVal3 31 "Reserved" 30 "Reserved" 29 "Reserved" 28 "Reserved" 27 "Reserved" 26 "Reserved" 25 "Reserved" 24 "Possible value selected is 240" 23 "Possible value selected is 230" 22 "Possible value selected is 220" 21 "Possible value selected is 210" 20 "Possible value selected is 200" 19 "Possible value selected is 190" 18 "Possible value selected is 180" 17 "Possible value selected is 170" 16 "Possible value selected is 160" 15 "Possible value selected is 150" 14 "Possible value selected is 140" 13 "Possible value selected is 130" 12 "Possible value selected is 120" 11 "Possible value selected is 110" 10 "Possible value selected is 100" 9 "Possible value selected is 90" 8 "Possible value selected is 80" 7 "Possible value selected is 70" 6 "Possible value selected is 60" 5 "Possible value selected is 50" 4 "Possible value selected is 40" 3 "Possible value selected is 30" 2 "Possible value selected is 20" 1 "Possible value selected is 10" 0 "Possible value selected is 0" ;
VAL_ 506 BCmFactorySettingReq 1 "Restored Factory Settings" 0 "Current Settings" ;
VAL_ 506 HuApproachLampSignalVal1 31 "Reserved" 30 "Reserved" 29 "Reserved" 28 "Reserved" 27 "Reserved" 26 "Reserved" 25 "Reserved" 24 "Possible value selected is 240" 23 "Possible value selected is 230" 22 "Possible value selected is 220" 21 "Possible value selected is 210" 20 "Possible value selected is 200" 19 "Possible value selected is 190" 18 "Possible value selected is 180" 17 "Possible value selected is 170" 16 "Possible value selected is 160" 15 "Possible value selected is 150" 14 "Possible value selected is 140" 13 "Possible value selected is 130" 12 "Possible value selected is 120" 11 "Possible value selected is 110" 10 "Possible value selected is 100" 9 "Possible value selected is 90" 8 "Possible value selected is 80" 7 "Possible value selected is 70" 6 "Possible value selected is 60" 5 "Possible value selected is 50" 4 "Possible value selected is 40" 3 "Possible value selected is 30" 2 "Possible value selected is 20" 1 "Possible value selected is 10" 0 "Possible value selected is 0" ;
VAL_ 506 HuDRLActiveSignalVal 1 "Active value for DRL feature is Enabled" 0 "Active value for DRL feature is Disabled" ;
VAL_ 506 HuQueryInfo 3 "HU query to BCM for sending UCS data" 2 "HU sends user intervened data to BCM" 1 "HU Acknowledges the UCS data sent by BCM." 0 "Reserved" ;
VAL_ 506 HuApproachLampSignalVal2 31 "Reserved" 30 "Reserved" 29 "Reserved" 28 "Reserved" 27 "Reserved" 26 "Reserved" 25 "Reserved" 24 "Possible value selected is 240" 23 "Possible value selected is 230" 22 "Possible value selected is 220" 21 "Possible value selected is 210" 20 "Possible value selected is 200" 19 "Possible value selected is 190" 18 "Possible value selected is 180" 17 "Possible value selected is 170" 16 "Possible value selected is 160" 15 "Possible value selected is 150" 14 "Possible value selected is 140" 13 "Possible value selected is 130" 12 "Possible value selected is 120" 11 "Possible value selected is 110" 10 "Possible value selected is 100" 9 "Possible value selected is 90" 8 "Possible value selected is 80" 7 "Possible value selected is 70" 6 "Possible value selected is 60" 5 "Possible value selected is 50" 4 "Possible value selected is 40" 3 "Possible value selected is 30" 2 "Possible value selected is 20" 1 "Possible value selected is 10" 0 "Possible value selected is 0" ;
VAL_ 506 HuApproachLampSignalVal3 31 "Reserved" 30 "Reserved" 29 "Reserved" 28 "Reserved" 27 "Reserved" 26 "Reserved" 25 "Reserved" 24 "Possible value selected is 240" 23 "Possible value selected is 230" 22 "Possible value selected is 220" 21 "Possible value selected is 210" 20 "Possible value selected is 200" 19 "Possible value selected is 190" 18 "Possible value selected is 180" 17 "Possible value selected is 170" 16 "Possible value selected is 160" 15 "Possible value selected is 150" 14 "Possible value selected is 140" 13 "Possible value selected is 130" 12 "Possible value selected is 120" 11 "Possible value selected is 110" 10 "Possible value selected is 100" 9 "Possible value selected is 90" 8 "Possible value selected is 80" 7 "Possible value selected is 70" 6 "Possible value selected is 60" 5 "Possible value selected is 50" 4 "Possible value selected is 40" 3 "Possible value selected is 30" 2 "Possible value selected is 20" 1 "Possible value selected is 10" 0 "Possible value selected is 0" ;
VAL_ 508 HuMoodLightAllAreaActiveValue 1 "ON" 0 "OFF" ;
VAL_ 508 HuMoodLightIllumSelActiveValue 7 "Reserved" 6 "Reserved" 5 "Level 5 Intensity" 4 "Level 4 Intensity" 3 "Level 3 Intensity" 2 "Level 2 Intensity" 1 "Level 1 Intensity" 0 "Reserved" ;
VAL_ 508 HuMoodLightActiveColourValue 15 "Cyan Blue" 14 "Teal Green" 13 "French Lime" 12 "Gold Yellow" 11 "Tuscan Red" 10 "Aero Blue" 9 "Hot Magenta" 8 "Purple Taupe" 7 "Ruby (Red)" 6 "Fluorescent Green" 5 "Orange" 4 "Purple" 3 "Ivory (Off White)" 2 "Polar(Bright White)" 1 "Cool Blue" 0 "Ice Blue" ;
VAL_ 508 HuMoodLightRearAreaActiveValue 1 "ON" 0 "OFF" ;
VAL_ 508 HuMoodLightFrontRHAreaActiveValu 1 "ON" 0 "OFF" ;
VAL_ 508 HuMoodLightFloorConsoleAreaActiv 1 "ON" 0 "OFF" ;
VAL_ 508 HuMoodLightData 3 "Reserved" 2 "HU sends Mood Light data to BCM" 1 "HU Acknowledges the Mood Light data sent by BCM" 0 "Reserved" ;
VAL_ 508 HuMoodLightIllumPossibleLevels 7 "Reserved" 6 "Reserved" 5 "Intensity5" 4 "Intensity4" 3 "Intensity3" 2 "Intensity2" 1 "Intensity1" 0 "Reserved" ;
VAL_ 508 HuMoodLightHotMagentaColorSelOnH 1 "Present" 0 "Not Present" ;
VAL_ 508 HuMoodLightGoldYellowColorSelOnH 1 "Present" 0 "Not Present" ;
VAL_ 508 HuMoodLightFrenchLimeColorSelOnH 1 "Present" 0 "Not Present" ;
VAL_ 508 HuMoodLightFrontLHAreaActiveValu 1 "ON" 0 "OFF" ;
VAL_ 508 HuMoodLightPossibleModes 3 "AUTO, OFF, ON" 2 "OFF, ON" 1 "No Mode selection" 0 "Reserved" ;
VAL_ 508 HuMoodLightActiveModeValue 3 "Reserved" 2 "ON" 1 "OFF" 0 "AUTO" ;
VAL_ 508 HuMoodLightPolarBrightWhiteColor 1 "Present" 0 "Not Present" ;
VAL_ 508 HuMoodLightAeroBlueColorSelOnHU 1 "Present" 0 "Not Present" ;
VAL_ 508 HuMoodLightPurpleColorSelOnHU 1 "Present" 0 "Not Present" ;
VAL_ 508 HuMoodLightFluorescentGreenColor 1 "Present" 0 "Not Present" ;
VAL_ 508 HuMoodLightCyanBlueColorSelOnHU 1 "Present" 0 "Not Present" ;
VAL_ 508 HuMoodLightCoolBlueColorSelOnHU 1 "Present" 0 "Not Present" ;
VAL_ 508 HuMoodLightIvoryOFFWhiteColorSel 1 "Present" 0 "Not Present" ;
VAL_ 508 HuMoodLightIceBlueColorSelOnHU 1 "Present" 0 "Not Present" ;
VAL_ 508 HuMoodLightTuscanRedColorSelOnHU 1 "Present" 0 "Not Present" ;
VAL_ 508 HuMoodLightTealGreenColorSelOnHU 1 "Present" 0 "Not Present" ;
VAL_ 508 HuMoodLightRubyRedColorSelOnHU 1 "Present" 0 "Not Present" ;
VAL_ 508 HuMoodLightOrangeColorSelOnHU 1 "Present" 0 "Not Present" ;
VAL_ 508 HuMoodLightPurpleTaupeSelOnHU 1 "Present" 0 "Not Present" ;
